VERSION "HIPBNNNYNNNNNNNNNNNNNNNNNNNNNNNNNNYYNNNNNN/4>%%%/4/'%**4NNN///"

NS_ :

BS_:

BU_: ADC BDF BDL BDR BGW CDC DDM VNC Vector_XXX

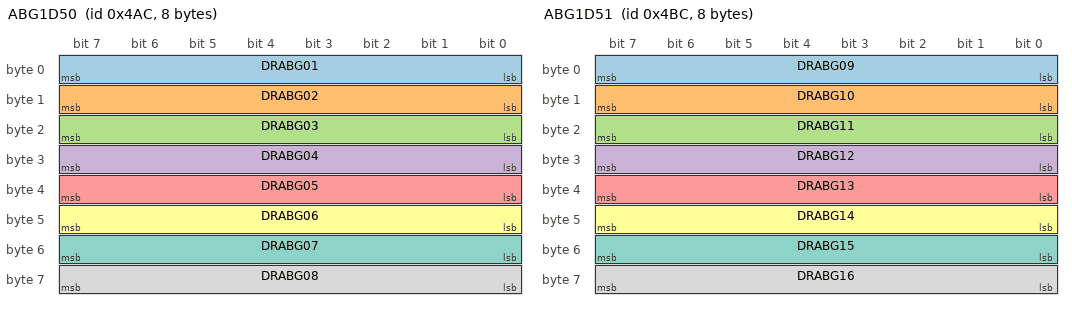
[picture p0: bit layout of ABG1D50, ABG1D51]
BO_ 1196 ABG1D50: 8 DDM
 SG_ DRABG01 : 7|8@0+ (1,0) [0|0] "-"  CDC
 SG_ DRABG02 : 15|8@0+ (1,0) [0|0] "-"  CDC
 SG_ DRABG03 : 23|8@0+ (1,0) [0|0] "-"  CDC
 SG_ DRABG04 : 31|8@0+ (1,0) [0|0] "-"  CDC
 SG_ DRABG05 : 39|8@0+ (1,0) [0|0] "-"  CDC
 SG_ DRABG06 : 47|8@0+ (1,0) [0|0] "-"  CDC
 SG_ DRABG07 : 55|8@0+ (1,0) [0|0] "-"  CDC
 SG_ DRABG08 : 63|8@0+ (1,0) [0|0] "-"  CDC

BO_ 1212 ABG1D51: 8 DDM
 SG_ DRABG09 : 7|8@0+ (1,0) [0|0] "-"  CDC
 SG_ DRABG10 : 15|8@0+ (1,0) [0|0] "-"  CDC
 SG_ DRABG11 : 23|8@0+ (1,0) [0|0] "-"  CDC
 SG_ DRABG12 : 31|8@0+ (1,0) [0|0] "-"  CDC
 SG_ DRABG13 : 39|8@0+ (1,0) [0|0] "-"  CDC
 SG_ DRABG14 : 47|8@0+ (1,0) [0|0] "-"  CDC
 SG_ DRABG15 : 55|8@0+ (1,0) [0|0] "-"  CDC
 SG_ DRABG16 : 63|8@0+ (1,0) [0|0] "-"  CDC

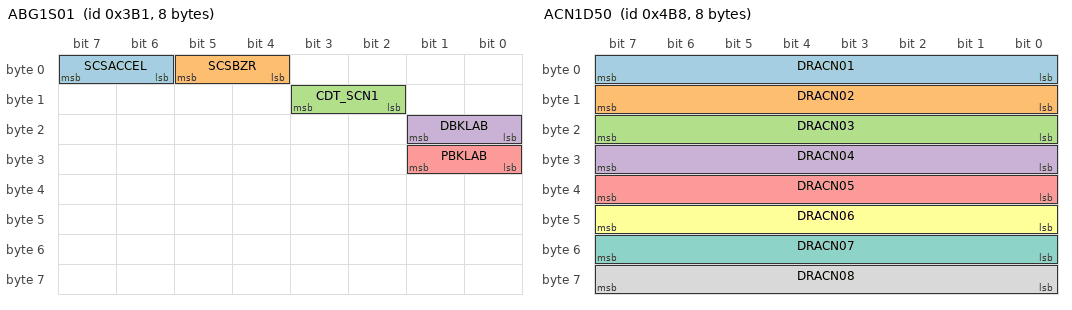
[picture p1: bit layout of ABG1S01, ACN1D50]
BO_ 945 ABG1S01: 8 DDM
 SG_ SCSACCEL : 7|2@0+ (1,0) [0|0] "-"  BDL,BGW,CDC
 SG_ SCSBZR : 5|2@0+ (1,0) [0|0] "-"  BDL,BGW,CDC
 SG_ CDT_SCN1 : 11|2@0+ (1,0) [0|0] "-"  BDL,BGW,CDC
 SG_ DBKLAB : 17|2@0+ (1,0) [0|0] "-"  BDL,BGW,CDC
 SG_ PBKLAB : 25|2@0+ (1,0) [0|0] "-"  BDL,BGW,CDC

BO_ 1208 ACN1D50: 8 BDR
 SG_ DRACN01 : 7|8@0+ (1,0) [0|0] "-"  CDC
 SG_ DRACN02 : 15|8@0+ (1,0) [0|0] "-"  CDC
 SG_ DRACN03 : 23|8@0+ (1,0) [0|0] "-"  CDC
 SG_ DRACN04 : 31|8@0+ (1,0) [0|0] "-"  CDC
 SG_ DRACN05 : 39|8@0+ (1,0) [0|0] "-"  CDC
 SG_ DRACN06 : 47|8@0+ (1,0) [0|0] "-"  CDC
 SG_ DRACN07 : 55|8@0+ (1,0) [0|0] "-"  CDC
 SG_ DRACN08 : 63|8@0+ (1,0) [0|0] "-"  CDC

BO_ 929 ACN1S03: 8 BDR
 SG_ O_STG_F : 31|2@0+ (1,0) [0|0] "-"  BDL,BGW,CDC
 SG_ AC_CDSP : 34|3@0+ (1,0) [0|0] "-"  BDL,BGW,CDC

BO_ 897 ACN1S04: 32 BDR
 SG_ R_ACCALL : 7|1@0+ (1,0) [0|0] "-"  BGW,CDC
 SG_ R_AC_WNG : 6|1@0+ (1,0) [0|0] "-"  BGW,CDC
 SG_ R_SW_CON : 5|1@0+ (1,0) [0|0] "-"  BGW,CDC
 SG_ I_RA_AUT : 3|1@0+ (1,0) [0|0] "-"  BGW,CDC
 SG_ I_RA_AC : 2|1@0+ (1,0) [0|0] "-"  BGW,CDC
 SG_ I_RA_LO : 1|1@0+ (1,0) [0|0] "-"  BGW,CDC
 SG_ I_RA_HI : 0|1@0+ (1,0) [0|0] "-"  BGW,CDC
 SG_ I_AUTO_D : 15|1@0+ (1,0) [0|0] "-"  BGW,CDC
 SG_ I_AUTO_P : 14|1@0+ (1,0) [0|0] "-"  BGW,CDC
 SG_ I_DEF : 13|1@0+ (1,0) [0|0] "-"  BGW,CDC
 SG_ I_RRDEF : 12|1@0+ (1,0) [0|0] "-"  BGW,CDC
 SG_ I_RFAUT : 11|1@0+ (1,0) [0|0] "-"  BGW,CDC
 SG_ I_REC : 10|1@0+ (1,0) [0|0] "-"  BGW,CDC
 SG_ I_FRS : 9|1@0+ (1,0) [0|0] "-"  BGW,CDC
 SG_ I_AC : 8|1@0+ (1,0) [0|0] "-"  BGW,CDC
 SG_ I_MHTR : 23|1@0+ (1,0) [0|0] "-"  BGW,CDC
 SG_ I_WIPD : 22|1@0+ (1,0) [0|0] "-"  BGW,CDC
 SG_ I_DUSY : 21|1@0+ (1,0) [0|0] "-"  BGW,CDC
 SG_ I_SWNG : 20|1@0+ (1,0) [0|0] "-"  BGW,CDC
 SG_ I_BLW_F : 19|4@0+ (1,0) [0|0] "-"  BGW,CDC
 SG_ I_OAUT_D : 31|1@0+ (1,0) [0|0] "-"  BGW,CDC
 SG_ I_OLET_D : 30|3@0+ (1,0) [0|0] "-"  BGW,CDC
 SG_ I_OAUT_P : 27|1@0+ (1,0) [0|0] "-"  BGW,CDC
 SG_ I_OLET_P : 26|3@0+ (1,0) [0|0] "-"  BGW,CDC
 SG_ ST_BMN_F : 39|1@0+ (1,0) [0|0] "-"  BGW,CDC
 SG_ I_CONCEN : 38|1@0+ (1,0) [0|0] "-"  BGW,CDC
 SG_ I_NANOE : 37|1@0+ (1,0) [0|0] "-"  BGW,CDC
 SG_ I_CONCIE : 35|1@0+ (1,0) [0|0] "-"  BGW,CDC
 SG_ I_BLWCUS : 34|3@0+ (1,0) [0|0] "-"  BGW,CDC
 SG_ I_AIRPR : 47|1@0+ (1,0) [0|0] "-"  BGW,CDC
 SG_ I_PLSM : 45|2@0+ (1,0) [0|0] "-"  BGW,CDC
 SG_ I_KAFUN : 43|1@0+ (1,0) [0|0] "-"  BGW,CDC
 SG_ R_ONSCRN : 40|1@0+ (1,0) [0|0] "-"  BGW,CDC
 SG_ I_OLET_I : 55|2@0+ (1,0) [0|0] "-"  BGW,CDC
 SG_ I_PLSYNC : 63|3@0+ (1,0) [0|0] "-"  BGW,CDC
 SG_ I_RFAUTT : 60|1@0+ (1,0) [0|0] "-"  BGW,CDC
 SG_ R_SFLOWS : 59|2@0+ (1,0) [0|0] "-"  BGW,CDC
 SG_ I_ACAUTO : 57|1@0+ (1,0) [0|0] "-"  BGW,CDC
 SG_ R_ECODSP : 56|1@0+ (1,0) [0|0] "-"  BGW,CDC
 SG_ SL_ACDSP : 71|4@0+ (1,0) [0|0] "-"  BGW,CDC
 SG_ SL_DUSY : 67|1@0+ (1,0) [0|0] "-"  BGW,CDC
 SG_ SL_DFRAD : 66|1@0+ (1,0) [0|0] "-"  BGW,CDC
 SG_ SL_CIF : 65|1@0+ (1,0) [0|0] "-"  BGW,CDC
 SG_ SL_BLW_F : 64|1@0+ (1,0) [0|0] "-"  BGW,CDC
 SG_ SL_SRLVL : 79|3@0+ (1,0) [0|0] "-"  BGW,CDC
 SG_ SL_RR_IH : 76|1@0+ (1,0) [0|0] "-"  BGW,CDC
 SG_ SL_RAUTO : 75|1@0+ (1,0) [0|0] "-"  BGW,CDC
 SG_ SL_BLW_R : 74|1@0+ (1,0) [0|0] "-"  BGW,CDC
 SG_ SL_DST : 73|2@0+ (1,0) [0|0] "-"  BGW,CDC
 SG_ SL_WIPD : 87|1@0+ (1,0) [0|0] "-"  BGW,CDC
 SG_ SL_MRHT : 86|1@0+ (1,0) [0|0] "-"  BGW,CDC
 SG_ SL_AIRP : 85|1@0+ (1,0) [0|0] "-"  BGW,CDC
 SG_ SL_PFRAD : 84|1@0+ (1,0) [0|0] "-"  BGW,CDC
 SG_ SL_PLSM : 83|1@0+ (1,0) [0|0] "-"  BGW,CDC
 SG_ SL_KAFUN : 82|1@0+ (1,0) [0|0] "-"  BGW,CDC
 SG_ SL_SWNG : 81|1@0+ (1,0) [0|0] "-"  BGW,CDC
 SG_ ST_CN_OK : 80|1@0+ (1,0) [0|0] "-"  BGW,CDC
 SG_ SL_FSVTP : 95|2@0+ (1,0) [0|0] "-"  BGW,CDC
 SG_ SL_FSTYP : 93|3@0+ (1,0) [0|0] "-"  BGW,CDC
 SG_ SL_NANOE : 90|1@0+ (1,0) [0|0] "-"  BGW,CDC
 SG_ SL_RSEAT : 89|1@0+ (1,0) [0|0] "-"  BGW,CDC
 SG_ SL_SFLOW : 88|1@0+ (1,0) [0|0] "-"  BGW,CDC
 SG_ SL_ACST : 103|6@0+ (1,0) [0|0] "-"  BGW,CDC
 SG_ SL_AC_AM : 97|1@0+ (1,0) [0|0] "-"  BGW,CDC
 SG_ SL_RBLW : 96|1@0+ (1,0) [0|0] "-"  BGW,CDC
 SG_ SL_ROFF : 111|1@0+ (1,0) [0|0] "-"  BGW,CDC
 SG_ SL_BLCUS : 110|1@0+ (1,0) [0|0] "-"  BGW,CDC
 SG_ SL_ACECO : 108|1@0+ (1,0) [0|0] "-"  BGW,CDC
 SG_ SL_RFSW : 107|1@0+ (1,0) [0|0] "-"  BGW,CDC
 SG_ SL_CONCI : 106|1@0+ (1,0) [0|0] "-"  BGW,CDC
 SG_ SL_NECK : 105|1@0+ (1,0) [0|0] "-"  BGW,CDC
 SG_ SL_RACIH : 104|1@0+ (1,0) [0|0] "-"  BGW,CDC
 SG_ SL_ZOSY : 119|3@0+ (1,0) [0|0] "-"  BGW,CDC
 SG_ SL_STHAT : 116|1@0+ (1,0) [0|0] "-"  BGW,CDC
 SG_ SL_3RD_S : 115|1@0+ (1,0) [0|0] "-"  BGW,CDC
 SG_ SL_RSBLW : 114|1@0+ (1,0) [0|0] "-"  BGW,CDC
 SG_ SL_STR_H : 113|2@0+ (1,0) [0|0] "-"  BGW,CDC
 SG_ SL_NAVI : 127|1@0+ (1,0) [0|0] "-"  BGW,CDC
 SG_ SL_FSEAT : 125|2@0+ (1,0) [0|0] "-"  BGW,CDC
 SG_ I_AUT_RR : 135|1@0+ (1,0) [0|0] "-"  BGW,CDC
 SG_ I_AUT_RL : 134|1@0+ (1,0) [0|0] "-"  BGW,CDC
 SG_ I_CNT_IH : 133|1@0+ (1,0) [0|0] "-"  BGW,CDC
 SG_ I_RAUTO : 132|1@0+ (1,0) [0|0] "-"  BGW,CDC
 SG_ ST_BMN_R : 131|1@0+ (1,0) [0|0] "-"  BGW,CDC
 SG_ I_RBLCUS : 130|3@0+ (1,0) [0|0] "-"  BGW,CDC
 SG_ I_OAUTRL : 141|1@0+ (1,0) [0|0] "-"  BGW,CDC
 SG_ I_OAUTRR : 140|1@0+ (1,0) [0|0] "-"  BGW,CDC
 SG_ I_BLW_R : 139|4@0+ (1,0) [0|0] "-"  BGW,CDC
 SG_ R_RONSCR : 151|1@0+ (1,0) [0|0] "-"  BGW,CDC
 SG_ I_OLT_RR : 150|3@0+ (1,0) [0|0] "-"  BGW,CDC
 SG_ I_RACON : 147|1@0+ (1,0) [0|0] "-"  BGW,CDC
 SG_ I_OLT_RL : 146|3@0+ (1,0) [0|0] "-"  BGW,CDC
 SG_ B_DCMOD1 : 175|1@0+ (1,0) [0|0] "-"  BGW,CDC
 SG_ B_DCMOD2 : 174|3@0+ (1,0) [0|0] "-"  BGW,CDC
 SG_ B_DCMOD3 : 171|4@0+ (1,0) [0|0] "-"  BGW,CDC
 SG_ I_TMP_RR : 183|8@0+ (1,0) [0|0] "-"  BGW,CDC
 SG_ I_TMP_RL : 191|8@0+ (1,0) [0|0] "-"  BGW,CDC
 SG_ I_BCOLRL : 199|2@0+ (1,0) [0|0] "-"  BGW,CDC
 SG_ I_BCOLRR : 197|2@0+ (1,0) [0|0] "-"  BGW,CDC
 SG_ I_BCOLPA : 195|2@0+ (1,0) [0|0] "-"  BGW,CDC
 SG_ I_BCOLDR : 193|2@0+ (1,0) [0|0] "-"  BGW,CDC
 SG_ M_OLT_PA : 205|3@0+ (1,0) [0|0] "-"  BGW,CDC
 SG_ M_OLT_DR : 202|3@0+ (1,0) [0|0] "-"  BGW,CDC
 SG_ M_OLT_RL : 213|3@0+ (1,0) [0|0] "-"  BGW,CDC
 SG_ M_OLT_RR : 210|3@0+ (1,0) [0|0] "-"  BGW,CDC
 SG_ RL_SBL : 223|2@0+ (1,0) [0|0] "-"  BGW,CDC
 SG_ RL_SHL : 221|2@0+ (1,0) [0|0] "-"  BGW,CDC
 SG_ RR_SBL : 219|2@0+ (1,0) [0|0] "-"  BGW,CDC
 SG_ RR_SHL : 217|2@0+ (1,0) [0|0] "-"  BGW,CDC
 SG_ I_STHLVL : 231|2@0+ (1,0) [0|0] "-"  BGW,CDC
 SG_ I_SAUTRL : 229|1@0+ (1,0) [0|0] "-"  BGW,CDC
 SG_ I_SAUTRR : 228|1@0+ (1,0) [0|0] "-"  BGW,CDC
 SG_ R_DSP_SH : 227|1@0+ (1,0) [0|0] "-"  BGW,CDC
 SG_ I_SAUT_P : 226|1@0+ (1,0) [0|0] "-"  BGW,CDC
 SG_ I_SAUT_D : 225|1@0+ (1,0) [0|0] "-"  BGW,CDC
 SG_ I_STHAUT : 224|1@0+ (1,0) [0|0] "-"  BGW,CDC
 SG_ PF_SBL : 239|2@0+ (1,0) [0|0] "-"  BGW,CDC
 SG_ PF_SHL : 237|2@0+ (1,0) [0|0] "-"  BGW,CDC
 SG_ DF_SBL : 235|2@0+ (1,0) [0|0] "-"  BGW,CDC
 SG_ DF_SHL : 233|2@0+ (1,0) [0|0] "-"  BGW,CDC
 SG_ DF_NHL : 247|3@0+ (1,0) [0|0] "-"  BGW,CDC
 SG_ PF_NHL : 244|3@0+ (1,0) [0|0] "-"  BGW,CDC
 SG_ I_NH_LIM : 241|2@0+ (1,0) [0|0] "-"  BGW,CDC
 SG_ I_NAUT_D : 255|2@0+ (1,0) [0|0] "-"  BGW,CDC
 SG_ I_NAUT_P : 253|2@0+ (1,0) [0|0] "-"  BGW,CDC

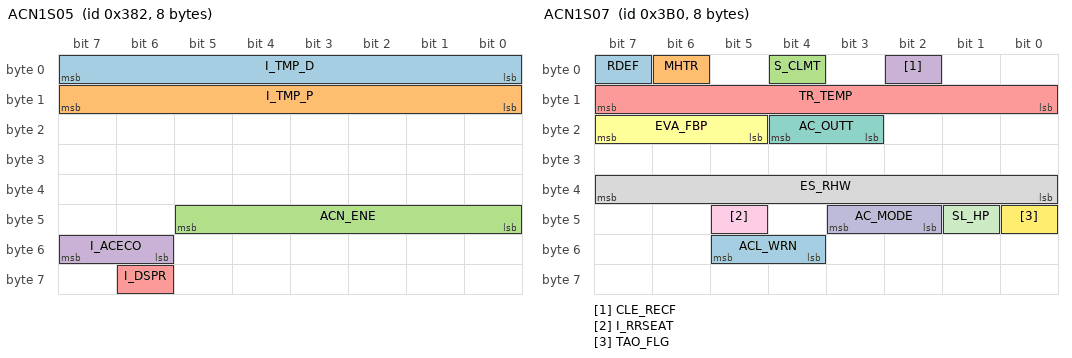
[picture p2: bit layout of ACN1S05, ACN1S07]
BO_ 898 ACN1S05: 8 BDR
 SG_ I_TMP_D : 7|8@0+ (1,0) [0|0] "-"  BGW,CDC
 SG_ I_TMP_P : 15|8@0+ (1,0) [0|0] "-"  BGW,CDC
 SG_ ACN_ENE : 45|6@0+ (100,0) [0|0] "W"  BGW,CDC
 SG_ I_ACECO : 55|2@0+ (1,0) [0|0] "-"  BGW,CDC
 SG_ I_DSPR : 62|1@0+ (1,0) [0|0] "-"  BGW,CDC

BO_ 944 ACN1S07: 8 BDR
 SG_ RDEF : 7|1@0+ (1,0) [0|0] "-"  BGW,CDC
 SG_ MHTR : 6|1@0+ (1,0) [0|0] "-"  BGW,CDC
 SG_ S_CLMT : 4|1@0+ (1,0) [0|0] "-"  BGW,CDC
 SG_ CLE_RECF : 2|1@0+ (1,0) [0|0] "-"  BGW,CDC
 SG_ TR_TEMP : 15|8@0+ (0.25,-6.5) [0|0] "degC"  BGW,CDC
 SG_ EVA_FBP : 23|3@0+ (1,0) [0|0] "-"  BGW,CDC
 SG_ AC_OUTT : 20|2@0+ (1,0) [0|0] "-"  BGW,CDC
 SG_ ES_RHW : 39|8@0+ (1,0) [0|0] "%"  BGW,CDC
 SG_ I_RRSEAT : 45|1@0+ (1,0) [0|0] "-"  BGW,CDC
 SG_ AC_MODE : 43|2@0+ (1,0) [0|0] "-"  BGW,CDC
 SG_ SL_HP : 41|1@0+ (1,0) [0|0] "-"  BGW,CDC
 SG_ TAO_FLG : 40|1@0+ (1,0) [0|0] "-"  BGW,CDC
 SG_ ACL_WRN : 53|2@0+ (1,0) [0|0] "-"  BGW,CDC

BO_ 1031 ACN1S15: 8 BDR
 SG_ TRTEMP_P : 23|8@0+ (0.25,-6.5) [0|0] "degC"  CDC
 SG_ I_BLWF_P : 39|4@0+ (1,0) [0|0] "-"  CDC,DDM

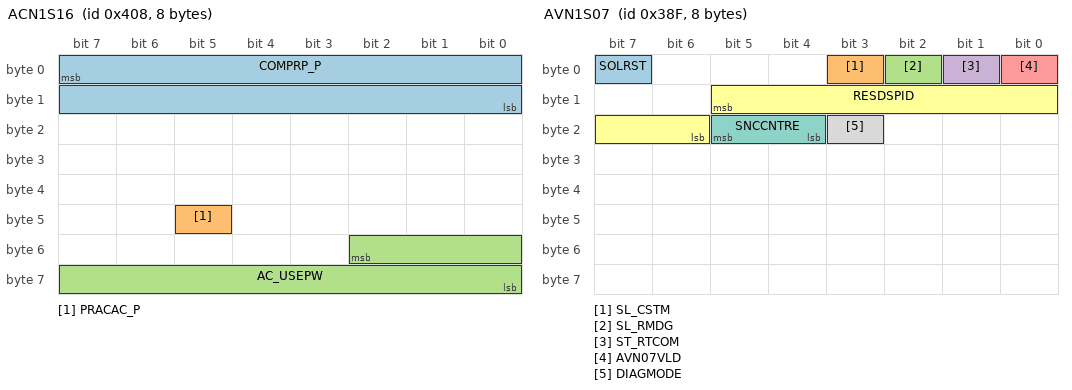
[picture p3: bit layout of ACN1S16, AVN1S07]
BO_ 1032 ACN1S16: 8 BDR
 SG_ COMPRP_P : 7|16@0+ (1,0) [0|0] "rpm"  CDC
 SG_ PRACAC_P : 45|1@0+ (1,0) [0|0] "-"  CDC
 SG_ AC_USEPW : 50|11@0+ (10,0) [0|0] "W"  CDC

BO_ 852 ACN1S22: 32 BDR
 SG_ I_EXT : 7|1@0+ (1,0) [0|0] "-"  BGW,CDC
 SG_ PM_REN : 6|1@0+ (1,0) [0|0] "-"  BGW,CDC
 SG_ PM_ST : 5|2@0+ (1,0) [0|0] "-"  BGW,CDC
 SG_ I_PM : 3|1@0+ (1,0) [0|0] "-"  BGW,CDC
 SG_ SL_PM : 2|1@0+ (1,0) [0|0] "-"  BGW,CDC
 SG_ I_PMD : 1|10@0+ (1,0) [0|0] "ug/m3"  BGW,CDC
 SG_ I_FRC2 : 23|4@0+ (1,0) [0|0] "-"  BGW,CDC
 SG_ I_FRC1 : 19|4@0+ (1,0) [0|0] "-"  BGW,CDC
 SG_ I_RFRS : 31|2@0+ (1,0) [0|0] "-"  BGW,CDC
 SG_ I_WFRS : 29|2@0+ (1,0) [0|0] "-"  BGW,CDC
 SG_ I_FRIS : 27|2@0+ (1,0) [0|0] "-"  BGW,CDC
 SG_ SL_FR : 25|2@0+ (1,0) [0|0] "-"  BGW,CDC
 SG_ ST_ACAGT : 39|3@0+ (1,0) [0|0] "-"  BGW,CDC
 SG_ I_FRST : 36|1@0+ (1,0) [0|0] "-"  BGW,CDC
 SG_ I_RFRC : 35|2@0+ (1,0) [0|0] "-"  BGW,CDC
 SG_ I_WFRC : 33|2@0+ (1,0) [0|0] "-"  BGW,CDC
 SG_ SL_TCS : 47|1@0+ (1,0) [0|0] "-"  BGW,CDC
 SG_ SL_EXT : 46|1@0+ (1,0) [0|0] "-"  BGW,CDC
 SG_ SL_ACAGT : 45|2@0+ (1,0) [0|0] "-"  BGW,CDC
 SG_ ST_EMEN : 43|2@0+ (1,0) [0|0] "-"  BGW,CDC
 SG_ ST_AWKEN : 41|2@0+ (1,0) [0|0] "-"  BGW,CDC
 SG_ SL_RSTYP : 55|3@0+ (1,0) [0|0] "-"  BGW,CDC
 SG_ SL_SYNC : 52|2@0+ (1,0) [0|0] "-"  BGW,CDC
 SG_ TCS_ST : 50|3@0+ (1,0) [0|0] "-"  BGW,CDC
 SG_ R_RFPHBT : 58|1@0+ (1,0) [0|0] "-"  BGW,CDC
 SG_ SL_RSVTP : 57|2@0+ (1,0) [0|0] "-"  BGW,CDC
 SG_ FG_CH1_L : 71|7@0+ (1,0) [0|0] "-"  BGW,CDC
 SG_ FG_CH1_D : 64|1@0+ (1,0) [0|0] "-"  BGW,CDC
 SG_ FG_CH1_T : 78|7@0+ (1,0) [0|0] "-"  BGW,CDC
 SG_ FG_CH2_L : 87|7@0+ (1,0) [0|0] "-"  BGW,CDC
 SG_ FG_CH2_D : 80|1@0+ (1,0) [0|0] "-"  BGW,CDC
 SG_ FG_CH2_T : 94|7@0+ (1,0) [0|0] "-"  BGW,CDC
 SG_ FG_CH3_L : 103|7@0+ (1,0) [0|0] "-"  BGW,CDC
 SG_ FG_CH3_D : 96|1@0+ (1,0) [0|0] "-"  BGW,CDC
 SG_ FG_CH3_T : 110|7@0+ (1,0) [0|0] "-"  BGW,CDC
 SG_ FG_UV_E : 118|1@0+ (1,0) [0|0] "-"  BGW,CDC
 SG_ FG_OV_E : 117|1@0+ (1,0) [0|0] "-"  BGW,CDC
 SG_ FG_MOT_E : 116|1@0+ (1,0) [0|0] "-"  BGW,CDC
 SG_ FG_FAN_E : 115|1@0+ (1,0) [0|0] "-"  BGW,CDC
 SG_ FG_EMP : 114|1@0+ (1,0) [0|0] "-"  BGW,CDC
 SG_ FG_CHA_E : 113|2@0+ (1,0) [0|0] "-"  BGW,CDC
 SG_ SL_FGST : 127|2@0+ (1,0) [0|0] "-"  BGW,CDC
 SG_ I_FG_PW : 125|1@0+ (1,0) [0|0] "-"  BGW,CDC
 SG_ I_FG_LVL : 124|3@0+ (1,0) [0|0] "-"  BGW,CDC
 SG_ I_FG_CH : 121|2@0+ (1,0) [0|0] "-"  BGW,CDC

BO_ 597 ACN1S25: 32 BDR
 SG_ HQ_COMP : 66|11@0+ (10,0) [0|0] "W"  CDC

BO_ 1286 ACN1S29: 32 BDR
 SG_ R_SHHTFL : 3|1@0+ (1,0) [0|0] "-"  CDC
 SG_ R_SHHTFR : 1|1@0+ (1,0) [0|0] "-"  CDC
 SG_ RSVFLDU : 22|7@0+ (1,0) [0|0] "%"  CDC
 SG_ RSVFRDU : 30|7@0+ (1,0) [0|0] "%"  CDC
 SG_ R_SHHTRL : 37|1@0+ (1,0) [0|0] "-"  CDC
 SG_ R_SHHTRR : 35|1@0+ (1,0) [0|0] "-"  CDC
 SG_ RSVRLDU : 54|7@0+ (1,0) [0|0] "%"  CDC
 SG_ RSVRRDU : 62|7@0+ (1,0) [0|0] "%"  CDC
 SG_ R_RDHRR : 70|1@0+ (1,0) [0|0] "-"  CDC
 SG_ R_RDHRL : 68|1@0+ (1,0) [0|0] "-"  CDC
 SG_ R_RDHFP : 66|1@0+ (1,0) [0|0] "-"  CDC
 SG_ R_RDHFD : 64|1@0+ (1,0) [0|0] "-"  CDC

BO_ 382 ADC1S11: 32 ADC
 SG_ RCPSYS : 2|1@0+ (1,0) [0|0] "-"  BGW,CDC

BO_ 519 ADC1S13: 32 ADC
 SG_ VCDSP_2 : 7|2@0+ (1,0) [0|0] "-"  CDC
 SG_ PCDSP_2 : 5|2@0+ (1,0) [0|0] "-"  CDC
 SG_ GCDSP_2 : 3|2@0+ (1,0) [0|0] "-"  CDC
 SG_ TRNEXIST : 1|1@0+ (1,0) [0|0] "-"  CDC
 SG_ TRNACT : 0|2@0+ (1,0) [0|0] "-"  CDC
 SG_ TRNCEO : 14|9@0+ (1,0) [0|0] "-"  CDC
 SG_ TRNED : 21|9@0+ (1,0) [0|0] "-"  CDC
 SG_ TRNEPR : 39|8@0+ (1,0) [0|0] "-"  CDC
 SG_ TRNPEPL : 47|8@0+ (1,0) [0|0] "-"  CDC
 SG_ TRNJ : 55|4@0+ (1,0) [0|0] "-"  CDC
 SG_ TRNCS : 51|1@0+ (1,0) [0|0] "-"  CDC
 SG_ TRNCN : 50|2@0+ (1,0) [0|0] "-"  CDC
 SG_ TRNCI : 48|1@0+ (1,0) [0|0] "-"  CDC
 SG_ TRNPB : 63|7@0+ (1,0) [0|0] "-"  CDC
 SG_ TRNGJ : 56|6@0+ (1,0) [0|0] "-"  CDC
 SG_ TRNME : 66|7@0+ (1,0) [0|0] "-"  CDC
 SG_ TRNMI : 75|4@0+ (1,0) [0|0] "-"  CDC
 SG_ TRNDP : 87|2@0+ (1,0) [0|0] "-"  CDC
 SG_ TRNMET1 : 85|4@0+ (1,0) [0|0] "-"  CDC
 SG_ TRNMET2 : 81|4@0+ (1,0) [0|0] "-"  CDC
 SG_ TRNJP : 93|4@0+ (1,0) [0|0] "-"  CDC
 SG_ TRNVUR : 103|8@0+ (1,0) [0|0] "-"  CDC
 SG_ TRNJPE : 111|4@0+ (1,0) [0|0] "-"  CDC
 SG_ TRNMMDIS : 107|4@0+ (1,0) [0|0] "-"  CDC
 SG_ TRNBUT : 119|1@0+ (1,0) [0|0] "-"  CDC
 SG_ TRNVUEX : 118|1@0+ (1,0) [0|0] "-"  CDC
 SG_ TRNAS : 135|4@0+ (1,0) [0|0] "-"  CDC
 SG_ TRNCI1 : 168|4@0+ (1,0) [0|0] "-"  CDC
 SG_ TRNFE : 189|1@0+ (1,0) [0|0] "-"  CDC
 SG_ TRNSEI : 188|2@0+ (1,0) [0|0] "-"  CDC
 SG_ TRNPC1 : 186|1@0+ (1,0) [0|0] "-"  CDC
 SG_ TRNPC2 : 185|1@0+ (1,0) [0|0] "-"  CDC
 SG_ TRNPC3 : 184|1@0+ (1,0) [0|0] "-"  CDC
 SG_ TRNPC4 : 199|1@0+ (1,0) [0|0] "-"  CDC
 SG_ TRNPC5 : 198|1@0+ (1,0) [0|0] "-"  CDC
 SG_ TRNPC6 : 197|1@0+ (1,0) [0|0] "-"  CDC
 SG_ TRNPC7 : 196|1@0+ (1,0) [0|0] "-"  CDC
 SG_ TRNPC8 : 195|1@0+ (1,0) [0|0] "-"  CDC
 SG_ TRNSE1 : 194|1@0+ (1,0) [0|0] "-"  CDC
 SG_ TRNSE2 : 193|1@0+ (1,0) [0|0] "-"  CDC
 SG_ TRNSE3 : 192|1@0+ (1,0) [0|0] "-"  CDC
 SG_ TRNSE4 : 207|1@0+ (1,0) [0|0] "-"  CDC
 SG_ TRNSE5 : 206|1@0+ (1,0) [0|0] "-"  CDC
 SG_ TRNSE6 : 205|1@0+ (1,0) [0|0] "-"  CDC
 SG_ TRNSE7 : 204|1@0+ (1,0) [0|0] "-"  CDC
 SG_ TRNSE8 : 203|1@0+ (1,0) [0|0] "-"  CDC
 SG_ TRNISR : 202|1@0+ (1,0) [0|0] "-"  CDC
 SG_ TRNESR : 201|1@0+ (1,0) [0|0] "-"  CDC
 SG_ TRNHDR : 200|1@0+ (1,0) [0|0] "-"  CDC
 SG_ TRNMR1 : 215|4@0+ (1,0) [0|0] "-"  CDC
 SG_ TRNMR2 : 211|4@0+ (1,0) [0|0] "-"  CDC

BO_ 523 ADC1S23: 32 ADC
 SG_ AMCONPVM : 7|2@0+ (1,0) [0|0] "-"  CDC
 SG_ DRADCABN : 15|8@0+ (1,0) [0|0] "-"  CDC
 SG_ DRADCTMP : 21|1@0+ (1,0) [0|0] "-"  CDC

BO_ 841 ADC1S30: 8 ADC
 SG_ ETHWU_12 : 6|1@0+ (1,0) [0|0] "-"  BGW,CDC

BO_ 448 ADC1S31: 32 ADC
 SG_ APPMD2 : 2|3@0+ (1,0) [0|0] "-"  CDC

BO_ 526 ADU1S07: 32 ADC
 SG_ DIS_ALR2 : 7|1@0+ (1,0) [0|0] "-"  CDC
 SG_ DISSUIEX : 6|1@0+ (1,0) [0|0] "-"  CDC
 SG_ DISSUIST : 5|1@0+ (1,0) [0|0] "-"  CDC
 SG_ SW_ALRT2 : 4|2@0+ (1,0) [0|0] "-"  CDC
 SG_ PLANTREQ : 2|2@0+ (1,0) [0|0] "-"  CDC
 SG_ ADOFFM1 : 15|4@0+ (1,0) [0|0] "-"  CDC
 SG_ ADOFFM2 : 11|3@0+ (1,0) [0|0] "-"  CDC
 SG_ ADOFFMET : 8|1@0+ (1,0) [0|0] "-"  CDC
 SG_ SCBOICN : 23|1@0+ (1,0) [0|0] "-"  CDC
 SG_ RCDOICN : 22|1@0+ (1,0) [0|0] "-"  CDC
 SG_ RCTAOICN : 21|1@0+ (1,0) [0|0] "-"  CDC
 SG_ SEAOICN : 20|1@0+ (1,0) [0|0] "-"  CDC
 SG_ FCTAOICN : 19|1@0+ (1,0) [0|0] "-"  CDC
 SG_ SASOICN : 18|1@0+ (1,0) [0|0] "-"  CDC
 SG_ EDSSOICN : 17|1@0+ (1,0) [0|0] "-"  CDC
 SG_ RSL_PLRQ : 31|1@0+ (1,0) [0|0] "-"  CDC
 SG_ RSR_PLRQ : 30|1@0+ (1,0) [0|0] "-"  CDC
 SG_ FSL_PLRQ : 29|1@0+ (1,0) [0|0] "-"  CDC
 SG_ FSR_PLRQ : 28|1@0+ (1,0) [0|0] "-"  CDC
 SG_ FRD_PLRQ : 27|1@0+ (1,0) [0|0] "-"  CDC
 SG_ ADISTATE : 26|3@0+ (1,0) [0|0] "-"  CDC
 SG_ SEAADIM : 39|2@0+ (1,0) [0|0] "-"  CDC
 SG_ PMARADIM : 37|2@0+ (1,0) [0|0] "-"  CDC
 SG_ RCTAADIM : 35|2@0+ (1,0) [0|0] "-"  CDC
 SG_ BSMADIM : 33|2@0+ (1,0) [0|0] "-"  CDC
 SG_ ADIEXIST : 47|1@0+ (1,0) [0|0] "-"  CDC
 SG_ FSR_BZ_C : 43|1@0+ (1,0) [0|0] "-"  CDC
 SG_ FSR_BZ_E : 42|1@0+ (1,0) [0|0] "-"  CDC
 SG_ FSL_BZ_C : 41|1@0+ (1,0) [0|0] "-"  CDC
 SG_ FSL_BZ_E : 40|1@0+ (1,0) [0|0] "-"  CDC
 SG_ RSR_BZ_C : 55|1@0+ (1,0) [0|0] "-"  CDC
 SG_ RSR_BZ_E : 54|1@0+ (1,0) [0|0] "-"  CDC
 SG_ RSL_BZ_C : 53|1@0+ (1,0) [0|0] "-"  CDC
 SG_ RSL_BZ_E : 52|1@0+ (1,0) [0|0] "-"  CDC
 SG_ DMCINDI : 51|3@0+ (1,0) [0|0] "-"  CDC
 SG_ DMCDISP : 63|6@0+ (1,0) [0|0] "-"  CDC
 SG_ DMCBZRQ : 57|2@0+ (1,0) [0|0] "-"  CDC
 SG_ ACCAVTYR : 79|3@0+ (1,0) [0|0] "-"  CDC
 SG_ ACCAVDTR : 76|3@0+ (1,0) [0|0] "-"  CDC
 SG_ ACCAVS1R : 73|2@0+ (1,0) [0|0] "-"  CDC
 SG_ ACCAVS2R : 87|1@0+ (1,0) [0|0] "-"  CDC
 SG_ ACCAVLPR : 86|3@0+ (1,0) [0|0] "-"  CDC
 SG_ ACCAVTYL : 83|3@0+ (1,0) [0|0] "-"  CDC
 SG_ ACCAVS2L : 80|1@0+ (1,0) [0|0] "-"  CDC
 SG_ ACCAVS1L : 95|2@0+ (1,0) [0|0] "-"  CDC
 SG_ ACCAVDTL : 93|3@0+ (1,0) [0|0] "-"  CDC
 SG_ ACCAVLPL : 90|3@0+ (1,0) [0|0] "-"  CDC
 SG_ ACCPPVEX : 103|1@0+ (1,0) [0|0] "-"  CDC
 SG_ ACCPPVDT : 102|3@0+ (1,0) [0|0] "-"  CDC
 SG_ ACCPPVS1 : 99|2@0+ (1,0) [0|0] "-"  CDC
 SG_ ACCPVTY : 111|3@0+ (1,0) [0|0] "-"  CDC
 SG_ ACCPVDST : 108|3@0+ (1,0) [0|0] "-"  CDC
 SG_ ACCPVST1 : 105|2@0+ (1,0) [0|0] "-"  CDC
 SG_ ACCPVST2 : 119|1@0+ (1,0) [0|0] "-"  CDC
 SG_ ACCPVST3 : 118|1@0+ (1,0) [0|0] "-"  CDC
 SG_ CACCFR1 : 117|1@0+ (1,0) [0|0] "-"  CDC
 SG_ ERMPLRST : 116|2@0+ (1,0) [0|0] "-"  CDC
 SG_ AH_SRI_C : 143|16@0+ (1,0) [0|0] "-"  CDC
 SG_ AH_IND_C : 159|3@0+ (1,0) [0|0] "-"  CDC
 SG_ AH_WTR_C : 156|3@0+ (1,0) [0|0] "-"  CDC
 SG_ BSMOICN : 153|1@0+ (1,0) [0|0] "-"  CDC

BO_ 477 ARS1S90: 8 DDM
 SG_ ARS_METD : 4|3@0+ (1,0) [0|0] "-"  CDC
 SG_ ARSEXT : 8|1@0+ (1,0) [0|0] "-"  CDC

BO_ 900 AVN1S01: 32 CDC
 SG_ RDC : 7|4@0+ (1,0) [0|0] "-"  ADC
 SG_ CONFID01 : 3|2@0+ (1,0) [0|0] "-"  ADC
 SG_ CONF : 1|2@0+ (1,0) [0|0] "-"  ADC
 SG_ LYT : 15|4@0+ (1,0) [0|0] "-"  ADC
 SG_ TNL_5H_S : 11|1@0+ (1,0) [0|0] "-"  Vector_XXX
 SG_ TNL_1T_S : 10|1@0+ (1,0) [0|0] "-"  Vector_XXX
 SG_ DRVW : 9|1@0+ (1,0) [0|0] "-"  ADC
 SG_ MWMP : 8|1@0+ (1,0) [0|0] "-"  ADC
 SG_ GRAD : 23|3@0+ (1,0) [0|0] "-"  Vector_XXX
 SG_ TNL_5T_S : 20|1@0+ (1,0) [0|0] "-"  Vector_XXX
 SG_ BRANCH : 27|4@0+ (1,0) [0|0] "-"  Vector_XXX
 SG_ TOLLGATE : 33|1@0+ (1,0) [0|0] "-"  Vector_XXX
 SG_ TUNL : 32|1@0+ (1,0) [0|0] "-"  ADC,BDL
 SG_ LEAVEOUT : 47|1@0+ (1,0) [0|0] "-"  Vector_XXX
 SG_ MRGLANE : 46|1@0+ (1,0) [0|0] "-"  Vector_XXX
 SG_ LVLANE : 45|1@0+ (1,0) [0|0] "-"  Vector_XXX

BO_ 910 AVN1S04: 8 CDC
 SG_ R_AC_DSP : 7|1@0+ (1,0) [0|0] "-"  BDL
 SG_ AVN04VLD : 5|1@0+ (1,0) [0|0] "-"  BDL
 SG_ S_ACECO : 4|1@0+ (1,0) [0|0] "-"  BDL
 SG_ S_BLW_F : 3|1@0+ (1,0) [0|0] "-"  BDL
 SG_ S_RA_AUT : 2|1@0+ (1,0) [0|0] "-"  BDL
 SG_ S_RA_OFF : 1|1@0+ (1,0) [0|0] "-"  BDL
 SG_ S_RA_MNL : 0|1@0+ (1,0) [0|0] "-"  BDL
 SG_ R_PN_TYP : 15|4@0+ (1,0) [0|0] "-"  BDL
 SG_ R_CONCIE : 11|1@0+ (1,0) [0|0] "-"  BDL
 SG_ S_CONCIE : 10|1@0+ (1,0) [0|0] "-"  BDL
 SG_ R_S_FLOW : 9|1@0+ (1,0) [0|0] "-"  BDL
 SG_ R_RFAT : 8|1@0+ (1,0) [0|0] "-"  BDL
 SG_ S_AUTO_D : 23|1@0+ (1,0) [0|0] "-"  BDL
 SG_ S_AUTO_P : 22|1@0+ (1,0) [0|0] "-"  BDL
 SG_ S_DEF : 21|1@0+ (1,0) [0|0] "-"  BDL
 SG_ S_RRDEF : 20|1@0+ (1,0) [0|0] "-"  BDL
 SG_ S_INL : 19|1@0+ (1,0) [0|0] "-"  BDL
 SG_ S_OFF_F : 18|1@0+ (1,0) [0|0] "-"  BDL
 SG_ S_SAFS : 17|1@0+ (1,0) [0|0] "-"  BDL
 SG_ S_AC : 16|1@0+ (1,0) [0|0] "-"  BDL
 SG_ S_MHTR : 31|1@0+ (1,0) [0|0] "-"  BDL
 SG_ S_WIPD : 30|1@0+ (1,0) [0|0] "-"  BDL
 SG_ S_DUSY : 29|1@0+ (1,0) [0|0] "-"  BDL
 SG_ S_SWNG : 28|1@0+ (1,0) [0|0] "-"  BDL
 SG_ S_MODE_D : 27|1@0+ (1,0) [0|0] "-"  BDL
 SG_ S_MODE_P : 26|1@0+ (1,0) [0|0] "-"  BDL
 SG_ S_BUP_F : 25|1@0+ (1,0) [0|0] "-"  BDL
 SG_ S_BDN_F : 24|1@0+ (1,0) [0|0] "-"  BDL
 SG_ S_NANOE : 39|1@0+ (1,0) [0|0] "-"  BDL
 SG_ S_OLET_D : 38|3@0+ (1,0) [0|0] "-"  BDL
 SG_ S_DSPR : 35|1@0+ (1,0) [0|0] "-"  BDL
 SG_ S_OLET_P : 34|3@0+ (1,0) [0|0] "-"  BDL
 SG_ S_TUP_D : 47|1@0+ (1,0) [0|0] "-"  BDL
 SG_ S_TDN_D : 46|1@0+ (1,0) [0|0] "-"  BDL
 SG_ S_TUP_P : 45|1@0+ (1,0) [0|0] "-"  BDL
 SG_ S_TDN_P : 44|1@0+ (1,0) [0|0] "-"  BDL
 SG_ S_PLSM : 43|1@0+ (1,0) [0|0] "-"  BDL
 SG_ S_KAFUN : 42|1@0+ (1,0) [0|0] "-"  BDL
 SG_ S_AIRPR : 41|1@0+ (1,0) [0|0] "-"  BDL
 SG_ S_O2 : 40|1@0+ (1,0) [0|0] "-"  BDL
 SG_ S_FRS : 55|1@0+ (1,0) [0|0] "-"  BDL
 SG_ S_REC : 54|1@0+ (1,0) [0|0] "-"  BDL
 SG_ S_HUM : 53|1@0+ (1,0) [0|0] "-"  BDL
 SG_ S_CONCEN : 52|1@0+ (1,0) [0|0] "-"  BDL
 SG_ S_IN_RTN : 51|1@0+ (1,0) [0|0] "-"  BDL
 SG_ S_INLVL : 50|3@0+ (1,0) [0|0] "-"  BDL
 SG_ S_BLW7_F : 63|1@0+ (1,0) [0|0] "-"  BDL
 SG_ S_BLW6_F : 62|1@0+ (1,0) [0|0] "-"  BDL
 SG_ S_BLW5_F : 61|1@0+ (1,0) [0|0] "-"  BDL
 SG_ S_BLW4_F : 60|1@0+ (1,0) [0|0] "-"  BDL
 SG_ S_BLW3_F : 59|1@0+ (1,0) [0|0] "-"  BDL
 SG_ S_BLW2_F : 58|1@0+ (1,0) [0|0] "-"  BDL
 SG_ S_BLW1_F : 57|1@0+ (1,0) [0|0] "-"  BDL
 SG_ ST_NAVAC : 56|1@0+ (1,0) [0|0] "-"  BDL

BO_ 903 AVN1S05: 8 CDC
 SG_ S_AUT_RR : 7|1@0+ (1,0) [0|0] "-"  BDL
 SG_ S_AUT_RL : 6|1@0+ (1,0) [0|0] "-"  BDL
 SG_ S_BUP_R : 5|1@0+ (1,0) [0|0] "-"  BDL
 SG_ S_BDN_R : 4|1@0+ (1,0) [0|0] "-"  BDL
 SG_ S_TUP_RR : 3|1@0+ (1,0) [0|0] "-"  BDL
 SG_ S_TDN_RR : 2|1@0+ (1,0) [0|0] "-"  BDL
 SG_ S_TUP_RL : 1|1@0+ (1,0) [0|0] "-"  BDL
 SG_ S_TDN_RL : 0|1@0+ (1,0) [0|0] "-"  BDL
 SG_ ST_FRDSP : 15|1@0+ (1,0) [0|0] "-"  Vector_XXX
 SG_ S_OLT_RR : 14|3@0+ (1,0) [0|0] "-"  BDL
 SG_ S_OLT_RL : 10|3@0+ (1,0) [0|0] "-"  BDL
 SG_ S_MOD_RR : 23|1@0+ (1,0) [0|0] "-"  BDL
 SG_ S_MOD_RL : 22|1@0+ (1,0) [0|0] "-"  BDL
 SG_ S_OFF_R : 21|1@0+ (1,0) [0|0] "-"  BDL
 SG_ S_CNT_IH : 20|1@0+ (1,0) [0|0] "-"  BDL
 SG_ S_RRSEAT : 19|1@0+ (1,0) [0|0] "-"  BDL
 SG_ S_REONOF : 18|1@0+ (1,0) [0|0] "-"  BDL
 SG_ S_SYNC : 17|2@0+ (1,0) [0|0] "-"  BDL
 SG_ S_RAUTO : 31|1@0+ (1,0) [0|0] "-"  BDL
 SG_ S_BLW7_R : 30|1@0+ (1,0) [0|0] "-"  BDL
 SG_ S_BLW6_R : 29|1@0+ (1,0) [0|0] "-"  BDL
 SG_ S_BLW5_R : 28|1@0+ (1,0) [0|0] "-"  BDL
 SG_ S_BLW4_R : 27|1@0+ (1,0) [0|0] "-"  BDL
 SG_ S_BLW3_R : 26|1@0+ (1,0) [0|0] "-"  BDL
 SG_ S_BLW2_R : 25|1@0+ (1,0) [0|0] "-"  BDL
 SG_ S_BLW1_R : 24|1@0+ (1,0) [0|0] "-"  BDL
 SG_ S_TPMDRR : 39|1@0+ (1,0) [0|0] "-"  BDL
 SG_ S_ICDLRR : 38|1@0+ (1,0) [0|0] "-"  BDL
 SG_ S_TPCDRR : 37|6@0+ (1,0) [0|0] "-"  BDL
 SG_ S_TPMDRL : 47|1@0+ (1,0) [0|0] "-"  BDL
 SG_ S_ICDLRL : 46|1@0+ (1,0) [0|0] "-"  BDL
 SG_ S_TPCDRL : 45|6@0+ (1,0) [0|0] "-"  BDL
 SG_ S_TPMD_D : 55|1@0+ (1,0) [0|0] "-"  BDL
 SG_ S_ICDL_D : 54|1@0+ (1,0) [0|0] "-"  BDL
 SG_ S_TPCD_D : 53|6@0+ (1,0) [0|0] "-"  BDL
 SG_ S_TPMD_P : 63|1@0+ (1,0) [0|0] "-"  BDL
 SG_ S_ICDL_P : 62|1@0+ (1,0) [0|0] "-"  BDL
 SG_ S_TPCD_P : 61|6@0+ (1,0) [0|0] "-"  BDL

BO_ 904 AVN1S06: 8 CDC
 SG_ S_DF_SH : 7|1@0+ (1,0) [0|0] "-"  BDL
 SG_ S_PF_SH : 6|1@0+ (1,0) [0|0] "-"  BDL
 SG_ S_RR_SH : 5|1@0+ (1,0) [0|0] "-"  BDL
 SG_ S_RL_SH : 4|1@0+ (1,0) [0|0] "-"  BDL
 SG_ S_DF_SB : 3|1@0+ (1,0) [0|0] "-"  BDL
 SG_ S_PF_SB : 2|1@0+ (1,0) [0|0] "-"  BDL
 SG_ S_RR_SB : 1|1@0+ (1,0) [0|0] "-"  BDL
 SG_ S_RL_SB : 0|1@0+ (1,0) [0|0] "-"  BDL
 SG_ S_DF_SA : 15|1@0+ (1,0) [0|0] "-"  BDL
 SG_ S_PF_SA : 14|1@0+ (1,0) [0|0] "-"  BDL
 SG_ S_RR_SA : 13|1@0+ (1,0) [0|0] "-"  BDL
 SG_ S_RL_SA : 12|1@0+ (1,0) [0|0] "-"  BDL
 SG_ S_NUP_D : 11|1@0+ (1,0) [0|0] "-"  BDL
 SG_ S_NDN_D : 10|1@0+ (1,0) [0|0] "-"  BDL
 SG_ S_NUP_P : 9|1@0+ (1,0) [0|0] "-"  BDL
 SG_ S_NDN_P : 8|1@0+ (1,0) [0|0] "-"  BDL
 SG_ S_STH : 23|1@0+ (1,0) [0|0] "-"  BDL
 SG_ S_STHAUT : 22|1@0+ (1,0) [0|0] "-"  BDL
 SG_ S_STH_UP : 21|1@0+ (1,0) [0|0] "-"  BDL
 SG_ S_STH_DN : 20|1@0+ (1,0) [0|0] "-"  BDL
 SG_ S_DF_NA : 19|1@0+ (1,0) [0|0] "-"  BDL
 SG_ S_PF_NA : 18|1@0+ (1,0) [0|0] "-"  BDL
 SG_ S_NECK_D : 17|1@0+ (1,0) [0|0] "-"  BDL
 SG_ S_NECK_P : 16|1@0+ (1,0) [0|0] "-"  BDL
 SG_ S_HUP_D : 31|1@0+ (1,0) [0|0] "-"  BDL
 SG_ S_HUP_P : 30|1@0+ (1,0) [0|0] "-"  BDL
 SG_ S_HUP_RR : 29|1@0+ (1,0) [0|0] "-"  BDL
 SG_ S_HUP_RL : 28|1@0+ (1,0) [0|0] "-"  BDL
 SG_ S_HDN_D : 27|1@0+ (1,0) [0|0] "-"  BDL
 SG_ S_HDN_P : 26|1@0+ (1,0) [0|0] "-"  BDL
 SG_ S_HDN_RR : 25|1@0+ (1,0) [0|0] "-"  BDL
 SG_ S_HDN_RL : 24|1@0+ (1,0) [0|0] "-"  BDL
 SG_ S_BUP_D : 39|1@0+ (1,0) [0|0] "-"  BDL
 SG_ S_BUP_P : 38|1@0+ (1,0) [0|0] "-"  BDL
 SG_ S_BUP_RR : 37|1@0+ (1,0) [0|0] "-"  BDL
 SG_ S_BUP_RL : 36|1@0+ (1,0) [0|0] "-"  BDL
 SG_ S_BDN_D : 35|1@0+ (1,0) [0|0] "-"  BDL
 SG_ S_BDN_P : 34|1@0+ (1,0) [0|0] "-"  BDL
 SG_ S_BDN_RR : 33|1@0+ (1,0) [0|0] "-"  BDL
 SG_ S_BDN_RL : 32|1@0+ (1,0) [0|0] "-"  BDL

BO_ 911 AVN1S07: 8 CDC
 SG_ SOLRST : 7|1@0+ (1,0) [0|0] "-"  BDL,BGW
 SG_ SL_CSTM : 3|1@0+ (1,0) [0|0] "-"  BDL,BGW
 SG_ SL_RMDG : 2|1@0+ (1,0) [0|0] "-"  BDL,BGW
 SG_ ST_RTCOM : 1|1@0+ (1,0) [0|0] "-"  BDL,BGW
 SG_ AVN07VLD : 0|1@0+ (1,0) [0|0] "-"  BDL,BGW
 SG_ RESDSPID : 13|8@0+ (1,0) [0|0] "-"  BDL,BGW
 SG_ SNCCNTRE : 21|2@0+ (1,0) [0|0] "-"  BDL,BGW
 SG_ DIAGMODE : 19|1@0+ (1,0) [0|0] "-"  BDL,BGW

BO_ 998 AVN1S11: 32 CDC
 SG_ SENSPFM : 7|3@0+ (1,0) [0|0] "-"  ADC,BDL,DDM
 SG_ SENSFAIL : 4|3@0+ (1,0) [0|0] "-"  ADC,BDL,DDM
 SG_ CONFID11 : 1|2@0+ (1,0) [0|0] "-"  ADC,BDL,DDM
 SG_ CONFMMC : 15|8@0+ (1,0) [0|0] "-"  ADC,BDL,DDM
 SG_ DISTERR : 23|8@0+ (1,0) [0|0] "-"  BDL,DDM
 SG_ CONFLANE : 31|8@0+ (1,0) [0|0] "-"  BDL,DDM
 SG_ CONFDIR : 39|8@0+ (1,0) [0|0] "-"  BDL,DDM

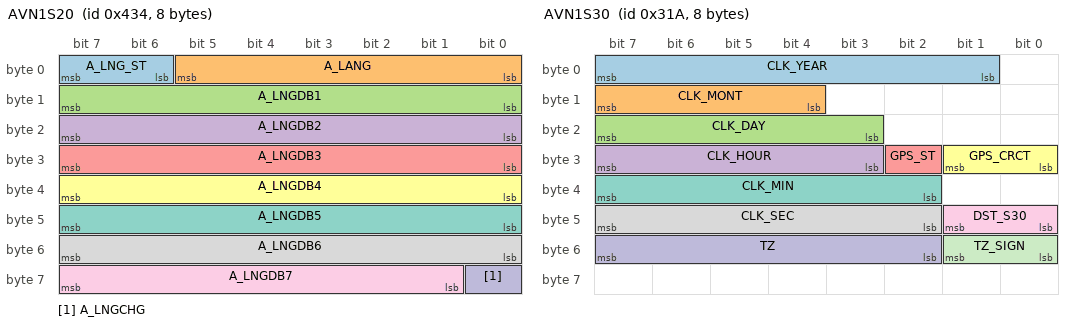
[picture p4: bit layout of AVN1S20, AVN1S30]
BO_ 1076 AVN1S20: 8 CDC
 SG_ A_LNG_ST : 7|2@0+ (1,0) [0|0] "-"  BGW
 SG_ A_LANG : 5|6@0+ (1,0) [0|0] "-"  ADC,BGW
 SG_ A_LNGDB1 : 15|8@0+ (1,0) [0|0] "-"  BGW
 SG_ A_LNGDB2 : 23|8@0+ (1,0) [0|0] "-"  BGW
 SG_ A_LNGDB3 : 31|8@0+ (1,0) [0|0] "-"  BGW
 SG_ A_LNGDB4 : 39|8@0+ (1,0) [0|0] "-"  BGW
 SG_ A_LNGDB5 : 47|8@0+ (1,0) [0|0] "-"  BGW
 SG_ A_LNGDB6 : 55|8@0+ (1,0) [0|0] "-"  BGW
 SG_ A_LNGDB7 : 63|7@0+ (1,0) [0|0] "-"  BGW
 SG_ A_LNGCHG : 56|1@0+ (1,0) [0|0] "-"  BGW

BO_ 1077 AVN1S21: 8 CDC
 SG_ A_OPEN_S : 7|1@0+ (1,0) [0|0] "-"  Vector_XXX
 SG_ OPENCHG : 6|1@0+ (1,0) [0|0] "-"  Vector_XXX
 SG_ CAPSW_S : 5|2@0+ (1,0) [0|0] "-"  Vector_XXX
 SG_ A_CLR_S : 3|4@0+ (1,0) [0|0] "-"  ADC
 SG_ DISP_BRT : 15|8@0+ (1,0) [0|0] "-"  Vector_XXX
 SG_ DISP_CNT : 23|8@0+ (1,0) [0|0] "-"  Vector_XXX
 SG_ A_COP_S : 31|2@0+ (1,0) [0|0] "-"  BDL
 SG_ A_OP_SUP : 29|1@0+ (1,0) [0|0] "-"  BDL
 SG_ DM_PGSW : 28|1@0+ (1,0) [0|0] "-"  ADC
 SG_ FAVSET_R : 39|4@0+ (1,0) [0|0] "-"  Vector_XXX
 SG_ FAVSET_L : 35|4@0+ (1,0) [0|0] "-"  Vector_XXX
 SG_ A_UNTTMP : 45|2@0+ (1,0) [0|0] "-"  Vector_XXX
 SG_ A_UNTSP : 43|2@0+ (1,0) [0|0] "-"  Vector_XXX
 SG_ A_UNTDST : 41|2@0+ (1,0) [0|0] "-"  Vector_XXX
 SG_ A_TMPCHG : 51|1@0+ (1,0) [0|0] "-"  Vector_XXX
 SG_ A_SPCHG : 50|1@0+ (1,0) [0|0] "-"  Vector_XXX
 SG_ A_DSTCHG : 49|1@0+ (1,0) [0|0] "-"  Vector_XXX
 SG_ A_SPLM : 63|6@0+ (5,0) [0|0] "-"  Vector_XXX
 SG_ A_UTSPLM : 57|2@0+ (1,0) [0|0] "-"  Vector_XXX

BO_ 1078 AVN1S22: 8 CDC
 SG_ R1_SWOP : 7|32@0+ (1,0) [0|0] "-"  BDL

BO_ 1079 AVN1S23: 8 CDC
 SG_ R2_SWOP : 7|32@0+ (1,0) [0|0] "-"  BDL

BO_ 794 AVN1S30: 8 CDC
 SG_ CLK_YEAR : 7|7@0+ (1,2000) [0|0] "year"  BDL,BGW,DDM
 SG_ CLK_MONT : 15|4@0+ (1,0) [0|0] "month"  BDL,BGW,DDM
 SG_ CLK_DAY : 23|5@0+ (1,0) [0|0] "day"  BDL,BGW,DDM
 SG_ CLK_HOUR : 31|5@0+ (1,0) [0|0] "hour"  BDL,BGW,DDM
 SG_ GPS_ST : 26|1@0+ (1,0) [0|0] "-"  BDL,BGW,DDM
 SG_ GPS_CRCT : 25|2@0+ (1,0) [0|0] "-"  BDL,BGW,DDM
 SG_ CLK_MIN : 39|6@0+ (1,0) [0|0] "minute"  BDL,BGW,DDM
 SG_ CLK_SEC : 47|6@0+ (1,0) [0|0] "sec"  BDL,BGW,DDM
 SG_ DST_S30 : 41|2@0+ (1,0) [0|0] "-"  BGW,DDM
 SG_ TZ : 55|6@0+ (15,0) [0|0] "minute"  BGW,DDM
 SG_ TZ_SIGN : 49|2@0+ (1,0) [0|0] "-"  BGW,DDM

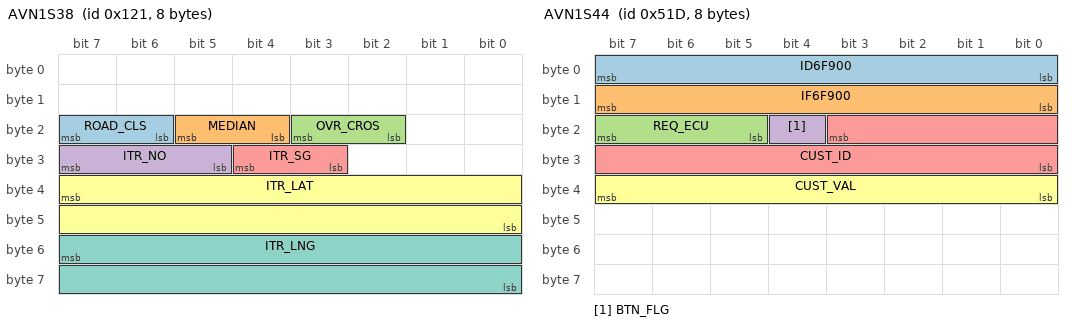
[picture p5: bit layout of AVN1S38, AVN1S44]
BO_ 289 AVN1S38: 8 CDC
 SG_ ROAD_CLS : 23|2@0+ (1,0) [0|0] "-"  BGW
 SG_ MEDIAN : 21|2@0+ (1,0) [0|0] "-"  BGW
 SG_ OVR_CROS : 19|2@0+ (1,0) [0|0] "-"  BGW
 SG_ ITR_NO : 31|3@0+ (1,0) [0|0] "-"  BGW
 SG_ ITR_SG : 28|2@0+ (1,0) [0|0] "-"  BGW
 SG_ ITR_LAT : 39|16@0+ (0.1,0) [0|0] "sec"  BGW
 SG_ ITR_LNG : 55|16@0+ (0.1,0) [0|0] "sec"  BGW

BO_ 1418 AVN1S39: 8 CDC
 SG_ P_DCS : 7|4@0+ (1,0) [0|0] "-"  DDM
 SG_ C_DCS : 3|4@0+ (1,0) [0|0] "-"  DDM
 SG_ AC_DCS : 15|4@0+ (1,0) [0|0] "-"  BDL,BDR,DDM
 SG_ AVN39VLD : 11|4@0+ (1,0) [0|0] "-"  BDL,BDR,DDM
 SG_ C_ST_DCS : 23|4@0+ (1,0) [0|0] "-"  DDM
 SG_ C_SU_DCS : 19|4@0+ (1,0) [0|0] "-"  DDM
 SG_ C_BR_DCS : 31|4@0+ (1,0) [0|0] "-"  DDM
 SG_ DM_AVN_D : 27|1@0+ (1,0) [0|0] "-"  DDM
 SG_ BDR_S_SW : 26|1@0+ (1,0) [0|0] "-"  DDM
 SG_ CRLMD_SW : 34|1@0+ (1,0) [0|0] "-"  DDM
 SG_ CRAWL_M : 33|1@0+ (1,0) [0|0] "-"  DDM
 SG_ CRAWL_P : 32|1@0+ (1,0) [0|0] "-"  DDM
 SG_ BH_SW : 55|1@0+ (1,0) [0|0] "-"  DDM
 SG_ TRCOFFSW : 54|1@0+ (1,0) [0|0] "-"  DDM
 SG_ VSCOFFSW : 53|1@0+ (1,0) [0|0] "-"  DDM
 SG_ EVMD_SW : 52|1@0+ (1,0) [0|0] "-"  DDM
 SG_ NMRBR_SW : 51|1@0+ (1,0) [0|0] "-"  DDM
 SG_ DAC_S_SW : 50|1@0+ (1,0) [0|0] "-"  DDM
 SG_ MMFZ_CNT : 62|3@0+ (1,0) [0|0] "-"  DDM
 SG_ MN_MD_SW : 59|1@0+ (1,0) [0|0] "-"  DDM
 SG_ MS_MD_SW : 58|1@0+ (1,0) [0|0] "-"  DDM
 SG_ RD_MD_SW : 57|1@0+ (1,0) [0|0] "-"  DDM
 SG_ TR_MD_SW : 56|1@0+ (1,0) [0|0] "-"  DDM

BO_ 1309 AVN1S44: 8 CDC
 SG_ ID6F900 : 7|8@0+ (1,0) [0|0] "-"  BDF,BDL
 SG_ IF6F900 : 15|8@0+ (1,0) [0|0] "-"  BDF,BDL
 SG_ REQ_ECU : 23|3@0+ (1,0) [0|0] "-"  BDF,BDL
 SG_ BTN_FLG : 20|1@0+ (1,0) [0|0] "-"  BDF,BDL
 SG_ CUST_ID : 19|12@0+ (1,0) [0|0] "-"  BDF,BDL
 SG_ CUST_VAL : 39|8@0+ (1,0) [0|0] "-"  BDF,BDL

BO_ 445 AVN1S52: 8 CDC
 SG_ DSP_SW : 7|4@0+ (1,0) [0|0] "-"  BDL
 SG_ DSC_SW : 3|3@0+ (1,0) [0|0] "-"  BDL
 SG_ DAL_SW : 0|1@0+ (1,0) [0|0] "-"  Vector_XXX
 SG_ OSC_SW : 15|2@0+ (1,0) [0|0] "-"  BDL
 SG_ DRM_SW : 13|3@0+ (1,0) [0|0] "-"  BDL
 SG_ DRA_SW : 10|2@0+ (1,0) [0|0] "-"  BDL
 SG_ PSP_SW : 23|4@0+ (1,0) [0|0] "-"  BDL
 SG_ PSC_SW : 19|3@0+ (1,0) [0|0] "-"  BDL
 SG_ PAL_SW : 16|1@0+ (1,0) [0|0] "-"  Vector_XXX
 SG_ PRM_SW : 31|3@0+ (1,0) [0|0] "-"  BDL
 SG_ PRA_SW : 28|2@0+ (1,0) [0|0] "-"  BDL
 SG_ DRSF_SW : 26|2@0+ (1,0) [0|0] "-"  BDL
 SG_ D_ES_SW : 24|1@0+ (1,0) [0|0] "-"  BDL
 SG_ PMO_SW : 39|3@0+ (1,0) [0|0] "-"  BDL
 SG_ PRSF_SW : 36|2@0+ (1,0) [0|0] "-"  BDL
 SG_ P_ES_SW : 34|1@0+ (1,0) [0|0] "-"  BDL
 SG_ R_ES_SW : 33|1@0+ (1,0) [0|0] "-"  BDL
 SG_ SSEL_SW : 47|4@0+ (1,0) [0|0] "-"  BDL
 SG_ FO_RE_SW : 43|2@0+ (1,0) [0|0] "-"  BDL
 SG_ WI_RE_SW : 41|2@0+ (1,0) [0|0] "-"  BDL
 SG_ AR_ES_SW : 55|1@0+ (1,0) [0|0] "-"  BDL
 SG_ AFR_SW : 54|2@0+ (1,0) [0|0] "-"  BDL

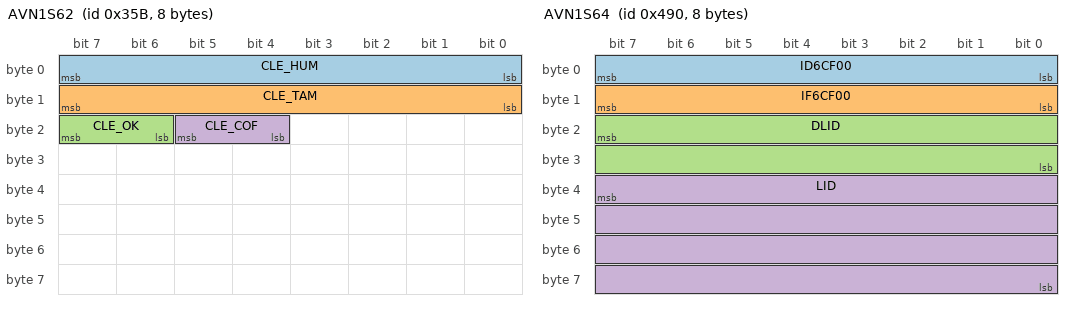
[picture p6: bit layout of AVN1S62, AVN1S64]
BO_ 859 AVN1S62: 8 CDC
 SG_ CLE_HUM : 7|8@0+ (1,0) [0|0] "%"  BDL,BDR
 SG_ CLE_TAM : 15|8@0- (1,0) [0|0] "degC"  BDL,BDR
 SG_ CLE_OK : 23|2@0+ (1,0) [0|0] "-"  BDL,BDR
 SG_ CLE_COF : 21|2@0+ (1,0) [0|0] "-"  BDL,BDR

BO_ 969 AVN1S63: 8 CDC
 SG_ MMC1 : 7|32@0- (1,0) [0|0] "-"  ADC,BDL,BGW
 SG_ MMC2 : 39|32@0- (1,0) [0|0] "-"  ADC,BDL,BGW

BO_ 1168 AVN1S64: 8 CDC
 SG_ ID6CF00 : 7|8@0+ (1,0) [0|0] "-"  BGW
 SG_ IF6CF00 : 15|8@0+ (1,0) [0|0] "-"  BGW
 SG_ DLID : 23|16@0+ (1,0) [0|0] "-"  ADC,BGW
 SG_ LID : 39|32@0+ (1,0) [0|0] "-"  ADC,BGW

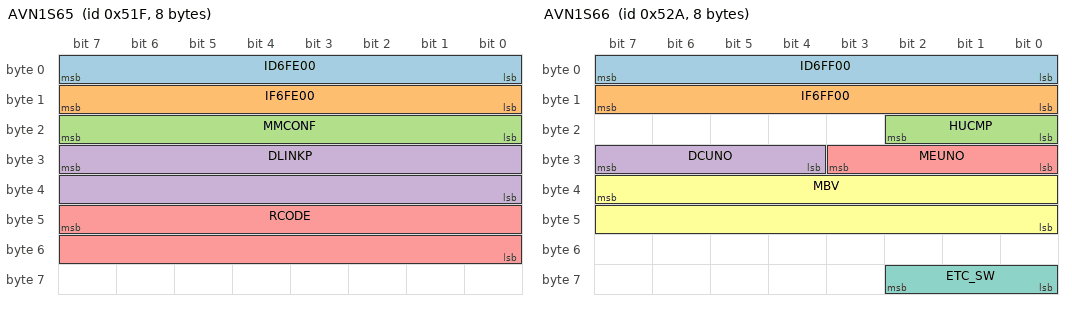
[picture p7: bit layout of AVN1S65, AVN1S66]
BO_ 1311 AVN1S65: 8 CDC
 SG_ ID6FE00 : 7|8@0+ (1,0) [0|0] "-"  BGW
 SG_ IF6FE00 : 15|8@0+ (1,0) [0|0] "-"  BGW
 SG_ MMCONF : 23|8@0+ (1,0) [0|0] "-"  BGW
 SG_ DLINKP : 31|16@0+ (1,0) [0|0] "m"  ADC,BGW
 SG_ RCODE : 47|16@0+ (1,0) [0|0] "-"  ADC,BGW

BO_ 1322 AVN1S66: 8 CDC
 SG_ ID6FF00 : 7|8@0+ (1,0) [0|0] "-"  BGW
 SG_ IF6FF00 : 15|8@0+ (1,0) [0|0] "-"  BGW
 SG_ HUCMP : 18|3@0+ (1,0) [0|0] "-"  BGW
 SG_ DCUNO : 31|4@0+ (1,0) [0|0] "-"  BGW
 SG_ MEUNO : 27|4@0+ (1,0) [0|0] "-"  BGW
 SG_ MBV : 39|16@0+ (1,0) [0|0] "-"  BGW
 SG_ ETC_SW : 58|3@0+ (1,0) [0|0] "-"  BGW

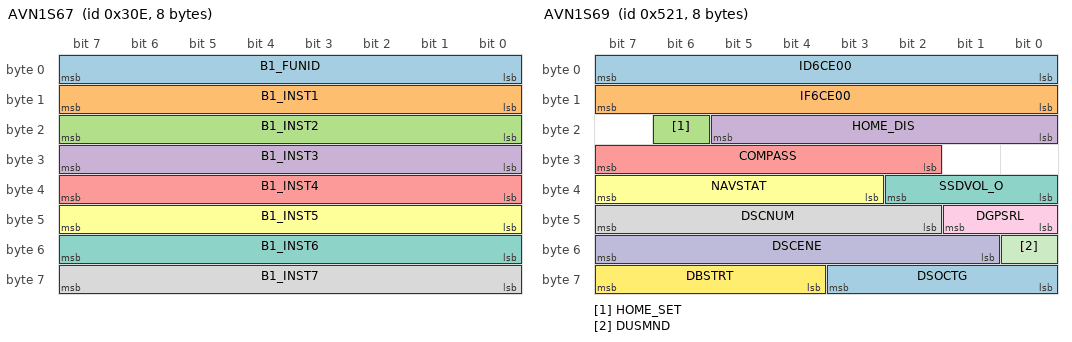
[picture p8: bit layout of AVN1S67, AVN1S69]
BO_ 782 AVN1S67: 8 CDC
 SG_ B1_FUNID : 7|8@0+ (1,0) [0|0] "-"  BDL
 SG_ B1_INST1 : 15|8@0+ (1,0) [0|0] "-"  BDL
 SG_ B1_INST2 : 23|8@0+ (1,0) [0|0] "-"  BDL
 SG_ B1_INST3 : 31|8@0+ (1,0) [0|0] "-"  BDL
 SG_ B1_INST4 : 39|8@0+ (1,0) [0|0] "-"  BDL
 SG_ B1_INST5 : 47|8@0+ (1,0) [0|0] "-"  BDL
 SG_ B1_INST6 : 55|8@0+ (1,0) [0|0] "-"  BDL
 SG_ B1_INST7 : 63|8@0+ (1,0) [0|0] "-"  BDL

BO_ 1313 AVN1S69: 8 CDC
 SG_ ID6CE00 : 7|8@0+ (1,0) [0|0] "-"  Vector_XXX
 SG_ IF6CE00 : 15|8@0+ (1,0) [0|0] "-"  Vector_XXX
 SG_ HOME_SET : 22|1@0+ (1,0) [0|0] "-"  ADC,DDM
 SG_ HOME_DIS : 21|6@0+ (50,0) [0|0] "m"  ADC,DDM
 SG_ COMPASS : 31|6@0+ (11.25,0) [0|0] "degree"  ADC,BDL
 SG_ NAVSTAT : 39|5@0+ (1,0) [0|0] "-"  Vector_XXX
 SG_ SSDVOL_O : 34|3@0+ (1,0) [0|0] "-"  Vector_XXX
 SG_ DSCNUM : 47|6@0+ (1,0) [0|0] "-"  Vector_XXX
 SG_ DGPSRL : 41|2@0+ (1,0) [0|0] "-"  Vector_XXX
 SG_ DSCENE : 55|7@0+ (0.1,0) [0|0] "MJ"  Vector_XXX
 SG_ DUSMND : 48|1@0+ (1,0) [0|0] "-"  Vector_XXX
 SG_ DBSTRT : 63|4@0+ (1,1) [0|0] "kW/8ms"  Vector_XXX
 SG_ DSOCTG : 59|4@0+ (4,20) [0|0] "%"  Vector_XXX

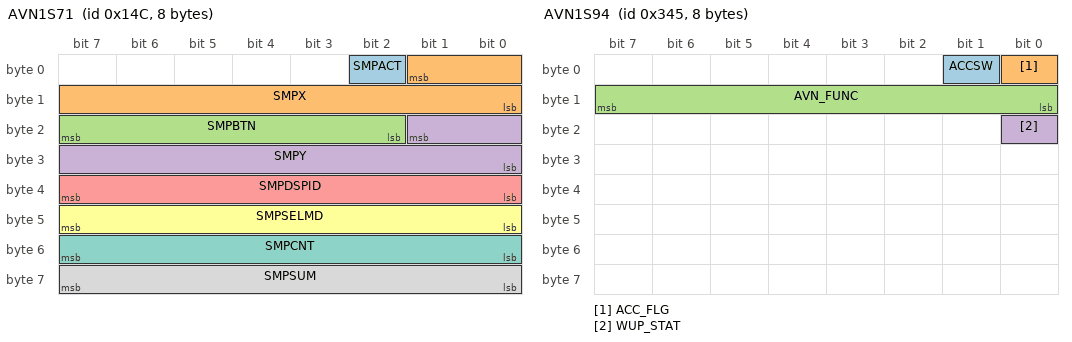
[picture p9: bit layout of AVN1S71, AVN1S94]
BO_ 332 AVN1S71: 8 CDC
 SG_ SMPACT : 2|1@0+ (1,0) [0|0] "-"  ADC,BDL
 SG_ SMPX : 1|10@0+ (1,0) [0|0] "-"  ADC
 SG_ SMPBTN : 23|6@0+ (1,0) [0|0] "-"  ADC
 SG_ SMPY : 17|10@0+ (1,0) [0|0] "-"  ADC
 SG_ SMPDSPID : 39|8@0+ (1,0) [0|0] "-"  ADC
 SG_ SMPSELMD : 47|8@0+ (1,0) [0|0] "-"  ADC
 SG_ SMPCNT : 55|8@0+ (1,0) [0|0] "-"  ADC
 SG_ SMPSUM : 63|8@0+ (1,0) [0|0] "-"  ADC

BO_ 682 AVN1S73: 8 CDC
 SG_ AVN_ON : 7|1@0+ (1,0) [0|0] "-"  ADC,BGW
 SG_ CC_MODE : 6|1@0+ (1,0) [0|0] "-"  ADC,BGW
 SG_ IRQ_MM : 5|1@0+ (1,0) [0|0] "-"  ADC,BGW
 SG_ CMD_MODE : 4|1@0+ (1,0) [0|0] "-"  ADC,BGW
 SG_ DI_MODE : 3|1@0+ (1,0) [0|0] "-"  ADC,BGW
 SG_ MM_RESET : 2|1@0+ (1,0) [0|0] "-"  ADC,BGW
 SG_ X_COORD : 1|10@0+ (1,0) [0|0] "-"  ADC,BGW
 SG_ DN_DISP : 23|1@0+ (1,0) [0|0] "-"  ADC,BGW
 SG_ MMD_MODE : 22|1@0+ (1,0) [0|0] "-"  ADC,BGW
 SG_ SW_PVM : 21|1@0+ (1,0) [0|0] "-"  ADC,BGW
 SG_ CUST_TRA : 20|1@0+ (1,0) [0|0] "-"  ADC,BGW
 SG_ CUST_APP : 19|1@0+ (1,0) [0|0] "-"  ADC,BGW
 SG_ CUST_PVM : 18|1@0+ (1,0) [0|0] "-"  ADC,BGW
 SG_ Y_COORD : 17|10@0+ (1,0) [0|0] "-"  ADC,BGW
 SG_ VR_STATE : 39|3@0+ (1,0) [0|0] "-"  ADC,BGW
 SG_ MIC_POS : 36|3@0+ (1,0) [0|0] "-"  ADC,BGW
 SG_ X2_COORD : 33|10@0+ (1,0) [0|0] "-"  ADC,BGW
 SG_ CD_SIZE : 55|4@0+ (1,0) [0|0] "-"  ADC,BGW
 SG_ Y2_COORD : 49|10@0+ (1,0) [0|0] "-"  ADC,BGW

BO_ 837 AVN1S94: 8 CDC
 SG_ ACCSW : 1|1@0+ (1,0) [0|0] "-"  BDF,BDL
 SG_ ACC_FLG : 0|1@0+ (1,0) [0|0] "-"  BDF,BDL
 SG_ AVN_FUNC : 15|8@0+ (1,0) [0|0] "-"  ADC
 SG_ WUP_STAT : 16|1@0+ (1,0) [0|0] "-"  ADC

BO_ 838 AVN1S95: 8 CDC
 SG_ OTA2RSLT : 7|8@0+ (1,0) [0|0] "-"  BDL,BGW,DDM
 SG_ OTA3RSLT : 15|8@0+ (1,0) [0|0] "-"  ADC,BDL,BGW,DDM
 SG_ OTADRSLT : 23|8@0+ (1,0) [0|0] "-"  BDL,BGW,DDM
 SG_ SRVC_STT : 31|2@0+ (1,0) [0|0] "-"  ADC,BDL,BGW,DDM
 SG_ OTA2CNCL : 29|1@0+ (1,0) [0|0] "-"  BDL,BGW,DDM
 SG_ OTA3CNCL : 28|1@0+ (1,0) [0|0] "-"  ADC,BDL,BGW,DDM
 SG_ OTADCNCL : 27|1@0+ (1,0) [0|0] "-"  BDL,BGW,DDM
 SG_ CUR_DRV : 24|3@0+ (1,0) [0|0] "-"  ADC,BDL,BGW,DDM
 SG_ SRVC_PC : 37|2@0+ (1,0) [0|0] "-"  ADC,BDL,BGW,DDM
 SG_ SRVC_VC : 35|2@0+ (1,0) [0|0] "-"  ADC,BDL,BGW,DDM
 SG_ SRVC_AC : 33|2@0+ (1,0) [0|0] "-"  ADC,BDL,BGW,DDM
 SG_ OTAPPCTL : 47|1@0+ (1,0) [0|0] "-"  BDF,BDL,BDR,BGW,DDM
 SG_ CW_MD_SW : 46|1@0+ (1,0) [0|0] "-"  BDL,BGW,DDM
 SG_ VNHLDRQ : 45|1@0+ (1,0) [0|0] "-"  BDL,BGW,DDM
 SG_ TRNCASW : 44|1@0+ (1,0) [0|0] "-"  ADC,BDL,BGW,DDM
 SG_ TRNSD : 43|1@0+ (1,0) [0|0] "-"  ADC,BDL,BGW,DDM
 SG_ TRNFBPD : 42|1@0+ (1,0) [0|0] "-"  ADC,BDL,BGW,DDM
 SG_ OTACDRLT : 51|2@0+ (1,0) [0|0] "-"  ADC,BDL,BGW,DDM
 SG_ OTACHGEX : 49|1@0+ (1,0) [0|0] "-"  BDL,BGW,DDM
 SG_ OTAACTTP : 48|3@0+ (1,0) [0|0] "-"  ADC,BDL,BGW,DDM
 SG_ OTAACTPH : 61|1@0+ (1,0) [0|0] "-"  ADC,BDF,BDL,BDR,BGW,DDM
 SG_ OTASWACT : 60|1@0+ (1,0) [0|0] "-"  ADC,BDF,BDL,BDR,BGW,DDM
 SG_ OTASTAT : 59|4@0+ (1,0) [0|0] "-"  ADC,BDF,BDL,BDR,BGW,DDM

BO_ 985 AVN1S97: 32 CDC
 SG_ S_FRONOF : 6|1@0+ (1,0) [0|0] "-"  BDF,BDL
 SG_ S_WFRCR : 5|2@0+ (1,0) [0|0] "-"  BDF,BDL
 SG_ S_RFRCR : 3|2@0+ (1,0) [0|0] "-"  BDF,BDL
 SG_ S_WFRSTR : 1|2@0+ (1,0) [0|0] "-"  BDF,BDL
 SG_ S_RFRSTR : 15|2@0+ (1,0) [0|0] "-"  BDF,BDL
 SG_ S_PMREMO : 13|1@0+ (1,0) [0|0] "-"  BDF,BDL
 SG_ S_BLWCL : 12|2@0+ (1,0) [0|0] "-"  BDF,BDL
 SG_ S_HBCD_D : 10|3@0+ (1,0) [0|0] "-"  BDF,BDL
 SG_ S_HBMD_D : 22|2@0+ (1,0) [0|0] "-"  BDF,BDL
 SG_ S_HBCD_P : 20|3@0+ (1,0) [0|0] "-"  BDF,BDL
 SG_ S_HBMD_P : 17|2@0+ (1,0) [0|0] "-"  BDF,BDL
 SG_ S_HBCDRR : 31|3@0+ (1,0) [0|0] "-"  BDF,BDL
 SG_ S_HBMDRR : 28|2@0+ (1,0) [0|0] "-"  BDF,BDL
 SG_ S_HBCDRL : 26|3@0+ (1,0) [0|0] "-"  BDF,BDL
 SG_ S_HBMDRL : 39|2@0+ (1,0) [0|0] "-"  BDF,BDL
 SG_ S_STHCD : 47|2@0+ (1,0) [0|0] "-"  BDF,BDL
 SG_ V_FG_CH : 71|3@0+ (1,0) [0|0] "-"  BDF,BDL
 SG_ V_FG_LVL : 68|3@0+ (1,0) [0|0] "-"  BDF,BDL
 SG_ V_FG_PWR : 65|2@0+ (1,0) [0|0] "-"  BDF,BDL
 SG_ S_FG_CH : 77|3@0+ (1,0) [0|0] "-"  BDF,BDL
 SG_ S_FG_LVL : 74|3@0+ (1,0) [0|0] "-"  BDF,BDL
 SG_ S_TMODE : 87|4@0+ (1,0) [0|0] "-"  BDF,BDL

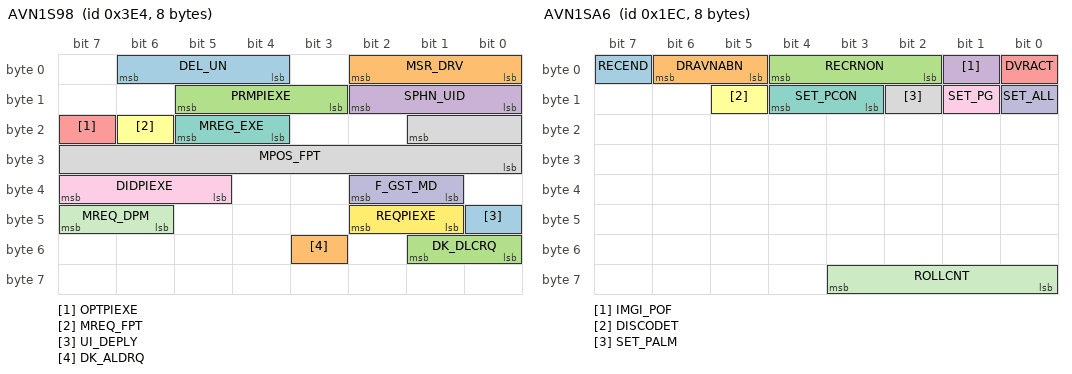
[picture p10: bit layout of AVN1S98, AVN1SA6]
BO_ 996 AVN1S98: 8 CDC
 SG_ DEL_UN : 6|3@0+ (1,0) [0|0] "-"  BDL
 SG_ MSR_DRV : 2|3@0+ (1,0) [0|0] "-"  BDL
 SG_ PRMPIEXE : 13|3@0+ (1,0) [0|0] "-"  BDL
 SG_ SPHN_UID : 10|3@0+ (1,0) [0|0] "-"  BDL
 SG_ OPTPIEXE : 23|1@0+ (1,0) [0|0] "-"  BDL
 SG_ MREQ_FPT : 22|1@0+ (1,0) [0|0] "-"  Vector_XXX
 SG_ MREG_EXE : 21|2@0+ (1,0) [0|0] "-"  Vector_XXX
 SG_ MPOS_FPT : 17|10@0+ (1,0) [0|0] "-"  Vector_XXX
 SG_ DIDPIEXE : 39|3@0+ (1,0) [0|0] "-"  BDL
 SG_ F_GST_MD : 34|2@0+ (1,0) [0|0] "-"  BDL
 SG_ MREQ_DPM : 47|2@0+ (1,0) [0|0] "-"  BDL
 SG_ REQPIEXE : 42|2@0+ (1,0) [0|0] "-"  BDL
 SG_ UI_DEPLY : 40|1@0+ (1,0) [0|0] "-"  BDL
 SG_ DK_ALDRQ : 51|1@0+ (1,0) [0|0] "-"  Vector_XXX
 SG_ DK_DLCRQ : 49|2@0+ (1,0) [0|0] "-"  Vector_XXX

BO_ 960 AVN1S99: 8 CDC
 SG_ A_CURHRQ : 23|2@0+ (1,0) [0|0] "-"  Vector_XXX
 SG_ A_CURREQ : 21|3@0+ (1,0) [0|0] "-"  DDM
 SG_ A_CLCREQ : 18|3@0+ (1,0) [0|0] "-"  DDM
 SG_ A_LMTHRQ : 31|2@0+ (1,0) [0|0] "-"  Vector_XXX
 SG_ A_SLMREQ : 29|3@0+ (1,0) [0|0] "-"  DDM
 SG_ A_LMTREQ : 26|3@0+ (1,0) [0|0] "-"  DDM
 SG_ A_SPLMOD : 39|2@0+ (1,0) [0|0] "-"  DDM
 SG_ A_TMRHRQ : 37|2@0+ (1,0) [0|0] "-"  Vector_XXX
 SG_ A_LMTSRQ : 35|2@0+ (1,0) [0|0] "-"  Vector_XXX
 SG_ A_SLMDRQ : 33|2@0+ (1,0) [0|0] "-"  DDM
 SG_ A_DPWREQ : 47|4@0+ (1,0) [0|0] "-"  DDM
 SG_ A_PNCREQ : 43|2@0+ (1,0) [0|0] "-"  DDM
 SG_ A_CEIBPH : 41|1@0+ (1,0) [0|0] "-"  DDM
 SG_ A_DVOREQ : 55|2@0+ (1,0) [0|0] "-"  DDM
 SG_ A_CHGCRQ : 53|1@0+ (1,0) [0|0] "-"  DDM
 SG_ OUTCS : 52|6@0+ (10,0) [0|0] "kW"  DDM
 SG_ JDTCS : 62|2@0+ (1,0) [0|0] "-"  DDM

BO_ 492 AVN1SA6: 8 CDC
 SG_ RECEND : 7|1@0+ (1,0) [0|0] "-"  BDL,BGW
 SG_ DRAVNABN : 6|2@0+ (1,0) [0|0] "-"  BDL,BGW
 SG_ RECRNON : 4|3@0+ (1,0) [0|0] "-"  BDL,BGW
 SG_ IMGI_POF : 1|1@0+ (1,0) [0|0] "-"  BDL,BGW
 SG_ DVRACT : 0|1@0+ (1,0) [0|0] "-"  BDL,BGW
 SG_ DISCODET : 13|1@0+ (1,0) [0|0] "-"  BDL,BGW
 SG_ SET_PCON : 12|2@0+ (1,0) [0|0] "-"  BDL,BGW
 SG_ SET_PALM : 10|1@0+ (1,0) [0|0] "-"  BDL,BGW
 SG_ SET_PG : 9|1@0+ (1,0) [0|0] "-"  BDL,BGW
 SG_ SET_ALL : 8|1@0+ (1,0) [0|0] "-"  BDL,BGW
 SG_ ROLLCNT : 59|4@0+ (1,0) [0|0] "-"  ADC,BDL,BGW

BO_ 858 AVN1SA7: 32 CDC
 SG_ QIC_MTS : 7|3@0+ (1,0) [0|0] "-"  BDL
 SG_ QIC_MTM : 4|3@0+ (1,0) [0|0] "-"  BDL
 SG_ QIC_FSS : 1|2@0+ (1,0) [0|0] "-"  Vector_XXX
 SG_ QIC_MPTS : 15|3@0+ (1,0) [0|0] "-"  BDL
 SG_ QIC_MPTM : 12|4@0+ (1,0) [0|0] "-"  BDL
 SG_ QIC_MPQK : 23|2@0+ (1,0) [0|0] "-"  BDL
 SG_ QIC_FTS : 21|3@0+ (1,0) [0|0] "-"  BDL
 SG_ QIC_FTM : 18|3@0+ (1,0) [0|0] "-"  BDL
 SG_ QIC_FSP : 31|3@0+ (1,0) [0|0] "-"  BDL
 SG_ QIC_BTS : 28|3@0+ (1,0) [0|0] "-"  BDL
 SG_ SIC_BCS : 25|2@0+ (1,0) [0|0] "-"  BDL
 SG_ QIC_BTM : 39|3@0+ (1,0) [0|0] "-"  BDL
 SG_ QIC_BSP : 36|3@0+ (1,0) [0|0] "-"  BDL
 SG_ SIC_RBCS : 33|2@0+ (1,0) [0|0] "-"  Vector_XXX
 SG_ QIC_RTS : 47|3@0+ (1,0) [0|0] "-"  BDL
 SG_ QIC_RTM : 44|3@0+ (1,0) [0|0] "-"  BDL
 SG_ QIC_RSET : 41|1@0+ (1,0) [0|0] "-"  BDL
 SG_ QIC_RSTS : 55|3@0+ (1,0) [0|0] "-"  BDL
 SG_ QIC_RSTM : 52|3@0+ (1,0) [0|0] "-"  BDL
 SG_ QIC_RKQK : 49|2@0+ (1,0) [0|0] "-"  BDL
 SG_ SIC_IDN : 63|4@0+ (1,0) [0|0] "-"  BDL
 SG_ SIC_IDS : 59|2@0+ (1,0) [0|0] "-"  BDL
 SG_ AIC_IDA : 57|2@0+ (1,0) [0|0] "-"  BDL
 SG_ QDK_ADLQ : 71|2@0+ (1,0) [0|0] "-"  BDL
 SG_ QDK_ODRQ : 69|2@0+ (1,0) [0|0] "-"  BDL
 SG_ QDK_OGRQ : 67|2@0+ (1,0) [0|0] "-"  BDL
 SG_ QDK_ORRQ : 65|2@0+ (1,0) [0|0] "-"  BDL
 SG_ QDK_OWCQ : 79|2@0+ (1,0) [0|0] "-"  BDL
 SG_ QDK_OCRQ : 77|2@0+ (1,0) [0|0] "-"  BDL
 SG_ QDK_FDRQ : 75|2@0+ (1,0) [0|0] "-"  BDL
 SG_ SIC_RSES : 87|3@0+ (1,0) [0|0] "-"  Vector_XXX
 SG_ QDK_CRQ : 84|2@0+ (1,0) [0|0] "-"  BDL
 SG_ SLID_REQ : 82|2@0+ (1,0) [0|0] "-"  BDL
 SG_ QSM_CARE : 95|4@0+ (1,0) [0|0] "-"  BDL
 SG_ QSM_CQTI : 91|4@0+ (1,0) [0|0] "-"  BDL
 SG_ QSM_CRNG : 103|2@0+ (1,0) [0|0] "-"  BDL
 SG_ QSM_CRQ : 101|2@0+ (1,0) [0|0] "-"  BDL
 SG_ QCL_OPEQ : 99|2@0+ (1,0) [0|0] "-"  BDL
 SG_ QCL_RQTG : 97|2@0+ (1,0) [0|0] "-"  BDL
 SG_ QRS_OPEQ : 111|3@0+ (1,0) [0|0] "-"  BDL
 SG_ QDK_CARE : 108|4@0+ (1,0) [0|0] "-"  BDL
 SG_ QDK_CQTI : 119|4@0+ (1,0) [0|0] "-"  BDL
 SG_ QDK_CRNG : 115|2@0+ (1,0) [0|0] "-"  BDL
 SG_ QDK_DLTI : 127|4@0+ (1,0) [0|0] "-"  BDL

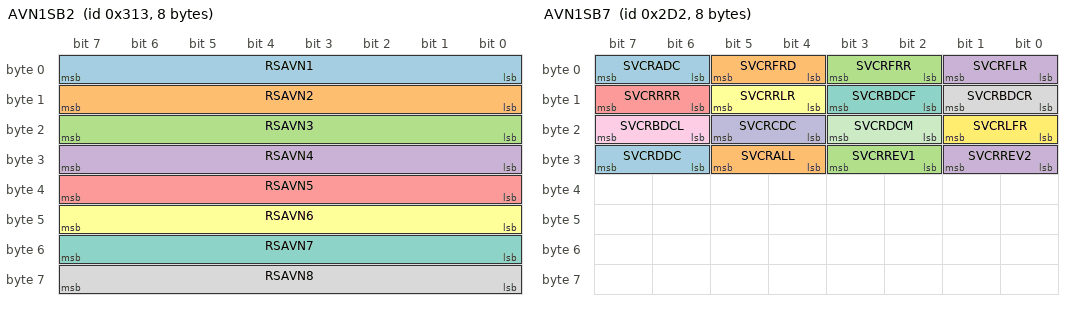
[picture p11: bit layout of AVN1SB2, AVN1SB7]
BO_ 787 AVN1SB2: 8 CDC
 SG_ RSAVN1 : 7|8@0+ (1,0) [0|0] "-"  BGW
 SG_ RSAVN2 : 15|8@0+ (1,0) [0|0] "-"  BGW
 SG_ RSAVN3 : 23|8@0+ (1,0) [0|0] "-"  BGW
 SG_ RSAVN4 : 31|8@0+ (1,0) [0|0] "-"  BGW
 SG_ RSAVN5 : 39|8@0+ (1,0) [0|0] "-"  BGW
 SG_ RSAVN6 : 47|8@0+ (1,0) [0|0] "-"  BGW
 SG_ RSAVN7 : 55|8@0+ (1,0) [0|0] "-"  BGW
 SG_ RSAVN8 : 63|8@0+ (1,0) [0|0] "-"  BGW

BO_ 1301 AVN1SB3: 32 CDC
 SG_ MS_MD : 7|3@0+ (1,0) [0|0] "-"  BDL
 SG_ MS_ILDTP : 15|1@0+ (1,0) [0|0] "-"  BDL
 SG_ MS_ILDTT : 12|5@0+ (1,0) [0|0] "-"  BDL
 SG_ MS_ILLB1 : 23|4@0+ (1,0) [0|0] "-"  BDL
 SG_ MS_ILLB2 : 19|4@0+ (1,0) [0|0] "-"  BDL
 SG_ MS_ILLB3 : 31|4@0+ (1,0) [0|0] "-"  BDL
 SG_ MS_ILLB4 : 27|4@0+ (1,0) [0|0] "-"  BDL
 SG_ MS_ILLB5 : 39|4@0+ (1,0) [0|0] "-"  BDL
 SG_ MS_ILLB6 : 35|4@0+ (1,0) [0|0] "-"  BDL
 SG_ MS_ILCL1 : 55|7@0+ (1,0) [0|0] "-"  BDL
 SG_ MS_ILCL2 : 63|7@0+ (1,0) [0|0] "-"  BDL
 SG_ MS_ILCL3 : 71|7@0+ (1,0) [0|0] "-"  BDL
 SG_ MS_ILCL4 : 79|7@0+ (1,0) [0|0] "-"  BDL
 SG_ MS_ILCL5 : 87|7@0+ (1,0) [0|0] "-"  BDL
 SG_ MS_ILCL6 : 95|7@0+ (1,0) [0|0] "-"  BDL

BO_ 722 AVN1SB7: 8 CDC
 SG_ SVCRADC : 7|2@0+ (1,0) [0|0] "-"  ADC
 SG_ SVCRFRD : 5|2@0+ (1,0) [0|0] "-"  ADC
 SG_ SVCRFRR : 3|2@0+ (1,0) [0|0] "-"  ADC
 SG_ SVCRFLR : 1|2@0+ (1,0) [0|0] "-"  ADC
 SG_ SVCRRRR : 15|2@0+ (1,0) [0|0] "-"  ADC
 SG_ SVCRRLR : 13|2@0+ (1,0) [0|0] "-"  ADC
 SG_ SVCRBDCF : 11|2@0+ (1,0) [0|0] "-"  ADC
 SG_ SVCRBDCR : 9|2@0+ (1,0) [0|0] "-"  ADC
 SG_ SVCRBDCL : 23|2@0+ (1,0) [0|0] "-"  ADC
 SG_ SVCRCDC : 21|2@0+ (1,0) [0|0] "-"  ADC
 SG_ SVCRDCM : 19|2@0+ (1,0) [0|0] "-"  ADC
 SG_ SVCRLFR : 17|2@0+ (1,0) [0|0] "-"  ADC
 SG_ SVCRDDC : 31|2@0+ (1,0) [0|0] "-"  ADC
 SG_ SVCRALL : 29|2@0+ (1,0) [0|0] "-"  ADC
 SG_ SVCRREV1 : 27|2@0+ (1,0) [0|0] "-"  ADC
 SG_ SVCRREV2 : 25|2@0+ (1,0) [0|0] "-"  ADC

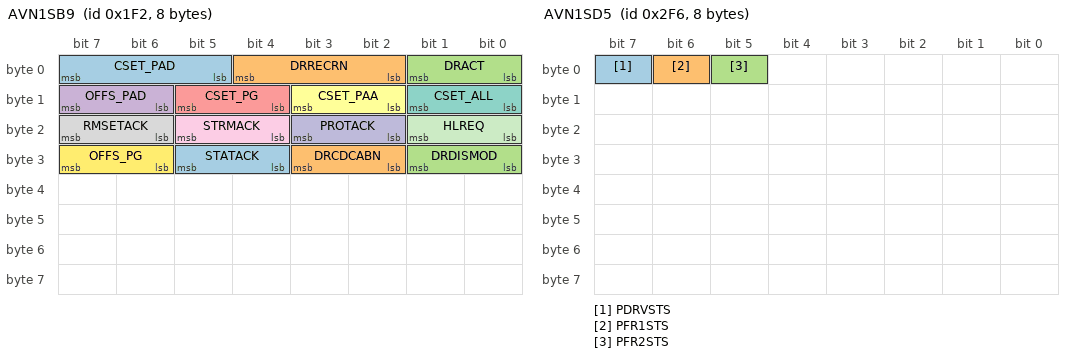
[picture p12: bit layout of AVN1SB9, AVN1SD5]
BO_ 498 AVN1SB9: 8 CDC
 SG_ CSET_PAD : 7|3@0+ (1,0) [0|0] "-"  BDL,BGW
 SG_ DRRECRN : 4|3@0+ (1,0) [0|0] "-"  BGW
 SG_ DRACT : 1|2@0+ (1,0) [0|0] "-"  BDL,BGW
 SG_ OFFS_PAD : 15|2@0+ (1,0) [0|0] "-"  BDL,BGW
 SG_ CSET_PG : 13|2@0+ (1,0) [0|0] "-"  BDL,BGW
 SG_ CSET_PAA : 11|2@0+ (1,0) [0|0] "-"  BDL,BGW
 SG_ CSET_ALL : 9|2@0+ (1,0) [0|0] "-"  BDL,BGW
 SG_ RMSETACK : 23|2@0+ (1,0) [0|0] "-"  BDL,BGW
 SG_ STRMACK : 21|2@0+ (1,0) [0|0] "-"  BDL,BGW
 SG_ PROTACK : 19|2@0+ (1,0) [0|0] "-"  BDL,BGW
 SG_ HLREQ : 17|2@0+ (1,0) [0|0] "-"  BDL,BGW
 SG_ OFFS_PG : 31|2@0+ (1,0) [0|0] "-"  BDL,BGW
 SG_ STATACK : 29|2@0+ (1,0) [0|0] "-"  BDL,BGW
 SG_ DRCDCABN : 27|2@0+ (1,0) [0|0] "-"  BDL,BGW
 SG_ DRDISMOD : 25|2@0+ (1,0) [0|0] "-"  BDF,BDL,BGW

BO_ 724 AVN1SC1: 64 CDC
 SG_ UMOPIF01 : 7|16@0+ (1,0) [0|0] "-"  BDL
 SG_ UMOPRQ01 : 23|16@0+ (1,0) [0|0] "-"  BDL
 SG_ UMOPRV01 : 39|16@0+ (1,0) [0|0] "-"  BDL
 SG_ UMOPRD01 : 55|376@0+ (1,0) [0|0] "-"  BDL
 SG_ FV2D4 : 431|56@0+ (1,0) [0|0] "-"  BDL
 SG_ KZK2D4 : 487|32@0+ (1,0) [0|0] "-"  BDL

BO_ 725 AVN1SC2: 64 CDC
 SG_ UMOPIF02 : 7|16@0+ (1,0) [0|0] "-"  BDL
 SG_ UMOPRQ02 : 23|16@0+ (1,0) [0|0] "-"  BDL
 SG_ UMOPRV02 : 39|16@0+ (1,0) [0|0] "-"  BDL
 SG_ UMOPRD02 : 55|376@0+ (1,0) [0|0] "-"  BDL
 SG_ FV2D5 : 431|56@0+ (1,0) [0|0] "-"  BDL
 SG_ KZK2D5 : 487|32@0+ (1,0) [0|0] "-"  BDL

BO_ 726 AVN1SC3: 64 CDC
 SG_ UMOPIF03 : 7|16@0+ (1,0) [0|0] "-"  BDL
 SG_ UMOPRQ03 : 23|16@0+ (1,0) [0|0] "-"  BDL
 SG_ UMOPRV03 : 39|16@0+ (1,0) [0|0] "-"  BDL
 SG_ UMOPRD03 : 55|376@0+ (1,0) [0|0] "-"  BDL
 SG_ FV2D6 : 431|56@0+ (1,0) [0|0] "-"  BDL
 SG_ KZK2D6 : 487|32@0+ (1,0) [0|0] "-"  BDL

BO_ 727 AVN1SC4: 64 CDC
 SG_ UMOPIF04 : 7|16@0+ (1,0) [0|0] "-"  BDL
 SG_ UMOPRQ04 : 23|16@0+ (1,0) [0|0] "-"  BDL
 SG_ UMOPRV04 : 39|16@0+ (1,0) [0|0] "-"  BDL
 SG_ UMOPRD04 : 55|376@0+ (1,0) [0|0] "-"  BDL
 SG_ FV2D7 : 431|56@0+ (1,0) [0|0] "-"  BDL
 SG_ KZK2D7 : 487|32@0+ (1,0) [0|0] "-"  BDL

BO_ 735 AVN1SC5: 64 CDC
 SG_ UMOPIF05 : 7|16@0+ (1,0) [0|0] "-"  BDL
 SG_ UMOPRQ05 : 23|16@0+ (1,0) [0|0] "-"  BDL
 SG_ UMOPRV05 : 39|16@0+ (1,0) [0|0] "-"  BDL
 SG_ UMOPRD05 : 55|376@0+ (1,0) [0|0] "-"  BDL
 SG_ FV2DF : 431|56@0+ (1,0) [0|0] "-"  BDL
 SG_ KZK2DF : 487|32@0+ (1,0) [0|0] "-"  BDL

BO_ 736 AVN1SC6: 64 CDC
 SG_ UMOPIF06 : 7|16@0+ (1,0) [0|0] "-"  BDL
 SG_ UMOPRQ06 : 23|16@0+ (1,0) [0|0] "-"  BDL
 SG_ UMOPRV06 : 39|16@0+ (1,0) [0|0] "-"  BDL
 SG_ UMOPRD06 : 55|376@0+ (1,0) [0|0] "-"  BDL
 SG_ FV2E0 : 431|56@0+ (1,0) [0|0] "-"  BDL
 SG_ KZK2E0 : 487|32@0+ (1,0) [0|0] "-"  BDL

BO_ 737 AVN1SC7: 64 CDC
 SG_ UMOPIF07 : 7|16@0+ (1,0) [0|0] "-"  BDL
 SG_ UMOPRQ07 : 23|16@0+ (1,0) [0|0] "-"  BDL
 SG_ UMOPRV07 : 39|16@0+ (1,0) [0|0] "-"  BDL
 SG_ UMOPRD07 : 55|376@0+ (1,0) [0|0] "-"  BDL
 SG_ FV2E1 : 431|56@0+ (1,0) [0|0] "-"  BDL
 SG_ KZK2E1 : 487|32@0+ (1,0) [0|0] "-"  BDL

BO_ 738 AVN1SC8: 64 CDC
 SG_ UMOPIF08 : 7|16@0+ (1,0) [0|0] "-"  BDL
 SG_ UMOPRQ08 : 23|16@0+ (1,0) [0|0] "-"  BDL
 SG_ UMOPRV08 : 39|16@0+ (1,0) [0|0] "-"  BDL
 SG_ UMOPRD08 : 55|376@0+ (1,0) [0|0] "-"  BDL
 SG_ FV2E2 : 431|56@0+ (1,0) [0|0] "-"  BDL
 SG_ KZK2E2 : 487|32@0+ (1,0) [0|0] "-"  BDL

BO_ 751 AVN1SC9: 64 CDC
 SG_ UMOPIF09 : 7|16@0+ (1,0) [0|0] "-"  BDL
 SG_ UMOPRQ09 : 23|16@0+ (1,0) [0|0] "-"  BDL
 SG_ UMOPRV09 : 39|16@0+ (1,0) [0|0] "-"  BDL
 SG_ UMOPRD09 : 55|376@0+ (1,0) [0|0] "-"  BDL
 SG_ FV2EF : 431|56@0+ (1,0) [0|0] "-"  BDL
 SG_ KZK2EF : 487|32@0+ (1,0) [0|0] "-"  BDL

BO_ 752 AVN1SD1: 64 CDC
 SG_ UMOPIF10 : 7|16@0+ (1,0) [0|0] "-"  BDL
 SG_ UMOPRQ10 : 23|16@0+ (1,0) [0|0] "-"  BDL
 SG_ UMOPRV10 : 39|16@0+ (1,0) [0|0] "-"  BDL
 SG_ UMOPRD10 : 55|376@0+ (1,0) [0|0] "-"  BDL
 SG_ FV2F0 : 431|56@0+ (1,0) [0|0] "-"  BDL
 SG_ KZK2F0 : 487|32@0+ (1,0) [0|0] "-"  BDL

BO_ 754 AVN1SD2: 64 CDC
 SG_ UMOPIF11 : 7|16@0+ (1,0) [0|0] "-"  BDL
 SG_ UMOPRQ11 : 23|16@0+ (1,0) [0|0] "-"  BDL
 SG_ UMOPRV11 : 39|16@0+ (1,0) [0|0] "-"  BDL
 SG_ UMOPRD11 : 55|376@0+ (1,0) [0|0] "-"  BDL
 SG_ FV2F2 : 431|56@0+ (1,0) [0|0] "-"  BDL
 SG_ KZK2F2 : 487|32@0+ (1,0) [0|0] "-"  BDL

BO_ 757 AVN1SD3: 64 CDC
 SG_ UMOPIF12 : 7|16@0+ (1,0) [0|0] "-"  BDL
 SG_ UMOPRQ12 : 23|16@0+ (1,0) [0|0] "-"  BDL
 SG_ UMOPRV12 : 39|16@0+ (1,0) [0|0] "-"  BDL
 SG_ UMOPRD12 : 55|376@0+ (1,0) [0|0] "-"  BDL
 SG_ FV2F5 : 431|56@0+ (1,0) [0|0] "-"  BDL
 SG_ KZK2F5 : 487|32@0+ (1,0) [0|0] "-"  BDL

BO_ 389 AVN1SD4: 32 CDC
 SG_ DSADINX : 7|8@0+ (1,0) [0|0] "-"  BDR
 SG_ DSADINY : 15|8@0+ (1,0) [0|0] "-"  BDR
 SG_ DSSHTSW : 23|2@0+ (1,0) [0|0] "-"  BDR
 SG_ DCADINX : 21|8@0+ (1,0) [0|0] "-"  BDR
 SG_ DCADINY : 29|8@0+ (1,0) [0|0] "-"  BDR
 SG_ DCSHTSW : 37|2@0+ (1,0) [0|0] "-"  BDR
 SG_ PSADINX : 35|8@0+ (1,0) [0|0] "-"  BDR
 SG_ PSADINY : 43|8@0+ (1,0) [0|0] "-"  BDR
 SG_ PSSHTSW : 51|2@0+ (1,0) [0|0] "-"  BDR
 SG_ PCADINX : 49|8@0+ (1,0) [0|0] "-"  BDR
 SG_ PCADINY : 57|8@0+ (1,0) [0|0] "-"  BDR
 SG_ PCSHTSW : 65|2@0+ (1,0) [0|0] "-"  BDR
 SG_ RRCADINX : 79|8@0+ (1,0) [0|0] "-"  BDR
 SG_ RRCADINY : 87|8@0+ (1,0) [0|0] "-"  BDR
 SG_ RRCSHTSW : 95|2@0+ (1,0) [0|0] "-"  BDR
 SG_ RLCADINX : 93|8@0+ (1,0) [0|0] "-"  BDR
 SG_ RLCADINY : 101|8@0+ (1,0) [0|0] "-"  BDR
 SG_ RLCSHTSW : 109|2@0+ (1,0) [0|0] "-"  BDR
 SG_ ERSWISWD : 107|2@0+ (1,0) [0|0] "-"  BDR
 SG_ BLMDCUST : 105|2@0+ (1,0) [0|0] "-"  BDR
 SG_ DSPADIN : 119|3@0+ (1,0) [0|0] "-"  BDR
 SG_ DCPADIN : 116|3@0+ (1,0) [0|0] "-"  BDR
 SG_ PSPADIN : 113|3@0+ (1,0) [0|0] "-"  BDR
 SG_ PCPADIN : 126|3@0+ (1,0) [0|0] "-"  BDR
 SG_ RRCPADIN : 123|3@0+ (1,0) [0|0] "-"  BDR
 SG_ RLCPADIN : 120|3@0+ (1,0) [0|0] "-"  BDR
 SG_ ERSWISWP : 133|2@0+ (1,0) [0|0] "-"  BDR
 SG_ ERSPTSWP : 131|2@0+ (1,0) [0|0] "-"  BDR
 SG_ ERSPRSWP : 129|2@0+ (1,0) [0|0] "-"  BDR
 SG_ ERSPTSWD : 143|2@0+ (1,0) [0|0] "-"  BDR
 SG_ ERSPRSWD : 141|2@0+ (1,0) [0|0] "-"  BDR

BO_ 758 AVN1SD5: 8 CDC
 SG_ PDRVSTS : 7|1@0+ (1,0) [0|0] "-"  ADC,BGW
 SG_ PFR1STS : 6|1@0+ (1,0) [0|0] "-"  ADC,BGW
 SG_ PFR2STS : 5|1@0+ (1,0) [0|0] "-"  ADC,BGW

BO_ 760 AVN1SF8: 32 CDC
 SG_ SBCGROTA : 7|8@0+ (1,0) [0|0] "-"  BDF,BDL
 SG_ SBCRVOTA : 15|16@0+ (1,0) [0|0] "%"  BDF,BDL
 SG_ RDYOF_RQ : 31|1@0+ (1,0) [0|0] "-"  BDL

BO_ 762 AVN1SF9: 32 CDC
 SG_ ECUPWCRQ : 7|1@0+ (1,0) [0|0] "-"  BDF,BDL,BDR
 SG_ PWCRQMOD : 6|1@0+ (1,0) [0|0] "-"  BDF,BDL,BDR
 SG_ PWCRQID : 5|6@0+ (1,0) [0|0] "-"  BDF,BDL,BDR
 SG_ PWCTID01 : 15|8@0+ (1,0) [0|0] "-"  BDF,BDL,BDR
 SG_ PWCTID02 : 23|8@0+ (1,0) [0|0] "-"  BDF,BDL,BDR
 SG_ PWCTID03 : 31|8@0+ (1,0) [0|0] "-"  BDF,BDL,BDR
 SG_ PWCTID04 : 39|8@0+ (1,0) [0|0] "-"  BDF,BDL,BDR
 SG_ PWCTID05 : 47|8@0+ (1,0) [0|0] "-"  BDF,BDL,BDR
 SG_ PWCTID06 : 55|8@0+ (1,0) [0|0] "-"  BDF,BDL,BDR
 SG_ PWCTID07 : 63|8@0+ (1,0) [0|0] "-"  BDF,BDL,BDR
 SG_ PWCTID08 : 71|8@0+ (1,0) [0|0] "-"  BDF,BDL,BDR
 SG_ PWCTID09 : 79|8@0+ (1,0) [0|0] "-"  BDF,BDL,BDR
 SG_ PWCTID10 : 87|8@0+ (1,0) [0|0] "-"  BDF,BDL,BDR

BO_ 763 AVN1SG1: 8 CDC
 SG_ VPSCROTA : 31|8@0+ (1,0) [0|0] "-"  BDL

BO_ 826 AVN1SG3: 32 CDC
 SG_ A_DPSRQ : 7|2@0+ (1,0) [0|0] "-"  BDL
 SG_ A_DPID : 5|3@0+ (1,0) [0|0] "-"  BDL
 SG_ A_DPON : 2|1@0+ (1,0) [0|0] "-"  BDL
 SG_ A_DPTYP : 1|1@0+ (1,0) [0|0] "-"  BDL
 SG_ A_DPDAY : 0|7@0+ (1,0) [0|0] "-"  BDL
 SG_ A_DPMON : 9|4@0+ (1,0) [0|0] "-"  BDL
 SG_ A_DPDAT : 21|5@0+ (1,0) [0|0] "-"  BDL
 SG_ A_DPDTM : 16|9@0+ (1,0) [0|0] "-"  BDL
 SG_ A_DPAC : 39|1@0+ (1,0) [0|0] "-"  BDL
 SG_ A_DPBC : 38|1@0+ (1,0) [0|0] "-"  BDL
 SG_ A_DPTMP : 37|8@0+ (1,0) [0|0] "-"  BDL
 SG_ A_DPACMD : 45|1@0+ (1,0) [0|0] "-"  BDL
 SG_ A_DPSH : 44|2@0+ (1,0) [0|0] "-"  BDL
 SG_ A_DPREFR : 42|2@0+ (1,0) [0|0] "-"  BDL
 SG_ A_DPBLLV : 40|4@0+ (1,0) [0|0] "-"  BDL
 SG_ A_DPFDHV : 52|2@0+ (1,0) [0|0] "-"  BDL
 SG_ A_DPFPHV : 50|2@0+ (1,0) [0|0] "-"  BDL
 SG_ A_DPRDHV : 48|2@0+ (1,0) [0|0] "-"  BDL
 SG_ A_DPRPHV : 62|2@0+ (1,0) [0|0] "-"  BDL
 SG_ A_DPFDEF : 60|2@0+ (1,0) [0|0] "-"  BDL
 SG_ A_DPRDEF : 58|2@0+ (1,0) [0|0] "-"  BDL
 SG_ A_DPFGON : 56|2@0+ (1,0) [0|0] "-"  BDL
 SG_ A_DPFGLV : 70|3@0+ (1,0) [0|0] "-"  BDL
 SG_ A_DPFGCH : 67|2@0+ (1,0) [0|0] "-"  BDL
 SG_ A_DPACTM : 65|3@0+ (1,0) [0|0] "-"  BDL
 SG_ MRONPSH : 78|1@0+ (1,0) [0|0] "-"  BDL
 SG_ MROFFPSH : 77|1@0+ (1,0) [0|0] "-"  BDL
 SG_ MRSOCSEL : 76|4@0+ (1,0) [0|0] "-"  BDL
 SG_ MRMETSEL : 72|1@0+ (1,0) [0|0] "-"  BDL
 SG_ MRMETANS : 87|1@0+ (1,0) [0|0] "-"  BDL
 SG_ EXONPSH : 86|1@0+ (1,0) [0|0] "-"  BDL
 SG_ EXOFFPSH : 85|1@0+ (1,0) [0|0] "-"  BDL
 SG_ SMTRDYSW : 84|2@0+ (1,0) [0|0] "-"  BDL
 SG_ TMEXOP : 82|1@0+ (1,0) [0|0] "-"  BDL

BO_ 1086 AVN1SG5: 32 CDC
 SG_ ID6F820 : 7|8@0+ (1,0) [0|0] "-"  Vector_XXX
 SG_ IF6F820 : 15|8@0+ (1,0) [0|0] "-"  Vector_XXX
 SG_ A_SETSTS : 23|4@0+ (1,0) [0|0] "-"  DDM
 SG_ A_BPON : 47|1@0+ (1,0) [0|0] "-"  DDM
 SG_ A_BPWKD : 46|7@0+ (1,0) [0|0] "-"  DDM
 SG_ A_BPID : 55|3@0+ (1,0) [0|0] "-"  DDM
 SG_ A_DEPTM : 52|9@0+ (5,0) [0|0] "min"  DDM
 SG_ A_BPNXT : 59|2@0+ (1,0) [0|0] "-"  DDM
 SG_ A_BPSET : 57|1@0+ (1,0) [0|0] "-"  DDM
 SG_ A_ACSET : 56|1@0+ (1,0) [0|0] "-"  DDM
 SG_ ID6F821 : 71|8@0+ (1,0) [0|0] "-"  Vector_XXX
 SG_ IF6F821 : 79|8@0+ (1,0) [0|0] "-"  Vector_XXX
 SG_ A_NCTYP : 87|4@0+ (1,0) [0|0] "-"  DDM
 SG_ A_NCWKD : 83|3@0+ (1,0) [0|0] "-"  Vector_XXX
 SG_ A_NCSTM : 80|9@0+ (5,0) [0|0] "min"  Vector_XXX
 SG_ A_NCFTM : 103|9@0+ (5,0) [0|0] "min"  Vector_XXX
 SG_ A_SETID : 110|6@0+ (1,0) [0|0] "-"  DDM
 SG_ A_SETON : 104|1@0+ (1,0) [0|0] "-"  DDM
 SG_ A_SETWKD : 119|7@0+ (1,0) [0|0] "-"  DDM
 SG_ A_SETTYP : 112|4@0+ (1,0) [0|0] "-"  DDM
 SG_ A_SETSTM : 124|9@0+ (5,0) [0|0] "min"  DDM
 SG_ A_SETNXT : 131|6@0+ (1,0) [0|0] "-"  DDM
 SG_ A_SETFTM : 141|9@0+ (5,0) [0|0] "min"  DDM
 SG_ A_SETID2 : 148|6@0+ (1,0) [0|0] "-"  DDM
 SG_ A_SETON2 : 158|1@0+ (1,0) [0|0] "-"  DDM
 SG_ A_SETRE2 : 157|7@0+ (1,0) [0|0] "-"  DDM
 SG_ A_SETMO2 : 166|4@0+ (1,0) [0|0] "-"  DDM
 SG_ A_SETST2 : 162|9@0+ (5,0) [0|0] "minute"  DDM
 SG_ A_SETNX2 : 169|6@0+ (1,0) [0|0] "-"  DDM
 SG_ A_SETFT2 : 179|9@0+ (5,0) [0|0] "minute"  DDM
 SG_ A_LMTRE2 : 186|3@0+ (1,0) [0|0] "-"  DDM
 SG_ A_OCTID : 199|2@0+ (1,0) [0|0] "-"  DDM
 SG_ A_OCOKNG : 197|2@0+ (1,0) [0|0] "-"  DDM
 SG_ A_VPPREQ : 195|2@0+ (1,0) [0|0] "-"  DDM
 SG_ A_LMTACC : 193|3@0+ (1,0) [0|0] "-"  Vector_XXX

BO_ 1548 AVN1SG6: 32 CDC
 SG_ PVMINFO : 7|2@0+ (1,0) [0|0] "-"  ADC
 SG_ PVMERR : 5|2@0+ (1,0) [0|0] "-"  ADC
 SG_ MAVMUTE : 3|1@0+ (1,0) [0|0] "-"  ADC
 SG_ CS_FDIST : 2|2@0+ (1,0) [0|0] "-"  ADC
 SG_ CS_RDIST : 0|2@0+ (1,0) [0|0] "-"  ADC
 SG_ MOASW : 14|1@0+ (1,0) [0|0] "-"  ADC
 SG_ AUTOONAL : 13|1@0+ (1,0) [0|0] "-"  ADC
 SG_ RCD_DE : 12|1@0+ (1,0) [0|0] "-"  ADC
 SG_ CSR_WA : 11|1@0+ (1,0) [0|0] "-"  ADC
 SG_ PVMHSW : 10|1@0+ (1,0) [0|0] "-"  BDL
 SG_ PVM_WASH : 9|1@0+ (1,0) [0|0] "-"  BDL
 SG_ FCWCTSW : 28|2@0+ (1,0) [0|0] "-"  ADC
 SG_ FCWSESW : 26|3@0+ (1,0) [0|0] "-"  ADC
 SG_ CDWCTSW : 39|2@0+ (1,0) [0|0] "-"  ADC
 SG_ TLACTSW : 37|2@0+ (1,0) [0|0] "-"  ADC
 SG_ SLFCTSW : 35|2@0+ (1,0) [0|0] "-"  ADC
 SG_ CSWCTSW : 33|2@0+ (1,0) [0|0] "-"  ADC
 SG_ AESCTSW : 47|2@0+ (1,0) [0|0] "-"  ADC
 SG_ ACCCTSW : 45|2@0+ (1,0) [0|0] "-"  ADC
 SG_ CPCTSW : 43|2@0+ (1,0) [0|0] "-"  ADC
 SG_ LDKCTSW : 41|2@0+ (1,0) [0|0] "-"  ADC
 SG_ LDKSNSW : 55|2@0+ (1,0) [0|0] "-"  ADC
 SG_ ELKCTSW : 53|2@0+ (1,0) [0|0] "-"  ADC
 SG_ ELKMDSW : 51|3@0+ (1,0) [0|0] "-"  ADC
 SG_ GDNCTSW : 48|2@0+ (1,0) [0|0] "-"  ADC
 SG_ GDNWNSW : 62|2@0+ (1,0) [0|0] "-"  ADC
 SG_ GDNBKSW : 60|2@0+ (1,0) [0|0] "-"  ADC
 SG_ GDNSTSW : 58|2@0+ (1,0) [0|0] "-"  ADC
 SG_ GDNSNSW : 56|3@0+ (1,0) [0|0] "-"  ADC
 SG_ RCPMCTSW : 69|2@0+ (1,0) [0|0] "-"  ADC
 SG_ NPCS4SW : 67|2@0+ (1,0) [0|0] "-"  ADC
 SG_ NPCS5SW : 65|2@0+ (1,0) [0|0] "-"  ADC
 SG_ NPCS6SW : 79|2@0+ (1,0) [0|0] "-"  ADC
 SG_ NPCS7SW : 77|3@0+ (1,0) [0|0] "-"  ADC
 SG_ NPCS8SW : 74|5@0+ (1,0) [0|0] "-"  ADC
 SG_ NPCS9SW : 85|2@0+ (1,0) [0|0] "-"  ADC
 SG_ NPCS10SW : 83|3@0+ (1,0) [0|0] "-"  ADC
 SG_ NPCS11SW : 80|3@0+ (1,0) [0|0] "-"  ADC
 SG_ NPCS12SW : 93|2@0+ (1,0) [0|0] "-"  ADC
 SG_ NPCS13SW : 91|2@0+ (1,0) [0|0] "-"  ADC
 SG_ NPCS14SW : 89|2@0+ (1,0) [0|0] "-"  ADC
 SG_ NPCS15SW : 103|2@0+ (1,0) [0|0] "-"  ADC
 SG_ NPCS16SW : 101|2@0+ (1,0) [0|0] "-"  ADC
 SG_ NPCS17SW : 99|2@0+ (1,0) [0|0] "-"  ADC
 SG_ NPCS18SW : 97|2@0+ (1,0) [0|0] "-"  ADC
 SG_ NPCS19SW : 111|3@0+ (1,0) [0|0] "-"  ADC
 SG_ NPCS20SW : 108|3@0+ (1,0) [0|0] "-"  ADC
 SG_ ESSCTSW : 105|2@0+ (1,0) [0|0] "-"  ADC

BO_ 739 AVN1SH1: 32 CDC
 SG_ GRLGDBOP : 3|3@0+ (1,0) [0|0] "-"  DDM
 SG_ CNV1_SW : 135|1@0+ (1,0) [0|0] "-"  DDM
 SG_ CNV2_SW : 134|1@0+ (1,0) [0|0] "-"  DDM
 SG_ CNV3_SW : 133|1@0+ (1,0) [0|0] "-"  DDM
 SG_ CNV4_SW : 132|1@0+ (1,0) [0|0] "-"  DDM
 SG_ CNV5_SW : 131|1@0+ (1,0) [0|0] "-"  DDM
 SG_ CNV6_SW : 130|1@0+ (1,0) [0|0] "-"  DDM
 SG_ CNV7_SW : 129|1@0+ (1,0) [0|0] "-"  DDM
 SG_ CNV8_SW : 128|1@0+ (1,0) [0|0] "-"  DDM
 SG_ CNV9_SW : 143|1@0+ (1,0) [0|0] "-"  DDM
 SG_ CNV10_SW : 142|1@0+ (1,0) [0|0] "-"  DDM
 SG_ CNV11_SW : 141|1@0+ (1,0) [0|0] "-"  DDM
 SG_ CNV12_SW : 140|1@0+ (1,0) [0|0] "-"  DDM
 SG_ CNV13_SW : 139|1@0+ (1,0) [0|0] "-"  DDM
 SG_ CNV14_SW : 138|1@0+ (1,0) [0|0] "-"  DDM
 SG_ CNV15_SW : 137|1@0+ (1,0) [0|0] "-"  DDM
 SG_ CNV16_SW : 136|1@0+ (1,0) [0|0] "-"  DDM

BO_ 532 BAT1E41: 32 DDM
 SG_ ABPCH : 6|15@0+ (5,0) [0|0] "Wh"  CDC
 SG_ CBPCH : 22|15@0+ (5,0) [0|0] "Wh"  CDC
 SG_ BATCI : 39|2@0+ (1,0) [0|0] "%"  CDC
 SG_ FULLCAPR : 68|13@0+ (0.1,0) [0|0] "Ah"  CDC
 SG_ BATTYPER : 87|5@0+ (1,0) [0|0] "-"  CDC
 SG_ SOC_GR : 81|10@0- (0.1,0) [0|0] "%"  CDC
 SG_ TBMAX_GR : 103|8@0- (1,0) [0|0] "degC"  CDC
 SG_ TBMIN_GR : 111|8@0- (1,0) [0|0] "degC"  CDC
 SG_ RBSCC_A : 135|16@0- (1E-008,0) [0|0] "-"  CDC
 SG_ RBSCC_B : 151|16@0- (1E-008,0) [0|0] "-"  CDC
 SG_ RBSCC_C : 167|16@0- (1E-008,0) [0|0] "-"  CDC
 SG_ RBSCC_D : 183|16@0- (1E-008,0) [0|0] "-"  CDC

BO_ 366 BAT1E45: 32 DDM
 SG_ BIB_G : 7|16@0+ (0.1,-3276.7) [0|0] "A"  BGW,CDC
 SG_ VCELMAXG : 23|12@0+ (0.00122100122100122,0) [0|0] "V"  BGW,CDC
 SG_ VCELMING : 27|12@0+ (0.00122100122100122,0) [0|0] "V"  BGW,CDC
 SG_ RAHRMAXG : 47|10@0+ (0.1,0) [0|0] "%"  BGW,CDC
 SG_ RAHRMING : 53|10@0+ (0.1,0) [0|0] "%"  BGW,CDC
 SG_ TC_G : 71|8@0- (1,0) [0|0] "degC"  BGW,CDC
 SG_ TBMAX_G : 79|8@0- (1,0) [0|0] "degC"  BGW,CDC
 SG_ TBMIN_G : 87|8@0- (1,0) [0|0] "degC"  BGW,CDC

BO_ 997 BAT1S01: 32 DDM
 SG_ BS_CHK_B : 2|3@0+ (1,0) [0|0] "-"  BGW,CDC
 SG_ BHEATSW : 23|2@0+ (1,0) [0|0] "-"  BGW,CDC
 SG_ BCOOLSW : 21|2@0+ (1,0) [0|0] "-"  BGW,CDC
 SG_ TBW_EN : 19|1@0+ (1,0) [0|0] "-"  BGW,CDC
 SG_ CHGLMTDA : 49|1@0+ (1,0) [0|0] "-"  BGW,CDC
 SG_ FCHGSUG : 48|1@0+ (1,0) [0|0] "-"  BGW,CDC
 SG_ LBTYPE_E : 62|4@0+ (1,0) [0|0] "-"  BGW,CDC

BO_ 292 BAT1S08: 8 DDM
 SG_ BTWO : 23|9@0+ (0.5,-50) [0|0] "degC"  CDC

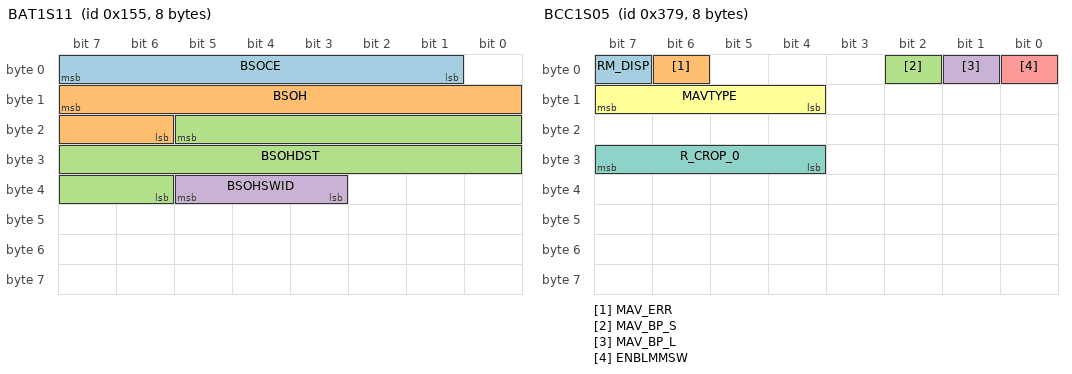
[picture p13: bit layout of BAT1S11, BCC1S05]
BO_ 341 BAT1S11: 8 DDM
 SG_ BSOCE : 7|7@0+ (1,0) [0|0] "%"  BGW,CDC
 SG_ BSOH : 15|10@0+ (0.1,0) [0|0] "%"  BGW,CDC
 SG_ BSOHDST : 21|16@0+ (1,0) [0|0] "km"  BGW,CDC
 SG_ BSOHSWID : 37|3@0+ (1,0) [0|0] "-"  BGW,CDC

BO_ 889 BCC1S05: 8 ADC
 SG_ RM_DISP : 7|1@0+ (1,0) [0|0] "-"  CDC
 SG_ MAV_ERR : 6|1@0+ (1,0) [0|0] "-"  CDC
 SG_ MAV_BP_S : 2|1@0+ (1,0) [0|0] "-"  CDC
 SG_ MAV_BP_L : 1|1@0+ (1,0) [0|0] "-"  CDC
 SG_ ENBLMMSW : 0|1@0+ (1,0) [0|0] "-"  CDC
 SG_ MAVTYPE : 15|4@0+ (1,0) [0|0] "-"  CDC
 SG_ R_CROP_0 : 31|4@0+ (1,0) [0|0] "-"  CDC

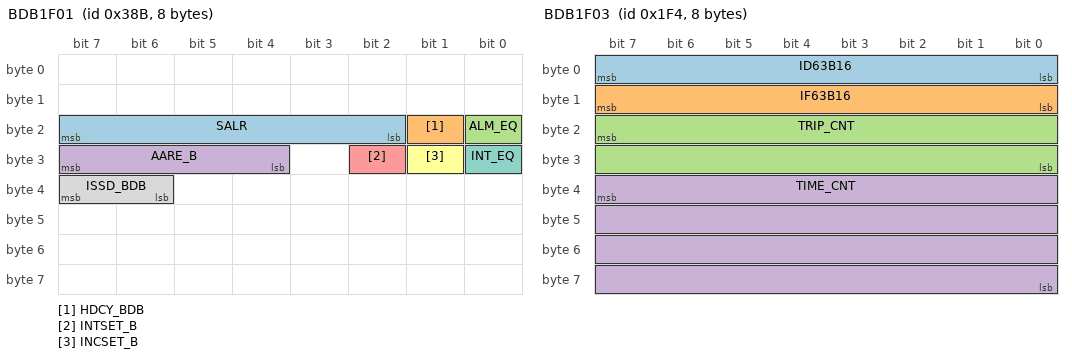
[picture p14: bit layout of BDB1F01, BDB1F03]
BO_ 907 BDB1F01: 8 BDL
 SG_ SALR : 23|6@0+ (1,0) [0|0] "-"  CDC,DDM
 SG_ HDCY_BDB : 17|1@0+ (1,0) [0|0] "-"  BGW,CDC
 SG_ ALM_EQ : 16|1@0+ (1,0) [0|0] "-"  BGW,CDC,DDM
 SG_ AARE_B : 31|4@0+ (1,0) [0|0] "-"  BGW,CDC,DDM
 SG_ INTSET_B : 26|1@0+ (1,0) [0|0] "-"  BGW,CDC,DDM
 SG_ INCSET_B : 25|1@0+ (1,0) [0|0] "-"  BGW,CDC,DDM
 SG_ INT_EQ : 24|1@0+ (1,0) [0|0] "-"  BGW,CDC,DDM
 SG_ ISSD_BDB : 39|2@0+ (1,0) [0|0] "-"  BGW,CDC,DDM

BO_ 909 BDB1F02: 8 BDL
 SG_ DPM_R1 : 7|2@0+ (1,0) [0|0] "-"  CDC
 SG_ DPM_R2 : 5|2@0+ (1,0) [0|0] "-"  CDC
 SG_ DPM_R3 : 3|2@0+ (1,0) [0|0] "-"  CDC
 SG_ DPP_R1 : 1|2@0+ (1,0) [0|0] "-"  CDC
 SG_ DPP_R2 : 15|2@0+ (1,0) [0|0] "-"  CDC
 SG_ DPP_R3 : 13|2@0+ (1,0) [0|0] "-"  CDC
 SG_ DPMS_INT : 11|2@0+ (1,0) [0|0] "-"  CDC
 SG_ DPM1_FNC : 9|1@0+ (1,0) [0|0] "-"  CDC
 SG_ DPM1_VLD : 8|1@0+ (1,0) [0|0] "-"  CDC
 SG_ DPS1_VLD : 23|1@0+ (1,0) [0|0] "-"  CDC
 SG_ DPM2_FNC : 22|1@0+ (1,0) [0|0] "-"  CDC
 SG_ DPM2_VLD : 21|1@0+ (1,0) [0|0] "-"  CDC
 SG_ DPS2_VLD : 20|1@0+ (1,0) [0|0] "-"  CDC
 SG_ DPM3_FNC : 19|1@0+ (1,0) [0|0] "-"  CDC
 SG_ DPM3_VLD : 18|1@0+ (1,0) [0|0] "-"  CDC
 SG_ DPS3_VLD : 17|1@0+ (1,0) [0|0] "-"  CDC
 SG_ DRVPS_DT : 27|4@0+ (1,0) [0|0] "-"  CDC
 SG_ HUD_R : 61|2@0+ (1,0) [0|0] "-"  CDC

BO_ 500 BDB1F03: 8 BDL
 SG_ ID63B16 : 7|8@0+ (1,0) [0|0] "-"  BGW,CDC,DDM
 SG_ IF63B16 : 15|8@0+ (1,0) [0|0] "-"  BGW,CDC,DDM
 SG_ TRIP_CNT : 23|16@0+ (1,0) [0|0] "trip"  CDC
 SG_ TIME_CNT : 39|32@0+ (100,0) [0|0] "ms"  CDC

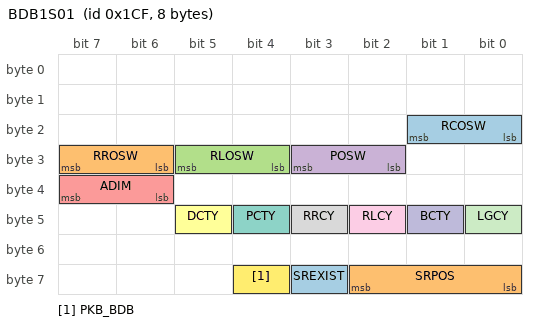
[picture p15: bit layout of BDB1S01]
BO_ 463 BDB1S01: 8 BDL
 SG_ RCOSW : 17|2@0+ (1,0) [0|0] "-"  BGW,CDC,DDM
 SG_ RROSW : 31|2@0+ (1,0) [0|0] "-"  BGW,CDC,DDM
 SG_ RLOSW : 29|2@0+ (1,0) [0|0] "-"  BGW,CDC,DDM
 SG_ POSW : 27|2@0+ (1,0) [0|0] "-"  BGW,CDC,DDM
 SG_ ADIM : 39|2@0+ (1,0) [0|0] "-"  BGW,CDC,DDM
 SG_ DCTY : 45|1@0+ (1,0) [0|0] "-"  BGW,CDC
 SG_ PCTY : 44|1@0+ (1,0) [0|0] "-"  BGW,CDC
 SG_ RRCY : 43|1@0+ (1,0) [0|0] "-"  BGW,CDC
 SG_ RLCY : 42|1@0+ (1,0) [0|0] "-"  BGW,CDC
 SG_ BCTY : 41|1@0+ (1,0) [0|0] "-"  BGW,CDC
 SG_ LGCY : 40|1@0+ (1,0) [0|0] "-"  BGW,CDC,DDM
 SG_ PKB_BDB : 60|1@0+ (1,0) [0|0] "-"  BGW,CDC
 SG_ SREXIST : 59|1@0+ (1,0) [0|0] "-"  BGW,CDC,DDM
 SG_ SRPOS : 58|3@0+ (1,0) [0|0] "-"  BGW,CDC,DDM

BO_ 1569 BDB1S02: 8 BDL
 SG_ LUD : 23|8@0+ (1,0) [0|0] "-"  CDC

CM_ BO_ 1196 "Reserve";
CM_ SG_ 1196 DRABG01 "Diagnosis Recorder ABG01";
CM_ SG_ 1196 DRABG02 "Diagnosis Recorder ABG02";
CM_ SG_ 1196 DRABG03 "Diagnosis Recorder ABG03";
CM_ SG_ 1196 DRABG04 "Diagnosis Recorder ABG04";
CM_ SG_ 1196 DRABG05 "Diagnosis Recorder ABG05";
CM_ SG_ 1196 DRABG06 "Diagnosis Recorder ABG06";
CM_ SG_ 1196 DRABG07 "Diagnosis Recorder ABG07";
CM_ SG_ 1196 DRABG08 "Diagnosis Recorder ABG08";
CM_ BO_ 1212 "Reserve";
CM_ SG_ 1212 DRABG09 "Diagnosis Recorder ABG09";
CM_ SG_ 1212 DRABG10 "Diagnosis Recorder ABG10";
CM_ SG_ 1212 DRABG11 "Diagnosis Recorder ABG11";
CM_ SG_ 1212 DRABG12 "Diagnosis Recorder ABG12";
CM_ SG_ 1212 DRABG13 "Diagnosis Recorder ABG13";
CM_ SG_ 1212 DRABG14 "Diagnosis Recorder ABG14";
CM_ SG_ 1212 DRABG15 "Diagnosis Recorder ABG15";
CM_ SG_ 1212 DRABG16 "Diagnosis Recorder ABG16";
CM_ BO_ 945 "Reserve";
CM_ SG_ 945 SCSACCEL "SCB Acceleration Supression Request";
CM_ SG_ 945 SCSBZR "SCB Buzzer Request";
CM_ SG_ 945 CDT_SCN1 "crash scene 1 detection signal";
CM_ SG_ 945 DBKLAB "Driver's seat belt buckle switch status";
CM_ SG_ 945 PBKLAB "Passenger's seat belt buckle switch status";
CM_ BO_ 1208 "Reserve";
CM_ SG_ 1208 DRACN01 "Drive Recorder ACN01";
CM_ SG_ 1208 DRACN02 "Drive Recorder ACN02";
CM_ SG_ 1208 DRACN03 "Drive Recorder ACN03";
CM_ SG_ 1208 DRACN04 "Drive Recorder ACN04";
CM_ SG_ 1208 DRACN05 "Drive Recorder ACN05";
CM_ SG_ 1208 DRACN06 "Drive Recorder ACN06";
CM_ SG_ 1208 DRACN07 "Drive Recorder ACN07";
CM_ SG_ 1208 DRACN08 "Drive Recorder ACN08";
CM_ BO_ 929 "Reserve";
CM_ SG_ 929 O_STG_F "Steering Heater drive request signal";
CM_ SG_ 929 AC_CDSP "ACN MODE signal(EV DRIVE DISTANCE)";
CM_ BO_ 897 "Reserve";
CM_ SG_ 897 R_ACCALL "A/C Display request signal";
CM_ SG_ 897 R_AC_WNG "A/C Warning On-screen request signal";
CM_ SG_ 897 R_SW_CON "SW state control request";
CM_ SG_ 897 I_RA_AUT "Rear A/C_AIRPURIFIER AUTO INDICATOR signal";
CM_ SG_ 897 I_RA_AC "Rear A/C_AIRPURIFIER A/C INDICATOR signal";
CM_ SG_ 897 I_RA_LO "Rear A/C_AIRPURIFIER LO INDICATOR signal";
CM_ SG_ 897 I_RA_HI "Rear A/C_AIRPURIFIER HI INDICATOR signal";
CM_ SG_ 897 I_AUTO_D "Dr AUTO INDICATOR signal";
CM_ SG_ 897 I_AUTO_P "Pa AUTO INDICATOR signal";
CM_ SG_ 897 I_DEF "DEF INDICATOR signal";
CM_ SG_ 897 I_RRDEF "RrDEF INDICATOR signal";
CM_ SG_ 897 I_RFAUT "INLET AUTO INDICATOR signal";
CM_ SG_ 897 I_REC "REC INDICATOR signal";
CM_ SG_ 897 I_FRS "FRS INDICATOR signal";
CM_ SG_ 897 I_AC "A/C INDICATOR signal";
CM_ SG_ 897 I_MHTR "MIRROR HEATER INDICATOR signal";
CM_ SG_ 897 I_WIPD "DEICER INDICATOR signal";
CM_ SG_ 897 I_DUSY "Dual/SYNC INDICATOR signal";
CM_ SG_ 897 I_SWNG "SWING INDICATOR signal";
CM_ SG_ 897 I_BLW_F "Front Blower Level INDICATOR signal";
CM_ SG_ 897 I_OAUT_D "DrOLET-AUTO INDICATOR signal";
CM_ SG_ 897 I_OLET_D "Dr OLET INDICATOR signal";
CM_ SG_ 897 I_OAUT_P "PaOLET-AUTO INDICATOR signal";
CM_ SG_ 897 I_OLET_P "Pa OLET INDICATOR signal";
CM_ SG_ 897 ST_BMN_F "Fr BLW MANUAL status";
CM_ SG_ 897 I_CONCEN "Indicator signal that shows concentration on one seat";
CM_ SG_ 897 I_NANOE "Nano-E indicator signal";
CM_ SG_ 897 I_CONCIE "Climate Concierge indicator signal";
CM_ SG_ 897 I_BLWCUS "Blower Custom INDICATOR signal";
CM_ SG_ 897 I_AIRPR "AIRPURIFIER INDICATOR signal";
CM_ SG_ 897 I_PLSM "PLASMA CLUSTER INDICATOR signal";
CM_ SG_ 897 I_KAFUN "POLLEN REMOVE INDICATOR signal";
CM_ SG_ 897 R_ONSCRN "A/C ON-SCREEN request signal";
CM_ SG_ 897 I_OLET_I "OLET INDICATOR signal for IT cooperation";
CM_ SG_ 897 I_PLSYNC "PARTIL SYNC STATUS INDICATOR signal";
CM_ SG_ 897 I_RFAUTT "INLET AUTO INDICATOR signal(TAO AUTO)";
CM_ SG_ 897 R_SFLOWS "Request Sflow Status";
CM_ SG_ 897 I_ACAUTO "A/C AUTO INDICATOR signal";
CM_ SG_ 897 R_ECODSP "A/C ECO DISP request signal";
CM_ SG_ 897 SL_ACDSP "A/C SCREEN Select information";
CM_ SG_ 897 SL_DUSY "SW DESIGN DUAL/SYNC. Select information";
CM_ SG_ 897 SL_DFRAD "FrDrRadiant Heater select information";
CM_ SG_ 897 SL_CIF "TEMPERATURE UNIT Select information";
CM_ SG_ 897 SL_BLW_F "Front BLOWER STEP Select information";
CM_ SG_ 897 SL_SRLVL "SPEECH RECOGNITION Level information";
CM_ SG_ 897 SL_RR_IH "REAR CONTROL INHIBIT SW Select information";
CM_ SG_ 897 SL_RAUTO "RrAUTO SW Select information";
CM_ SG_ 897 SL_BLW_R "Rear BLOWER STEP Select information";
CM_ SG_ 897 SL_DST "DISTINATION Select information";
CM_ SG_ 897 SL_WIPD "DEICER SW Select information";
CM_ SG_ 897 SL_MRHT "MIRROR HEATER SW Select information";
CM_ SG_ 897 SL_AIRP "AIRPURIFIER SW Select information";
CM_ SG_ 897 SL_PFRAD "FrPaRadiant Heater select information";
CM_ SG_ 897 SL_PLSM "PLASMA CLUSTER  SW Select information";
CM_ SG_ 897 SL_KAFUN "POLLEN REMOVE Select information";
CM_ SG_ 897 SL_SWNG "SWING SW Select information";
CM_ SG_ 897 ST_CN_OK "CONTROL INFORMATION Status";
CM_ SG_ 897 SL_FSVTP "Front Seat Ventilater Type information";
CM_ SG_ 897 SL_FSTYP "Front Seat Heater Type information";
CM_ SG_ 897 SL_NANOE "Nano-E SW select information";
CM_ SG_ 897 SL_RSEAT "RearSEAT HEATER SW select information";
CM_ SG_ 897 SL_SFLOW "SFLOW SW Select information";
CM_ SG_ 897 SL_ACST "A/C SYSTEM Type information";
CM_ SG_ 897 SL_AC_AM "A/C SCREEN AUTO/MANUAL Select information";
CM_ SG_ 897 SL_RBLW "Rear BLOWER SW select information";
CM_ SG_ 897 SL_ROFF "Rear OFF SW select information";
CM_ SG_ 897 SL_BLCUS "Blower Custom SW select information";
CM_ SG_ 897 SL_ACECO "A/C ECO SW select information";
CM_ SG_ 897 SL_RFSW "R/F SW select information";
CM_ SG_ 897 SL_CONCI "Climate Concierge SW select information";
CM_ SG_ 897 SL_NECK "Neck Heater select information";
CM_ SG_ 897 SL_RACIH "RrA/C inhibit information";
CM_ SG_ 897 SL_ZOSY "SW DESIGN ZONE/SYNC. Select information";
CM_ SG_ 897 SL_STHAT "Steering Heater Auto select information";
CM_ SG_ 897 SL_3RD_S "3RD SEAT select information";
CM_ SG_ 897 SL_RSBLW "Rear SEAT BLW SW select information";
CM_ SG_ 897 SL_STR_H "Steering Heater SW select information";
CM_ SG_ 897 SL_NAVI "A/C R/F collaborated with NAVI information";
CM_ SG_ 897 SL_FSEAT "Front Seat blower and Heater SW infomation";
CM_ SG_ 897 I_AUT_RR "RearRight AUTO INDICATOR signal";
CM_ SG_ 897 I_AUT_RL "RearLeft AUTO INDICATOR signal";
CM_ SG_ 897 I_CNT_IH "Rear Control Inhibit INDICATOR signal";
CM_ SG_ 897 I_RAUTO "RrAUTO INDICATOR signal";
CM_ SG_ 897 ST_BMN_R "Rr BLW MANUAL status";
CM_ SG_ 897 I_RBLCUS "Rr Blower Custom INDICATOR signal";
CM_ SG_ 897 I_OAUTRL "RrL OLET-AUTO INDICATOR signal";
CM_ SG_ 897 I_OAUTRR "RrR OLET-AUTO INDICATOR signal";
CM_ SG_ 897 I_BLW_R "Rear Blower Level INDICATOR signal";
CM_ SG_ 897 R_RONSCR "RrA/C ON-SCREEN request signal";
CM_ SG_ 897 I_OLT_RR "RearRight OLET INDICATOR signal";
CM_ SG_ 897 I_RACON "Rear Manual Air-Conditioner Indicator Signal";
CM_ SG_ 897 I_OLT_RL "RearLeft OLET INDICATOR signal";
CM_ SG_ 897 B_DCMOD1 "A/C drive mode serect signal infomation";
CM_ SG_ 897 B_DCMOD2 "A/C drive mode serect signal support information";
CM_ SG_ 897 B_DCMOD3 "A/C drive mode serect status";
CM_ SG_ 897 I_TMP_RR "RearRight or Rear TEMPERATURE Display signal";
CM_ SG_ 897 I_TMP_RL "RearLeft TEMPERATURE Display signal";
CM_ SG_ 897 I_BCOLRL "RrL Blower Temperature display signal";
CM_ SG_ 897 I_BCOLRR "RrR Blower Temperature display signal";
CM_ SG_ 897 I_BCOLPA "Pa Blower Temperature display signal";
CM_ SG_ 897 I_BCOLDR "Dr Blower Temperature display signal";
CM_ SG_ 897 M_OLT_PA "Pa OLET INDICATOR signal for climaite concierge monitor";
CM_ SG_ 897 M_OLT_DR "Dr OLET INDICATOR signal for climaite concierge monitor";
CM_ SG_ 897 M_OLT_RL "RrL OLET INDICATOR signal for climaite concierge monitor";
CM_ SG_ 897 M_OLT_RR "RrR OLET INDICATOR signal for climaite concierge monitor";
CM_ SG_ 897 RL_SBL "RrL Seat Blower Level display";
CM_ SG_ 897 RL_SHL "RrL Seat Heater Level display";
CM_ SG_ 897 RR_SBL "RrR Seat Blower Level display";
CM_ SG_ 897 RR_SHL "RrR Seat Heater Level display";
CM_ SG_ 897 I_STHLVL "Steering Heater Level display";
CM_ SG_ 897 I_SAUTRL "RrL CLIMATE CONTROL SEAT AUTO INDICATOR signal";
CM_ SG_ 897 I_SAUTRR "RrR CLIMATE CONTROL SEAT AUTO INDICATOR signal";
CM_ SG_ 897 R_DSP_SH "SEAT CLIMATE DISPLAY request signal";
CM_ SG_ 897 I_SAUT_P "Pa CLIMATE CONTROL SEAT AUTO INDICATOR signal";
CM_ SG_ 897 I_SAUT_D "Dr CLIMATE CONTROL SEAT AUTO INDICATOR signal";
CM_ SG_ 897 I_STHAUT "Steering Heater AUTO INDICATOR signal";
CM_ SG_ 897 PF_SBL "Pa Fr Seat Blower Level display";
CM_ SG_ 897 PF_SHL "Pa Fr Seat Heater Level display";
CM_ SG_ 897 DF_SBL "Dr Fr Seat Blower Level display";
CM_ SG_ 897 DF_SHL "Dr Fr Seat Heater Level display";
CM_ SG_ 897 DF_NHL "Dr Fr Neck Heater Level Indicator";
CM_ SG_ 897 PF_NHL "Pa Fr Neck Heater Level Indicator";
CM_ SG_ 897 I_NH_LIM "Neck Heater Restricted State";
CM_ SG_ 897 I_NAUT_D "Dr Fr Neck Heater Auto Indicator";
CM_ SG_ 897 I_NAUT_P "Pa Fr Neck Heater Auto Indicator";
CM_ BO_ 898 "Reserve";
CM_ SG_ 898 I_TMP_D "Dr TEMPERATURE Display signal";
CM_ SG_ 898 I_TMP_P "Pa TEMPERATURE Display signal";
CM_ SG_ 898 ACN_ENE "A/C Energy Level";
CM_ SG_ 898 I_ACECO "A/C ECO Status INDICATOR signal";
CM_ SG_ 898 I_DSPR "Dr seat priority INDICATOR request signal";
CM_ BO_ 944 "Reserve";
CM_ SG_ 944 RDEF "RrDEF drive request signal";
CM_ SG_ 944 MHTR "Mirror Heater drive request signal";
CM_ SG_ 944 S_CLMT "Climate shortcut sw information";
CM_ SG_ 944 CLE_RECF "Cloud Eco for recirculation execution flag signal";
CM_ SG_ 944 TR_TEMP "In-Vehicle temperature signal";
CM_ SG_ 944 EVA_FBP "Evaporator water retention feedback signal for pre airconditioning signal";
CM_ SG_ 944 AC_OUTT "Air conditioning output target signal";
CM_ SG_ 944 ES_RHW "Estimated humidity signal";
CM_ SG_ 944 I_RRSEAT "Rear SEAT HEATER INDICATOR signal";
CM_ SG_ 944 AC_MODE "A/C control state signal";
CM_ SG_ 944 SL_HP "HEAT PUMP select information";
CM_ SG_ 944 TAO_FLG "Outlet target temperature flag signal";
CM_ SG_ 944 ACL_WRN "A/C Load Limitation Warning";
CM_ BO_ 1031 "Reserve";
CM_ SG_ 1031 TRTEMP_P "In-Vehicle temperature signal";
CM_ SG_ 1031 I_BLWF_P "Front Blower Level INDICATOR signal";
CM_ BO_ 1032 "Reserve";
CM_ SG_ 1032 COMPRP_P "Electromotion Compressor Target revolutions signal";
CM_ SG_ 1032 PRACAC_P "Pre-A/C mode signal";
CM_ SG_ 1032 AC_USEPW "A/C use power";
CM_ BO_ 852 "Reserve";
CM_ SG_ 852 I_EXT "Exhaust gas indicator signal";
CM_ SG_ 852 PM_REN "PM concentration renewal signal";
CM_ SG_ 852 PM_ST "PM removal System state";
CM_ SG_ 852 I_PM "PM removal INDICATOR signal";
CM_ SG_ 852 SL_PM "PM concentration select information";
CM_ SG_ 852 I_PMD "PM concentration Display(Number)";
CM_ SG_ 852 I_FRC2 "Fragrance Cartridge Type signal(case2)";
CM_ SG_ 852 I_FRC1 "Fragrance Cartridge Type signal(case1)";
CM_ SG_ 852 I_RFRS "Fragrance Strength Indicator signal(Refresh)";
CM_ SG_ 852 I_WFRS "Fragrance Strength Indicator signal(Welcome)";
CM_ SG_ 852 I_FRIS "Fragrance System Indicator signal";
CM_ SG_ 852 SL_FR "Fragrance System select information";
CM_ SG_ 852 ST_ACAGT "A/C agent state signal";
CM_ SG_ 852 I_FRST "Fragrance State Indicator signal";
CM_ SG_ 852 I_RFRC "Fragrance Case Select signal(Refresh)";
CM_ SG_ 852 I_WFRC "Fragrance Case Select signal(Welcome)";
CM_ SG_ 852 SL_TCS "TIACS system select information   ";
CM_ SG_ 852 SL_EXT "Exhaust gas system select information";
CM_ SG_ 852 SL_ACAGT "A/C Agent Select information";
CM_ SG_ 852 ST_EMEN "Enable state of Emotion";
CM_ SG_ 852 ST_AWKEN "Enable state of Awakening";
CM_ SG_ 852 SL_RSTYP "Rear Seat Heater Type information";
CM_ SG_ 852 SL_SYNC "SYNC Equipment Information";
CM_ SG_ 852 TCS_ST "TIACS system state";
CM_ SG_ 852 R_RFPHBT "Inlet Control Propriety";
CM_ SG_ 852 SL_RSVTP "Rear Seat Ventilater Type information";
CM_ SG_ 852 FG_CH1_L "Fragrance channel1 level information";
CM_ SG_ 852 FG_CH1_D "Fragrance channel1 distinguish information";
CM_ SG_ 852 FG_CH1_T "Fragrance channel1 type information";
CM_ SG_ 852 FG_CH2_L "Fragrance channel2 level information";
CM_ SG_ 852 FG_CH2_D "Fragrance channel2 distinguish information";
CM_ SG_ 852 FG_CH2_T "Fragrance channel2 type information";
CM_ SG_ 852 FG_CH3_L "Fragrance channel3 level information";
CM_ SG_ 852 FG_CH3_D "Fragrance channel1 distinguish information";
CM_ SG_ 852 FG_CH3_T "Fragrance channel3 type information";
CM_ SG_ 852 FG_UV_E "Fragrance lowvoltage error ";
CM_ SG_ 852 FG_OV_E "Fragrance overvoltage error ";
CM_ SG_ 852 FG_MOT_E "Fragrance moter error status";
CM_ SG_ 852 FG_FAN_E "Fragrance fan error status";
CM_ SG_ 852 FG_EMP "Fragrance cartridge empty information";
CM_ SG_ 852 FG_CHA_E "Fragrance type changing status";
CM_ SG_ 852 SL_FGST "fragrance equipment information";
CM_ SG_ 852 I_FG_PW "Fragrance switch status information";
CM_ SG_ 852 I_FG_LVL "Fragrance potensy selection status ";
CM_ SG_ 852 I_FG_CH "Fragrance channel selection status";
CM_ BO_ 597 "Reserve";
CM_ SG_ 597 HQ_COMP "Heat quantity of Compressor ";
CM_ BO_ 1286 "Reserve";
CM_ SG_ 1286 R_SHHTFL "FrL Seat Heater Drive Request ON(HI)";
CM_ SG_ 1286 R_SHHTFR "FrR Seat Heater Drive Request ON(HI) Valid";
CM_ SG_ 1286 RSVFLDU "FrL Seat Ventilation Blower Duty Drive Request";
CM_ SG_ 1286 RSVFRDU "FrR Seat Ventilation Blower Duty Drive Request";
CM_ SG_ 1286 R_SHHTRL "RrL Seat Heater Drive Request ON";
CM_ SG_ 1286 R_SHHTRR "RrR Seat Heater Drive Request ON";
CM_ SG_ 1286 RSVRLDU "RrL Seat Ventilation Blower Duty Drive Request";
CM_ SG_ 1286 RSVRRDU "RrR Seat Ventilation Blower Duty Drive Request";
CM_ SG_ 1286 R_RDHRR "RrR Radient Heater Drive";
CM_ SG_ 1286 R_RDHRL "RrL Radient Heater Drive";
CM_ SG_ 1286 R_RDHFP "Pa Radient Heater Drive";
CM_ SG_ 1286 R_RDHFD "Dr Radient Heater Drive";
CM_ BO_ 382 "Reserve";
CM_ SG_ 382 RCPSYS "RCP System Avaible";
CM_ BO_ 519 "Reserve";
CM_ SG_ 519 VCDSP_2 "Switching display request of voice";
CM_ SG_ 519 PCDSP_2 "Switching display request of external camera image";
CM_ SG_ 519 GCDSP_2 "Switching display request of location information";
CM_ SG_ 519 TRNEXIST "ADAS Training Mode Exist";
CM_ SG_ 519 TRNACT "ADAS Training Mode Activate Request";
CM_ SG_ 519 TRNCEO "ADAS Training Mode Explanation Overall";
CM_ SG_ 519 TRNED "ADAS Training Mode Explanation Detail";
CM_ SG_ 519 TRNEPR "ADAS Training Mode Explanation Picture Right";
CM_ SG_ 519 TRNPEPL "ADAS Training Mode Explanation Picture Left";
CM_ SG_ 519 TRNJ "ADAS Training Mode Judgement";
CM_ SG_ 519 TRNCS "ADAS Training Mode Countdown Start";
CM_ SG_ 519 TRNCN "ADAS Training Mode Countdown Numbers";
CM_ SG_ 519 TRNCI "ADAS Training Mode Countdown Instruction";
CM_ SG_ 519 TRNPB "ADAS Training Mode Progress Bar";
CM_ SG_ 519 TRNGJ "ADAS Training Mode Great Judgement";
CM_ SG_ 519 TRNME "ADAS Training Mode Meter Explanation";
CM_ SG_ 519 TRNMI "ADAS Training Mode Meter Indication";
CM_ SG_ 519 TRNDP "ADAS Training Mode Driving Picture";
CM_ SG_ 519 TRNMET1 "ADAS Training Mode MET Show 1";
CM_ SG_ 519 TRNMET2 "ADAS Training Mode MET Show 2";
CM_ SG_ 519 TRNJP "ADAS Training Mode Judgement Progress";
CM_ SG_ 519 TRNVUR "ADAS Training Mode Guidance Notification Request";
CM_ SG_ 519 TRNJPE "ADAS Training Mode Judgement Progress Evaluation";
CM_ SG_ 519 TRNMMDIS "ADAS Training MM Display Request";
CM_ SG_ 519 TRNBUT "ADAS Training Button Display Request";
CM_ SG_ 519 TRNVUEX "ADAS Training Guidance Notification Exist";
CM_ SG_ 519 TRNAS "ADAS Training Mode Alert Sounds";
CM_ SG_ 519 TRNCI1 "ADAS Training Mode Cut In 1";
CM_ SG_ 519 TRNFE "ADAS Training Mode Function Exist";
CM_ SG_ 519 TRNSEI "ADAS Training Mode Switch Enable Information";
CM_ SG_ 519 TRNPC1 "ADAS Training Mode Progress And Completion Information1";
CM_ SG_ 519 TRNPC2 "ADAS Training Mode Progress And Completion Information2";
CM_ SG_ 519 TRNPC3 "ADAS Training Mode Progress And Completion Information3";
CM_ SG_ 519 TRNPC4 "ADAS Training Mode Progress And Completion Information4";
CM_ SG_ 519 TRNPC5 "ADAS Training Mode Progress And Completion Information5";
CM_ SG_ 519 TRNPC6 "ADAS Training Mode Progress And Completion Information6";
CM_ SG_ 519 TRNPC7 "ADAS Training Mode Progress And Completion Information7";
CM_ SG_ 519 TRNPC8 "ADAS Training Mode Progress And Completion Information8";
CM_ SG_ 519 TRNSE1 "ADAS Training Mode Scenario Exist Information1";
CM_ SG_ 519 TRNSE2 "ADAS Training Mode Scenario Exist Information2";
CM_ SG_ 519 TRNSE3 "ADAS Training Mode Scenario Exist Information3";
CM_ SG_ 519 TRNSE4 "ADAS Training Mode Scenario Exist Information4";
CM_ SG_ 519 TRNSE5 "ADAS Training Mode Scenario Exist Information5";
CM_ SG_ 519 TRNSE6 "ADAS Training Mode Scenario Exist Information6";
CM_ SG_ 519 TRNSE7 "ADAS Training Mode Scenario Exist Information7";
CM_ SG_ 519 TRNSE8 "ADAS Training Mode Scenario Exist Information8";
CM_ SG_ 519 TRNISR "ADAS Training Mode Introduction Start Request";
CM_ SG_ 519 TRNESR "ADAS Training Mode Ending Start Request";
CM_ SG_ 519 TRNHDR "ADAS Training Mode Home Screen Display Request";
CM_ SG_ 519 TRNMR1 "ADAS Training Mode MM Display Request 1";
CM_ SG_ 519 TRNMR2 "ADAS Training Mode MM Display Request 2";
CM_ BO_ 523 "Reserve";
CM_ SG_ 523 AMCONPVM "Operating condition of approach detection mode";
CM_ SG_ 523 DRADCABN "Drive recorder(ADU) malfunction notification";
CM_ SG_ 523 DRADCTMP "Drive recorder(ADU) temporary malfunction notification";
CM_ BO_ 841 "Reserve";
CM_ SG_ 841 ETHWU_12 "Eth continuous reques to CDC from ADC";
CM_ BO_ 448 "Reserve";
CM_ SG_ 448 APPMD2 "APP Control Status No.2";
CM_ BO_ 526 "Reserve";
CM_ SG_ 526 DIS_ALR2 "Driver Monitor Alert";
CM_ SG_ 526 DISSUIEX "DMC alert timing";
CM_ SG_ 526 DISSUIST "DMC alert timing Display State";
CM_ SG_ 526 SW_ALRT2 "Driver Monitor Alert Display State";
CM_ SG_ 526 PLANTREQ "HMI_req_plantmode";
CM_ SG_ 526 ADOFFM1 "ADAS OFF integrate message1";
CM_ SG_ 526 ADOFFM2 "ADAS OFF integrate message2";
CM_ SG_ 526 ADOFFMET "ADAS other system off message";
CM_ SG_ 526 SCBOICN "SCB OFF message icon";
CM_ SG_ 526 RCDOICN "RCD OFF message icon";
CM_ SG_ 526 RCTAOICN "RCTA OFF message icon";
CM_ SG_ 526 SEAOICN "SEA OFF message icon";
CM_ SG_ 526 FCTAOICN "FCTA OFF message icon";
CM_ SG_ 526 SASOICN "SAS OFF message icon";
CM_ SG_ 526 EDSSOICN "EDSS OFF message icon";
CM_ SG_ 526 RSL_PLRQ "RSR_L_PlantMode";
CM_ SG_ 526 RSR_PLRQ "RSR_R_PlantMode";
CM_ SG_ 526 FSL_PLRQ "FSR_L_PlantMode";
CM_ SG_ 526 FSR_PLRQ "FSR_R_PlantMode";
CM_ SG_ 526 FRD_PLRQ "FRD_PlantMode";
CM_ SG_ 526 ADISTATE "Status for ADAS representative indicator";
CM_ SG_ 526 SEAADIM "SEA message for ADAS representative indicator";
CM_ SG_ 526 PMARADIM "PMAR message for ADAS representative indicator";
CM_ SG_ 526 RCTAADIM "RCTA message for ADAS representative indicator";
CM_ SG_ 526 BSMADIM "BSM message for ADAS representative indicator";
CM_ SG_ 526 ADIEXIST "Existence signal for ADAS representative indicator";
CM_ SG_ 526 FSR_BZ_C "FSR_RH_DealerOnlineAdjustmentCompleteBuzzer";
CM_ SG_ 526 FSR_BZ_E "FSR_RH_DealerOnlineAdjustmentErrorBuzzer";
CM_ SG_ 526 FSL_BZ_C "FSR_LH_DealerOnlineAdjustmentCompleteBuzzer";
CM_ SG_ 526 FSL_BZ_E "FSR_LH_DealerOnlineAdjustmentErrorBuzzer";
CM_ SG_ 526 RSR_BZ_C "RSR_RH_DealerOnlineAdjustmentCompleteBuzzer";
CM_ SG_ 526 RSR_BZ_E "RSR_RH_DealerOnlineAdjustmentErrorBuzzer";
CM_ SG_ 526 RSL_BZ_C "RSR_LH_DealerOnlineAdjustmentCompleteBuzzer";
CM_ SG_ 526 RSL_BZ_E "RSR_LH_DealerOnlineAdjustmentErrorBuzzer";
CM_ SG_ 526 DMCINDI "Driver monitor system state";
CM_ SG_ 526 DMCDISP "Driver monitor MID Request";
CM_ SG_ 526 DMCBZRQ "Driver monitor BZR Request";
CM_ SG_ 526 ACCAVTYR "Adjacent vehicle type Right";
CM_ SG_ 526 ACCAVDTR "Adjacent vehicle distance Right";
CM_ SG_ 526 ACCAVS1R "Adjacent vehicle state1 Right";
CM_ SG_ 526 ACCAVS2R "Adjacent vehicle state2 (blinking) Right";
CM_ SG_ 526 ACCAVLPR "Adjacent vehicle lateral position Right";
CM_ SG_ 526 ACCAVTYL "Adjacent vehicle type Left";
CM_ SG_ 526 ACCAVS2L "Adjacent vehicle state2 (blinking) Left";
CM_ SG_ 526 ACCAVS1L "Adjacent vehicle state1 (color) Left";
CM_ SG_ 526 ACCAVDTL "Adjacent vehicle distance Left";
CM_ SG_ 526 ACCAVLPL "Adjacent vehicle lateral position Left";
CM_ SG_ 526 ACCPPVEX "Pre-Preceding vehicle existence";
CM_ SG_ 526 ACCPPVDT "Pre-Preceding vehicle distance";
CM_ SG_ 526 ACCPPVS1 "Pre-Preceding vehicle state1 (color)";
CM_ SG_ 526 ACCPVTY "Preceding vehicle type";
CM_ SG_ 526 ACCPVDST "Preceeding vehicle distance";
CM_ SG_ 526 ACCPVST1 "Preceding vehicle state 1(color)";
CM_ SG_ 526 ACCPVST2 "Preceding vehicle state 2(blinking )";
CM_ SG_ 526 ACCPVST3 "Preceding vehicle state 3(departure)";
CM_ SG_ 526 CACCFR1 "C-ACC display request (control)";
CM_ SG_ 526 ERMPLRST "Eco Run Mode recommendation status";
CM_ SG_ 526 AH_SRI_C "AHS Surrounding Info Flag for remote monitoring";
CM_ SG_ 526 AH_IND_C "AHS Shading Indicator for remote monitoring";
CM_ SG_ 526 AH_WTR_C "AHS Bad Weather status for remote monitoring";
CM_ SG_ 526 BSMOICN "BSM OFF message icon";
CM_ BO_ 477 "Reserve";
CM_ SG_ 477 ARS_METD "Demand signal to Meter";
CM_ SG_ 477 ARSEXT "DRS exist flag";
CM_ BO_ 900 "Reserve";
CM_ SG_ 900 RDC "Road Class";
CM_ SG_ 900 CONFID01 "Confidence ID 01";
CM_ SG_ 900 CONF "Confidence";
CM_ SG_ 900 LYT "Link type";
CM_ SG_ 900 TNL_5H_S "500 Meter Short of Tunnel";
CM_ SG_ 900 TNL_1T_S "1000 Meter Short of Tunnel";
CM_ SG_ 900 DRVW "Drive Way";
CM_ SG_ 900 MWMP "Motor Way Map";
CM_ SG_ 900 GRAD "Gradient change";
CM_ SG_ 900 TNL_5T_S "5000 Meter Short of Tunnel";
CM_ SG_ 900 BRANCH "Branch";
CM_ SG_ 900 TOLLGATE "TOLLGATE";
CM_ SG_ 900 TUNL "Tunnel";
CM_ SG_ 900 LEAVEOUT "Leaveout Lane";
CM_ SG_ 900 MRGLANE "Merge Lane";
CM_ SG_ 900 LVLANE "Leaveout lane without lane change";
CM_ BO_ 910 "Reserve";
CM_ SG_ 910 R_AC_DSP "A/C Display function request";
CM_ SG_ 910 AVN04VLD "AVN1S04 valid information";
CM_ SG_ 910 S_ACECO "A/C ECO SW Status";
CM_ SG_ 910 S_BLW_F "Blower Custom SW Status";
CM_ SG_ 910 S_RA_AUT "RearA/C AIRPURIFIER AUTO switch state";
CM_ SG_ 910 S_RA_OFF "RearA/C AIRPURIFIER switch state";
CM_ SG_ 910 S_RA_MNL "RearA/C AIRPURIFIER MANUAL switch state";
CM_ SG_ 910 R_PN_TYP "Panel design information";
CM_ SG_ 910 R_CONCIE "Climate concierge select information";
CM_ SG_ 910 S_CONCIE "Climate concierge switch state";
CM_ SG_ 910 R_S_FLOW "S-Flow select information";
CM_ SG_ 910 R_RFAT "Gas auto LED select information";
CM_ SG_ 910 S_AUTO_D "Dr AUTO switch state";
CM_ SG_ 910 S_AUTO_P "Pa AUTO switch state";
CM_ SG_ 910 S_DEF "DEF switch state";
CM_ SG_ 910 S_RRDEF "RrDEF switch state";
CM_ SG_ 910 S_INL "INLET switch state";
CM_ SG_ 910 S_OFF_F "FrontOFF switch state";
CM_ SG_ 910 S_SAFS "SAFS switch state";
CM_ SG_ 910 S_AC "A/C switch state";
CM_ SG_ 910 S_MHTR "Mirror heater switch state";
CM_ SG_ 910 S_WIPD "DEICER switch state";
CM_ SG_ 910 S_DUSY "DUAL/SYNC switch state";
CM_ SG_ 910 S_SWNG "Swing switch state";
CM_ SG_ 910 S_MODE_D "Dr MODE switch state";
CM_ SG_ 910 S_MODE_P "Pa MODE switch state";
CM_ SG_ 910 S_BUP_F "Blower FRONT UP switch state";
CM_ SG_ 910 S_BDN_F "Blower FRONT DOWN switch state";
CM_ SG_ 910 S_NANOE "Nano-E switch state";
CM_ SG_ 910 S_OLET_D "Dr OLET switch state";
CM_ SG_ 910 S_DSPR "Dr seat priority SW Status";
CM_ SG_ 910 S_OLET_P "Pa OLET switch state";
CM_ SG_ 910 S_TUP_D "Dr temperature UP switch state";
CM_ SG_ 910 S_TDN_D "Dr temperature Down switch state";
CM_ SG_ 910 S_TUP_P "Pa temperature UP switch state";
CM_ SG_ 910 S_TDN_P "Pa temperature Down switch state";
CM_ SG_ 910 S_PLSM "PLASMA CLUSTER switch state";
CM_ SG_ 910 S_KAFUN "POLLEN REMOVE switch state";
CM_ SG_ 910 S_AIRPR "AIRPURIFIER switch state";
CM_ SG_ 910 S_O2 "OXYGEN RICH switch state";
CM_ SG_ 910 S_FRS "INLET FRS switch state";
CM_ SG_ 910 S_REC "INLET REC switch state";
CM_ SG_ 910 S_HUM "Humidification switch state";
CM_ SG_ 910 S_CONCEN "Switch state that shows concentration on one seat";
CM_ SG_ 910 S_IN_RTN "GAS RECEPTION setting screen";
CM_ SG_ 910 S_INLVL "GAS RECEPTION setting SW state";
CM_ SG_ 910 S_BLW7_F "Blower FRONT Level7 switch state";
CM_ SG_ 910 S_BLW6_F "Blower FRONT Level6 switch state";
CM_ SG_ 910 S_BLW5_F "Blower FRONT Level5 switch state";
CM_ SG_ 910 S_BLW4_F "Blower FRONT Level4 switch state";
CM_ SG_ 910 S_BLW3_F "Blower FRONT Level3 switch state";
CM_ SG_ 910 S_BLW2_F "Blower FRONT Level2 switch state";
CM_ SG_ 910 S_BLW1_F "Blower FRONT Level1 switch";
CM_ SG_ 910 ST_NAVAC "A/C-Navi cooperation state";
CM_ BO_ 903 "Reserve";
CM_ SG_ 903 S_AUT_RR "RearR AUTO switch state";
CM_ SG_ 903 S_AUT_RL "RearL AUTO switch state";
CM_ SG_ 903 S_BUP_R "Blower Rear UP switch state";
CM_ SG_ 903 S_BDN_R "Blower Rear Down switch state";
CM_ SG_ 903 S_TUP_RR "RearR temperature UP switch state";
CM_ SG_ 903 S_TDN_RR "RearR temperature DOWN switch state";
CM_ SG_ 903 S_TUP_RL "RearL temperature UP switch state";
CM_ SG_ 903 S_TDN_RL "RearL temperature DOWN switch state";
CM_ SG_ 903 ST_FRDSP "Fr_Rr display state";
CM_ SG_ 903 S_OLT_RR "RearR OLET switch state";
CM_ SG_ 903 S_OLT_RL "RearL OLET switch state";
CM_ SG_ 903 S_MOD_RR "RearR MODE switch state";
CM_ SG_ 903 S_MOD_RL "RearL MODE switch state";
CM_ SG_ 903 S_OFF_R "Rear OFF switch state";
CM_ SG_ 903 S_CNT_IH "Rear Control Inhibit switch state";
CM_ SG_ 903 S_RRSEAT "Rear SEAT HEATER switch state";
CM_ SG_ 903 S_REONOF "Rear ON OFF switch state";
CM_ SG_ 903 S_SYNC "SYNC Control Request";
CM_ SG_ 903 S_RAUTO "Rear AUTO switch state";
CM_ SG_ 903 S_BLW7_R "Blower Rear Level7 switch state";
CM_ SG_ 903 S_BLW6_R "Blower Rear Level6 switch state";
CM_ SG_ 903 S_BLW5_R "Blower Rear Level5 switch state";
CM_ SG_ 903 S_BLW4_R "Blower Rear Level4 switch state";
CM_ SG_ 903 S_BLW3_R "Blower Rear Level3 switch state";
CM_ SG_ 903 S_BLW2_R "Blower Rear Level2 switch state";
CM_ SG_ 903 S_BLW1_R "Blower Rear Lelel1 switch state";
CM_ SG_ 903 S_TPMDRR "RrR SEAT speach recognition operation mode information";
CM_ SG_ 903 S_ICDLRR "RrR SEAT speach recognition data addition subtraction information";
CM_ SG_ 903 S_TPCDRR "RrR SEAT speach recognition temperature directions data";
CM_ SG_ 903 S_TPMDRL "RrL SEAT speach recognition operation mode information";
CM_ SG_ 903 S_ICDLRL "RrL SEAT speach recognition data addition subtraction information";
CM_ SG_ 903 S_TPCDRL "RrL SEAT speach recognition temperature directions data";
CM_ SG_ 903 S_TPMD_D "Dr SEAT speach recognition operation mode information";
CM_ SG_ 903 S_ICDL_D "Dr SEAT speach recognition data addition subtraction information";
CM_ SG_ 903 S_TPCD_D "Dr SEAT speach recognition temperature directions data";
CM_ SG_ 903 S_TPMD_P "Pa SEAT speach recognition operation mode information";
CM_ SG_ 903 S_ICDL_P "Pa SEAT speach recognition data addition subtraction information";
CM_ SG_ 903 S_TPCD_P "Pa SEAT speach recognition temperature directions data";
CM_ BO_ 904 "Reserve";
CM_ SG_ 904 S_DF_SH "Dr Seat Heater Operation SW information";
CM_ SG_ 904 S_PF_SH "Pa Seat Heater Operation SW information";
CM_ SG_ 904 S_RR_SH "RrR Seat Heater Operation SW information";
CM_ SG_ 904 S_RL_SH "RrL Seat Heater Operation SW information";
CM_ SG_ 904 S_DF_SB "Dr Seat Blast Operation SW information";
CM_ SG_ 904 S_PF_SB "Pa Seat Blast Operation SW information";
CM_ SG_ 904 S_RR_SB "RrR Seat Blast Operation SW information";
CM_ SG_ 904 S_RL_SB "RrL Seat Blast Operation SW information";
CM_ SG_ 904 S_DF_SA "Dr Seat AUTO Operation SW information";
CM_ SG_ 904 S_PF_SA "Pa Seat AUTO Operation SW information";
CM_ SG_ 904 S_RR_SA "RrR Seat AUTO Operation SW information";
CM_ SG_ 904 S_RL_SA "RrL Seat AUTO Operation SW information";
CM_ SG_ 904 S_NUP_D "Dr Neck Heater Up Operation SW information";
CM_ SG_ 904 S_NDN_D "Dr Neck Heater Down Operation SW information";
CM_ SG_ 904 S_NUP_P "Pa Neck Heater Up Operation SW information";
CM_ SG_ 904 S_NDN_P "Pa Neck Heater Down Operation SW information";
CM_ SG_ 904 S_STH "Steering Heater Operation SW Information";
CM_ SG_ 904 S_STHAUT "Steering Heater AUTO Operation SW Information";
CM_ SG_ 904 S_STH_UP "Steering Heater Temperature Up Operation SW Information";
CM_ SG_ 904 S_STH_DN "Steering Heater Temperature Down Operation SW Information";
CM_ SG_ 904 S_DF_NA "Dr Neck Heater AUTO Operation SW information";
CM_ SG_ 904 S_PF_NA "Pa Neck Heater AUTO Operation SW information";
CM_ SG_ 904 S_NECK_D "Dr Neck Heater Operation SW information";
CM_ SG_ 904 S_NECK_P "P Neck Heater Operation SW information";
CM_ SG_ 904 S_HUP_D "Dr Seat Heater Operation Up SW information";
CM_ SG_ 904 S_HUP_P "Pa Seat Heater Operation Up SW information";
CM_ SG_ 904 S_HUP_RR "RrR Seat Heater Operation Up SW information";
CM_ SG_ 904 S_HUP_RL "RrL Seat Heater Operation Up SW information";
CM_ SG_ 904 S_HDN_D "Dr Seat Heater Operation Down SW information";
CM_ SG_ 904 S_HDN_P "Pa Seat Heater Operation Down SW information";
CM_ SG_ 904 S_HDN_RR "RrR Seat Heater Operation Down SW information";
CM_ SG_ 904 S_HDN_RL "RrL Seat Heater Operation Down SW information";
CM_ SG_ 904 S_BUP_D "Dr Seat Blower Operation Up SW information";
CM_ SG_ 904 S_BUP_P "Pa Seat Blower Operation Up SW information";
CM_ SG_ 904 S_BUP_RR "RrR Seat Blower Operation Up SW information";
CM_ SG_ 904 S_BUP_RL "RrL Seat Blower Operation Up SW information";
CM_ SG_ 904 S_BDN_D "Dr Seat Blower Operation Down SW information";
CM_ SG_ 904 S_BDN_P "Pa Seat Blower Operation Down SW information";
CM_ SG_ 904 S_BDN_RR "RrR Seat Blower Operation Down SW information";
CM_ SG_ 904 S_BDN_RL "RrL Seat Blower Operation Down SW information";
CM_ BO_ 911 "Reserve";
CM_ SG_ 911 SOLRST "Request for reset solar daily information";
CM_ SG_ 911 SL_CSTM "Customize function Select information";
CM_ SG_ 911 SL_RMDG "Remote Diagnosis function Select information";
CM_ SG_ 911 ST_RTCOM "Remote tool communication status";
CM_ SG_ 911 AVN07VLD "AVN1S07 valid information";
CM_ SG_ 911 RESDSPID "Displaying RS Screen ID";
CM_ SG_ 911 SNCCNTRE "Synchronous Counter(response)";
CM_ SG_ 911 DIAGMODE "Diagnosis Mode";
CM_ BO_ 998 "Reserve";
CM_ SG_ 998 SENSPFM "Sensor Performance";
CM_ SG_ 998 SENSFAIL "Sensor Fail";
CM_ SG_ 998 CONFID11 "Confidence ID 11";
CM_ SG_ 998 CONFMMC "Confidence MMC";
CM_ SG_ 998 DISTERR "Distance err";
CM_ SG_ 998 CONFLANE "Confidence Lane";
CM_ SG_ 998 CONFDIR "Confidence Direction";
CM_ BO_ 1076 "Reserve";
CM_ SG_ 1076 A_LNG_ST "Language Status";
CM_ SG_ 1076 A_LANG "Language Setting";
CM_ SG_ 1076 A_LNGDB1 "Language Database 1";
CM_ SG_ 1076 A_LNGDB2 "Language Database 2";
CM_ SG_ 1076 A_LNGDB3 "Language Database 3";
CM_ SG_ 1076 A_LNGDB4 "Language Database 4";
CM_ SG_ 1076 A_LNGDB5 "Language Database 5";
CM_ SG_ 1076 A_LNGDB6 "Language Database 6";
CM_ SG_ 1076 A_LNGDB7 "Language Database 7";
CM_ SG_ 1076 A_LNGCHG "Language Setting Chane Flag";
CM_ BO_ 1077 "Reserve";
CM_ SG_ 1077 A_OPEN_S "Opening/Ending coordination on-off";
CM_ SG_ 1077 OPENCHG "Opening coordination status";
CM_ SG_ 1077 CAPSW_S "CAP SW Setting";
CM_ SG_ 1077 A_CLR_S "Display Mode Setting";
CM_ SG_ 1077 DISP_BRT "Screen Brightness";
CM_ SG_ 1077 DISP_CNT "Display Contrast";
CM_ SG_ 1077 A_COP_S "Coordination Opening State(AVN)";
CM_ SG_ 1077 A_OP_SUP "Coordination Opening Support(AVN)";
CM_ SG_ 1077 DM_PGSW "EDSS passenger switch information";
CM_ SG_ 1077 FAVSET_R "Favorite SW switching status update (Right side)";
CM_ SG_ 1077 FAVSET_L "Favorite SW switching status update (Left side)";
CM_ SG_ 1077 A_UNTTMP "Temperature Unit Setting";
CM_ SG_ 1077 A_UNTSP "Speed Unit Setting";
CM_ SG_ 1077 A_UNTDST "Distance Unit Setting";
CM_ SG_ 1077 A_TMPCHG "Temperature Unit Setting change flag";
CM_ SG_ 1077 A_SPCHG "Speed Unit Setting change flag";
CM_ SG_ 1077 A_DSTCHG "Distance Unit Setting change flag";
CM_ SG_ 1077 A_SPLM "Speed Limit ";
CM_ SG_ 1077 A_UTSPLM "Speed Limit Unit Setting";
CM_ BO_ 1078 "Reserve";
CM_ SG_ 1078 R1_SWOP "RRC1 SW operation";
CM_ BO_ 1079 "Reserve";
CM_ SG_ 1079 R2_SWOP "RRC2 SW operation";
CM_ BO_ 794 "Reserve";
CM_ SG_ 794 CLK_YEAR "MM clock Year";
CM_ SG_ 794 CLK_MONT "MM clock month";
CM_ SG_ 794 CLK_DAY "MM clock Day";
CM_ SG_ 794 CLK_HOUR "MM clock hour";
CM_ SG_ 794 GPS_ST "GPS Time Status";
CM_ SG_ 794 GPS_CRCT "GPS correct ON/OFF";
CM_ SG_ 794 CLK_MIN "MM clock minute";
CM_ SG_ 794 CLK_SEC "MM clock second";
CM_ SG_ 794 DST_S30 "DaylightSavingTime";
CM_ SG_ 794 TZ "TimeZone";
CM_ SG_ 794 TZ_SIGN "TimeZone Sign";
CM_ BO_ 289 "Reserve";
CM_ SG_ 289 ROAD_CLS "Road Classification Information";
CM_ SG_ 289 MEDIAN "Presence or Absence of Median";
CM_ SG_ 289 OVR_CROS "Presence or Absence of Over Cross";
CM_ SG_ 289 ITR_NO "Intersection Number";
CM_ SG_ 289 ITR_SG "Presence or Absence of Intersection Signal";
CM_ SG_ 289 ITR_LAT "Intersection Latitude";
CM_ SG_ 289 ITR_LNG "Intersection Longitude";
CM_ BO_ 1418 "Reserve";
CM_ SG_ 1418 P_DCS "Switch State of Power Train";
CM_ SG_ 1418 C_DCS "Switch State of Chassis";
CM_ SG_ 1418 AC_DCS "Switch State of A/C";
CM_ SG_ 1418 AVN39VLD "AVN1S39 valid information";
CM_ SG_ 1418 C_ST_DCS "Switch State of Steering";
CM_ SG_ 1418 C_SU_DCS "Switch State of Suspension";
CM_ SG_ 1418 C_BR_DCS "Switch State of Brake";
CM_ SG_ 1418 DM_AVN_D "Status of Drive Mode selection display";
CM_ SG_ 1418 BDR_S_SW "Brake Refresh Control Software SW Operation Signal";
CM_ SG_ 1418 CRLMD_SW "CRAWL MODE SW operation signal";
CM_ SG_ 1418 CRAWL_M "CRAWL Mode minus operation for CRAWL switch(-/SET)";
CM_ SG_ 1418 CRAWL_P "CRAWL Mode plus operation for CRAWL switch(+)";
CM_ SG_ 1418 BH_SW "Brake Hold Standby Soft Switch Operation Signal";
CM_ SG_ 1418 TRCOFFSW "TRC OFF Soft Switch Operation Signal";
CM_ SG_ 1418 VSCOFFSW "VSC OFF Soft Switch Operation Signal";
CM_ SG_ 1418 EVMD_SW "Switch State of EV Mode";
CM_ SG_ 1418 NMRBR_SW "Nameraka Brake Switch Operation Signal";
CM_ SG_ 1418 DAC_S_SW "DAC Soft Switch Operation Signal";
CM_ SG_ 1418 MMFZ_CNT "Rolling counter";
CM_ SG_ 1418 MN_MD_SW "NORMAL MODE SW for MTS operation signal";
CM_ SG_ 1418 MS_MD_SW "Mud and Sand MODE SW operation signal";
CM_ SG_ 1418 RD_MD_SW "Rock and Dirt MODE SW operation signal";
CM_ SG_ 1418 TR_MD_SW "TRAIL MODE SW operation signal";
CM_ BO_ 1309 "Reserve";
CM_ SG_ 1309 ID6F900 "AVN1S44 SubID";
CM_ SG_ 1309 IF6F900 "AVN1S44 INFO";
CM_ SG_ 1309 REQ_ECU "Change Requestor";
CM_ SG_ 1309 BTN_FLG "Flag of Pushing Button";
CM_ SG_ 1309 CUST_ID "Customization ID";
CM_ SG_ 1309 CUST_VAL "Customization Configuration Request Value";
CM_ BO_ 445 "Reserve";
CM_ SG_ 445 DSP_SW "D seat position SW";
CM_ SG_ 445 DSC_SW "D seat control SW";
CM_ SG_ 445 DAL_SW "D seat auto adjustment level SW";
CM_ SG_ 445 OSC_SW "Other seat control SW";
CM_ SG_ 445 DRM_SW "D seat refresh mode SW";
CM_ SG_ 445 DRA_SW "D seat refresh adjustment SW";
CM_ SG_ 445 PSP_SW "P seat position SW";
CM_ SG_ 445 PSC_SW "P seat control SW";
CM_ SG_ 445 PAL_SW "P seat auto adjustment level SW";
CM_ SG_ 445 PRM_SW "P seat refresh mode SW";
CM_ SG_ 445 PRA_SW "P seat refresh adjustment SW";
CM_ SG_ 445 DRSF_SW "D seat refresh ON/OFF SW";
CM_ SG_ 445 D_ES_SW "D seat emergency stop SW";
CM_ SG_ 445 PMO_SW "P seat mode SW";
CM_ SG_ 445 PRSF_SW "P seat refresh ON/OFF SW";
CM_ SG_ 445 P_ES_SW "P seat emergency stop SW";
CM_ SG_ 445 R_ES_SW "Rr seat emergency stop SW";
CM_ SG_ 445 SSEL_SW "Seat select SW";
CM_ SG_ 445 FO_RE_SW "Seat fold&return SW";
CM_ SG_ 445 WI_RE_SW "Seat walk-in&return SW";
CM_ SG_ 445 AR_ES_SW "Seat allange emergency stop SW";
CM_ SG_ 445 AFR_SW "ALL seat fold&return SW";
CM_ BO_ 859 "Reserve";
CM_ SG_ 859 CLE_HUM "Humidity for Cloud Eco";
CM_ SG_ 859 CLE_TAM "Air temperature for Cloud Eco";
CM_ SG_ 859 CLE_OK "Cloud Eco of moisture carry-on judgment flag";
CM_ SG_ 859 CLE_COF "Cloud Eco of compressor off enable flag";
CM_ BO_ 969 "Reserve";
CM_ SG_ 969 MMC1 "Map Matching cordinates 1";
CM_ SG_ 969 MMC2 "Map Matching cordinates 2";
CM_ BO_ 1168 "Reserve";
CM_ SG_ 1168 ID6CF00 "AVN1S64 SubID";
CM_ SG_ 1168 IF6CF00 "AVN1S64 INFO";
CM_ SG_ 1168 DLID "Differrence Link ID";
CM_ SG_ 1168 LID "Link ID";
CM_ BO_ 1311 "Reserve";
CM_ SG_ 1311 ID6FE00 "AVN1S65 SubID";
CM_ SG_ 1311 IF6FE00 "AVN1S65 INFO";
CM_ SG_ 1311 MMCONF "Map Matching Confidence";
CM_ SG_ 1311 DLINKP "Distance From Link Entry Point";
CM_ SG_ 1311 RCODE "Region Code";
CM_ BO_ 1322 "Reserve";
CM_ SG_ 1322 ID6FF00 "AVN1S66 SubID";
CM_ SG_ 1322 IF6FF00 "AVN1S66 INFO";
CM_ SG_ 1322 HUCMP "Head Unit Composition";
CM_ SG_ 1322 DCUNO "DCU Application Management No.";
CM_ SG_ 1322 MEUNO "MEU Application Management No.";
CM_ SG_ 1322 MBV "Map Base Version";
CM_ SG_ 1322 ETC_SW "ETC button operation signal";
CM_ BO_ 782 "Reserve";
CM_ SG_ 782 B1_FUNID "BDB1_FunctionID";
CM_ SG_ 782 B1_INST1 "BDB1_OpeInstruction1";
CM_ SG_ 782 B1_INST2 "BDB1_OpeInstruction2";
CM_ SG_ 782 B1_INST3 "BDB1_OpeInstruction3";
CM_ SG_ 782 B1_INST4 "BDB1_OpeInstruction4";
CM_ SG_ 782 B1_INST5 "BDB1_OpeInstruction5";
CM_ SG_ 782 B1_INST6 "BDB1_OpeInstruction6";
CM_ SG_ 782 B1_INST7 "BDB1_OpeInstruction7";
CM_ BO_ 1313 "Reserve";
CM_ SG_ 1313 ID6CE00 "AVN1S69 SubID";
CM_ SG_ 1313 IF6CE00 "AVN1S69 INFO";
CM_ SG_ 1313 HOME_SET "Home settings";
CM_ SG_ 1313 HOME_DIS "Distance to the home";
CM_ SG_ 1313 COMPASS "Compass";
CM_ SG_ 1313 NAVSTAT "Non-native navi guidance state";
CM_ SG_ 1313 SSDVOL_O "SSD volume setting operation";
CM_ SG_ 1313 DSCNUM "Present sector";
CM_ SG_ 1313 DGPSRL "GPS reliability information";
CM_ SG_ 1313 DSCENE "Quantity of biggest boost";
CM_ SG_ 1313 DUSMND "Circuit run intention confirmation flag";
CM_ SG_ 1313 DBSTRT "Boost rate";
CM_ SG_ 1313 DSOCTG "Start SOC most suitable for every circuit";
CM_ BO_ 332 "Reserve";
CM_ SG_ 332 SMPACT "Remote application status";
CM_ SG_ 332 SMPX "touch point x-coordinate";
CM_ SG_ 332 SMPBTN "Button operation";
CM_ SG_ 332 SMPY "touch point y-coordinate";
CM_ SG_ 332 SMPDSPID "Smartphone display ID";
CM_ SG_ 332 SMPSELMD "Driver selected parking mode";
CM_ SG_ 332 SMPCNT "Smartphone counter";
CM_ SG_ 332 SMPSUM "Smartphone error detection code";
CM_ BO_ 682 "Reserve";
CM_ SG_ 682 AVN_ON "AVN Communication Flag";
CM_ SG_ 682 CC_MODE "Center display camera mode state";
CM_ SG_ 682 IRQ_MM "Interrupt Request from MM";
CM_ SG_ 682 CMD_MODE "Camera Diag Mode State Signal";
CM_ SG_ 682 DI_MODE "Camera Diag Transition Request";
CM_ SG_ 682 MM_RESET "MM Reset Request";
CM_ SG_ 682 X_COORD "X Coordinates";
CM_ SG_ 682 DN_DISP "Day or Night display State Signal";
CM_ SG_ 682 MMD_MODE "MM Diagnosis Mode";
CM_ SG_ 682 SW_PVM "Camera Soft SW";
CM_ SG_ 682 CUST_TRA "TRA Customize Display Request";
CM_ SG_ 682 CUST_APP "APP Customize Display Request";
CM_ SG_ 682 CUST_PVM "PVM Customize Display Request";
CM_ SG_ 682 Y_COORD "Y Coordinates";
CM_ SG_ 682 VR_STATE "Voice Recognition Status";
CM_ SG_ 682 MIC_POS "Active Microphone Position";
CM_ SG_ 682 X2_COORD "X2 Coordinates";
CM_ SG_ 682 CD_SIZE "Center display size information";
CM_ SG_ 682 Y2_COORD "Y2 Coordinates";
CM_ BO_ 837 "Reserve";
CM_ SG_ 837 ACCSW "ACC customize button signal";
CM_ SG_ 837 ACC_FLG "Compatibility flag for ACC customize";
CM_ SG_ 837 AVN_FUNC "AVN function availability";
CM_ SG_ 837 WUP_STAT "Wake up status";
CM_ BO_ 838 "Reserve";
CM_ SG_ 838 OTA2RSLT "OTA display result(ADS)";
CM_ SG_ 838 OTA3RSLT "OTA display result(FCM)";
CM_ SG_ 838 OTADRSLT "OTA display result(DCM)";
CM_ SG_ 838 SRVC_STT "Location information data upload consent state";
CM_ SG_ 838 OTA2CNCL "OTA Reprogram Cancel(ADS)";
CM_ SG_ 838 OTA3CNCL "OTA Reprogram Cancel(FCM)";
CM_ SG_ 838 OTADCNCL "OTA Reprogram Cancel(DCM)";
CM_ SG_ 838 CUR_DRV "Driver identified by user recognition function";
CM_ SG_ 838 SRVC_PC "Picture data sharing status";
CM_ SG_ 838 SRVC_VC "Voice data sharing status";
CM_ SG_ 838 SRVC_AC "All data sharing status";
CM_ SG_ 838 OTAPPCTL "Vehicle power controll state during parking OTA.";
CM_ SG_ 838 CW_MD_SW "Car Wash Mode";
CM_ SG_ 838 VNHLDRQ "N hold request";
CM_ SG_ 838 TRNCASW "ADAS Training Mode Cancel SW press signal";
CM_ SG_ 838 TRNSD "ADAS Training Mode Selection Data";
CM_ SG_ 838 TRNFBPD "ADAS Training Mode Finish Button Push Data";
CM_ SG_ 838 OTACDRLT "Notification of countdown result";
CM_ SG_ 838 OTACHGEX "Notification of the necessity of exclusive control with charging";
CM_ SG_ 838 OTAACTTP "Activation method notification";
CM_ SG_ 838 OTAACTPH "Activation sector notification";
CM_ SG_ 838 OTASWACT "Notification of software switching section";
CM_ SG_ 838 OTASTAT "Notification of OTA software update state";
CM_ BO_ 985 "Reserve";
CM_ SG_ 985 S_FRONOF "Fragrance switch state";
CM_ SG_ 985 S_WFRCR "Fragrance Select switch state(Welcome)";
CM_ SG_ 985 S_RFRCR "Fragrance Select switch state(Refresh)";
CM_ SG_ 985 S_WFRSTR "Strength of Fragrance switch state(Welcome)";
CM_ SG_ 985 S_RFRSTR "Strength of Fragrance switch state(Refresh)";
CM_ SG_ 985 S_PMREMO "PM2.5 remove swithch state";
CM_ SG_ 985 S_BLWCL "Blower Custom List SW Status";
CM_ SG_ 985 S_HBCD_D "Dr SEAT voice control seat heater ventilator level set data";
CM_ SG_ 985 S_HBMD_D "Dr SEAT voice control seat heater ventilator mode infromation";
CM_ SG_ 985 S_HBCD_P "Pa SEAT voice control seat heater ventilator level set data";
CM_ SG_ 985 S_HBMD_P "Pa SEAT voice control seat heater ventilator mode infromation";
CM_ SG_ 985 S_HBCDRR "RR SEAT voice control seat heater ventilator level set data";
CM_ SG_ 985 S_HBMDRR "RR SEAT voice control seat heater ventilator mode infromation";
CM_ SG_ 985 S_HBCDRL "RL SEAT voice control seat heater ventilator level set data";
CM_ SG_ 985 S_HBMDRL "RL SEAT voice control seat heater ventilator mode infromation";
CM_ SG_ 985 S_STHCD "Voice control steering heater level set data";
CM_ SG_ 985 V_FG_CH "Frangrance type selection VR request";
CM_ SG_ 985 V_FG_LVL "Frangrance potency selection VR request";
CM_ SG_ 985 V_FG_PWR "Frangrance ON/OFF VR request";
CM_ SG_ 985 S_FG_CH "Frangrance type selection switch request";
CM_ SG_ 985 S_FG_LVL "Frangrance potency selection switch request";
CM_ SG_ 985 S_TMODE "takankaku_mode";
CM_ BO_ 996 "Reserve";
CM_ SG_ 996 DEL_UN "ScreenResponse_DeleteDriverUserNo";
CM_ SG_ 996 MSR_DRV "ScreenResponse_Driver";
CM_ SG_ 996 PRMPIEXE "Parameter of execution of personal identification device registration";
CM_ SG_ 996 SPHN_UID "User Identification No by SmartPhone";
CM_ SG_ 996 OPTPIEXE "execution option of personal identification device registration";
CM_ SG_ 996 MREQ_FPT "Request of Fingerprint Authentication";
CM_ SG_ 996 MREG_EXE "Request of Fingerprint Authentication";
CM_ SG_ 996 MPOS_FPT "Position of Fingerprint Number";
CM_ SG_ 996 DIDPIEXE "Devce id of execution of personal identification device registration";
CM_ SG_ 996 F_GST_MD "Force Guest Mode Request Signal";
CM_ SG_ 996 MREQ_DPM "ScreenResponse_DrivingPositionRecallRequest";
CM_ SG_ 996 REQPIEXE "Request of execution of personal identification device registration";
CM_ SG_ 996 UI_DEPLY "MM user identification function deploy";
CM_ SG_ 996 DK_ALDRQ "Digital all key deletion request";
CM_ SG_ 996 DK_DLCRQ "Digital key deletion confirmation request";
CM_ BO_ 960 "Reserve";
CM_ SG_ 960 A_CURHRQ "Charging current home only request";
CM_ SG_ 960 A_CURREQ "Charging current setting change request";
CM_ SG_ 960 A_CLCREQ "Connector lock setting change request";
CM_ SG_ 960 A_LMTHRQ "Charging limit home only request";
CM_ SG_ 960 A_SLMREQ "Electric Supply Limit setting change request";
CM_ SG_ 960 A_LMTREQ "Charging limit setting change request";
CM_ SG_ 960 A_SPLMOD "Supply mode choice result";
CM_ SG_ 960 A_TMRHRQ "Request of home only timer charging";
CM_ SG_ 960 A_LMTSRQ "Solar charge priority request";
CM_ SG_ 960 A_SLMDRQ "Request to Hybrid electric supply long mode ON/OFF operation";
CM_ SG_ 960 A_DPWREQ "DC Charging power setting change request";
CM_ SG_ 960 A_PNCREQ "Plug and Charge request";
CM_ SG_ 960 A_CEIBPH "Certificate update button judge";
CM_ SG_ 960 A_DVOREQ "DC Charging voltage setting change request";
CM_ SG_ 960 A_CHGCRQ "Bi-directional Charging operation request";
CM_ SG_ 960 OUTCS "Output of charging station";
CM_ SG_ 960 JDTCS "Judgment of type of charging station";
CM_ BO_ 492 "Reserve";
CM_ SG_ 492 RECEND "Recording end notification";
CM_ SG_ 492 DRAVNABN "Drive recorder(AVN) malfunction notification";
CM_ SG_ 492 RECRNON "Record reason IG-ON";
CM_ SG_ 492 IMGI_POF "Output Image Request(IG-OFF PVM)";
CM_ SG_ 492 DVRACT "DVR active notification";
CM_ SG_ 492 DISCODET "Disconnection Detection Mode";
CM_ SG_ 492 SET_PCON "Continuous Record while Parking Setting Notification";
CM_ SG_ 492 SET_PALM "Parking Record Start/Stop Setting Notification";
CM_ SG_ 492 SET_PG "Impact Detection Setting Notification";
CM_ SG_ 492 SET_ALL "Record Start/Stop Setting Notification";
CM_ SG_ 492 ROLLCNT "Rolling counter";
CM_ BO_ 858 "Reserve";
CM_ SG_ 858 QIC_MTS "Integrated Cabin Control Change Selection Mode Target Seat";
CM_ SG_ 858 QIC_MTM "Integrated Cabin Control Change Selection Mode Target Mode";
CM_ SG_ 858 QIC_FSS "Integrated Cabin Control Fragrance Setting Strength";
CM_ SG_ 858 QIC_MPTS "Integrated Cabin Control Mode Replay Request Target Seat";
CM_ SG_ 858 QIC_MPTM "Integrated Cabin Control Mode Replay Request Target Mode";
CM_ SG_ 858 QIC_MPQK "Integrated Cabin Control Mode Replay Request Type";
CM_ SG_ 858 QIC_FTS "Integrated Cabin Control Fragrance Setting Target Seat";
CM_ SG_ 858 QIC_FTM "Integrated Cabin Control Fragrance Setting Target Mode";
CM_ SG_ 858 QIC_FSP "Integrated Cabin Control Fragrance Setting Pattern";
CM_ SG_ 858 QIC_BTS "Integrated Cabin Control BGM Setting Target Seat";
CM_ SG_ 858 SIC_BCS "Integrated Cabin Control BGM Current State";
CM_ SG_ 858 QIC_BTM "Integrated Cabin Control BGM Setting Target Mode";
CM_ SG_ 858 QIC_BSP "Integrated Cabin Control BGM Setting Pattern";
CM_ SG_ 858 SIC_RBCS "Integrated Cabin Control Rr BGM Current State";
CM_ SG_ 858 QIC_RTS "Integrated Cabin Control Memory Seat Setting Target Seat";
CM_ SG_ 858 QIC_RTM "Integrated Cabin Control Memory Seat Setting Target Mode";
CM_ SG_ 858 QIC_RSET "Integrated Cabin Control Memory Seat Setting";
CM_ SG_ 858 QIC_RSTS "Integrated Cabin Control Memory Seat Save Request Target Seat";
CM_ SG_ 858 QIC_RSTM "Integrated Cabin Control Memory Seat Save Request Target Mode";
CM_ SG_ 858 QIC_RKQK "Integrated Cabin Control Memory Seat Save Request Type";
CM_ SG_ 858 SIC_IDN "Integrated Cabin Control Interrupt Screen Display Number";
CM_ SG_ 858 SIC_IDS "Integrated Cabin Control Interrupt Screen Display State";
CM_ SG_ 858 AIC_IDA "Integrated Cabin Control Interrupt Screen Display Response";
CM_ SG_ 858 QDK_ADLQ "Digital key all delete request";
CM_ SG_ 858 QDK_ODRQ "Digital key owner delete request";
CM_ SG_ 858 QDK_OGRQ "Digital key owner device registration processing request";
CM_ SG_ 858 QDK_ORRQ "Digital key owner registration preonclination request";
CM_ SG_ 858 QDK_OWCQ "Digital key owner checking request";
CM_ SG_ 858 QDK_OCRQ "Digital key owner device change preonclination request";
CM_ SG_ 858 QDK_FDRQ "Digital key removal service request for the friend";
CM_ SG_ 858 SIC_RSES "Integrated Cabin Control Rr RSE Current State";
CM_ SG_ 858 QDK_CRQ "DigitalKey certification request";
CM_ SG_ 858 SLID_REQ "DigitalKey registration slotID# acquisition request";
CM_ SG_ 858 QSM_CARE "Smart key collation area";
CM_ SG_ 858 QSM_CQTI "The key ID that is targeted for a smart key";
CM_ SG_ 858 QSM_CRNG "Smart key collation range";
CM_ SG_ 858 QSM_CRQ "Smart key collation request";
CM_ SG_ 858 QCL_OPEQ "Electric charge lid - operation demand";
CM_ SG_ 858 QCL_RQTG "Power Charging Lid operation demand -Target";
CM_ SG_ 858 QRS_OPEQ "Rear sunshade operation request";
CM_ SG_ 858 QDK_CARE "Digital key certificationarea request";
CM_ SG_ 858 QDK_CQTI "Digital key certification Key ID request";
CM_ SG_ 858 QDK_CRNG "Digital key certification range request";
CM_ SG_ 858 QDK_DLTI "Digital key deletion Key ID request";
CM_ BO_ 787 "Reserve";
CM_ SG_ 787 RSAVN1 "Remote Service Response 1 from AVN";
CM_ SG_ 787 RSAVN2 "Remote Service Response 2 from AVN";
CM_ SG_ 787 RSAVN3 "Remote Service Response 3 from AVN";
CM_ SG_ 787 RSAVN4 "Remote Service Response 4 from AVN";
CM_ SG_ 787 RSAVN5 "Remote Service Response 5 from AVN";
CM_ SG_ 787 RSAVN6 "Remote Service Response 6 from AVN";
CM_ SG_ 787 RSAVN7 "Remote Service Response 7 from AVN";
CM_ SG_ 787 RSAVN8 "Remote Service Response 8 from AVN";
CM_ BO_ 1301 "Reserve";
CM_ SG_ 1301 MS_MD "Music-linked illumination mode";
CM_ SG_ 1301 MS_ILDTP "Music-linked illumination fade";
CM_ SG_ 1301 MS_ILDTT "Music-linked illumination fade time";
CM_ SG_ 1301 MS_ILLB1 "Music-linked illumination1 luminance level ";
CM_ SG_ 1301 MS_ILLB2 "Music-linked illumination2 luminance level";
CM_ SG_ 1301 MS_ILLB3 "Music-linked illumination3 luminance level";
CM_ SG_ 1301 MS_ILLB4 "Music-linked illumination4 luminance level";
CM_ SG_ 1301 MS_ILLB5 "Music-linked illumination5 luminance level";
CM_ SG_ 1301 MS_ILLB6 "Music-linked illumination6 luminance level";
CM_ SG_ 1301 MS_ILCL1 "Music-linked illumination1 lighting color";
CM_ SG_ 1301 MS_ILCL2 "Music-linked illumination2 lighting color";
CM_ SG_ 1301 MS_ILCL3 "Music-linked illumination3 lighting color";
CM_ SG_ 1301 MS_ILCL4 "Music-linked illumination4 lighting color";
CM_ SG_ 1301 MS_ILCL5 "Music-linked illumination5 lighting color";
CM_ SG_ 1301 MS_ILCL6 "Music-linked illumination6 lighting color";
CM_ BO_ 722 "Reserve";
CM_ SG_ 722 SVCRADC "Software part numbar check result fot A-DC";
CM_ SG_ 722 SVCRFRD "Software part numbar check result fot Front Radar";
CM_ SG_ 722 SVCRFRR "Software part numbar check result fot Front Right Radar";
CM_ SG_ 722 SVCRFLR "Software part numbar check result fot Front Left Radar";
CM_ SG_ 722 SVCRRRR "Software part numbar check result fot Rear Right Radar";
CM_ SG_ 722 SVCRRLR "Software part numbar check result fot Rear Left Radar";
CM_ SG_ 722 SVCRBDCF "Software part numbar check result fot B-DC(Front)";
CM_ SG_ 722 SVCRBDCR "Software part numbar check result fot B-DC(Right)";
CM_ SG_ 722 SVCRBDCL "Software part numbar check result fot B-DC(Left)";
CM_ SG_ 722 SVCRCDC "Software part numbar check result fot C-DC";
CM_ SG_ 722 SVCRDCM "Software part numbar check result fot DCM";
CM_ SG_ 722 SVCRLFR "Software part numbar check result fot Lidar";
CM_ SG_ 722 SVCRDDC "Software part numbar check result fot D-DC";
CM_ SG_ 722 SVCRALL "Software part numbar check result";
CM_ SG_ 722 SVCRREV1 "Software part numbar check result fot Reserve_1";
CM_ SG_ 722 SVCRREV2 "Software part numbar check result fot Reserve_2";
CM_ BO_ 498 "Reserve";
CM_ SG_ 498 CSET_PAD "Approch Detection Start/Stop Setting Notification";
CM_ SG_ 498 DRRECRN "Record reason IG-ON";
CM_ SG_ 498 DRACT "DVR active notification";
CM_ SG_ 498 OFFS_PAD "Approch Detection Request (OFF Spot)";
CM_ SG_ 498 CSET_PG "Impact Detection Setting Notification";
CM_ SG_ 498 CSET_PAA "Parking Record Start/Stop Setting Notification";
CM_ SG_ 498 CSET_ALL "Record Start/Stop Setting Notification";
CM_ SG_ 498 RMSETACK "Settting end notification";
CM_ SG_ 498 STRMACK "Streaming end notification";
CM_ SG_ 498 PROTACK "Protect end notification";
CM_ SG_ 498 HLREQ "Head lamp Request";
CM_ SG_ 498 OFFS_PG "Parking Record Request (OFF Spot)";
CM_ SG_ 498 STATACK "Status notification";
CM_ SG_ 498 DRCDCABN "Drive recorder(CDC) malfunction notification";
CM_ SG_ 498 DRDISMOD "Disconnection Detection Mode";
CM_ BO_ 724 "Reserve";
CM_ SG_ 724 UMOPIF01 "Upper Manager IF_ID";
CM_ SG_ 724 UMOPRQ01 "Request ID";
CM_ SG_ 724 UMOPRV01 "reserve";
CM_ SG_ 724 UMOPRD01 "Operation Request Data";
CM_ SG_ 724 FV2D4 "AVN1SC1 Freshness Value";
CM_ SG_ 724 KZK2D4 "AVN1SC1 KZKValue";
CM_ BO_ 725 "Reserve";
CM_ SG_ 725 UMOPIF02 "Upper Manager IF_ID";
CM_ SG_ 725 UMOPRQ02 "Request ID";
CM_ SG_ 725 UMOPRV02 "reserve";
CM_ SG_ 725 UMOPRD02 "Operation Request Data";
CM_ SG_ 725 FV2D5 "AVN1SC2 Freshness Value";
CM_ SG_ 725 KZK2D5 "AVN1SC2 KZKValue";
CM_ BO_ 726 "Reserve";
CM_ SG_ 726 UMOPIF03 "Upper Manager IF_ID";
CM_ SG_ 726 UMOPRQ03 "Request ID";
CM_ SG_ 726 UMOPRV03 "reserve";
CM_ SG_ 726 UMOPRD03 "Operation Request Data";
CM_ SG_ 726 FV2D6 "AVN1SC3 Freshness Value";
CM_ SG_ 726 KZK2D6 "AVN1SC3 KZKValue";
CM_ BO_ 727 "Reserve";
CM_ SG_ 727 UMOPIF04 "Upper Manager IF_ID";
CM_ SG_ 727 UMOPRQ04 "Request ID";
CM_ SG_ 727 UMOPRV04 "reserve";
CM_ SG_ 727 UMOPRD04 "Operation Request Data";
CM_ SG_ 727 FV2D7 "AVN1SC4 Freshness Value";
CM_ SG_ 727 KZK2D7 "AVN1SC4 KZKValue";
CM_ BO_ 735 "Reserve";
CM_ SG_ 735 UMOPIF05 "Upper Manager IF_ID";
CM_ SG_ 735 UMOPRQ05 "Request ID";
CM_ SG_ 735 UMOPRV05 "reserve";
CM_ SG_ 735 UMOPRD05 "Operation Request Data";
CM_ SG_ 735 FV2DF "AVN1SC5 Freshness Value";
CM_ SG_ 735 KZK2DF "AVN1SC5 KZKValue";
CM_ BO_ 736 "Reserve";
CM_ SG_ 736 UMOPIF06 "Upper Manager IF_ID";
CM_ SG_ 736 UMOPRQ06 "Request ID";
CM_ SG_ 736 UMOPRV06 "reserve";
CM_ SG_ 736 UMOPRD06 "Operation Request Data";
CM_ SG_ 736 FV2E0 "AVN1SC6 Freshness Value";
CM_ SG_ 736 KZK2E0 "AVN1SC6 KZKValue";
CM_ BO_ 737 "Reserve";
CM_ SG_ 737 UMOPIF07 "Upper Manager IF_ID";
CM_ SG_ 737 UMOPRQ07 "Request ID";
CM_ SG_ 737 UMOPRV07 "reserve";
CM_ SG_ 737 UMOPRD07 "Operation Request Data";
CM_ SG_ 737 FV2E1 "AVN1SC7 Freshness Value";
CM_ SG_ 737 KZK2E1 "AVN1SC7 KZKValue";
CM_ BO_ 738 "Reserve";
CM_ SG_ 738 UMOPIF08 "Upper Manager IF_ID";
CM_ SG_ 738 UMOPRQ08 "Request ID";
CM_ SG_ 738 UMOPRV08 "reserve";
CM_ SG_ 738 UMOPRD08 "Operation Request Data";
CM_ SG_ 738 FV2E2 "AVN1SC8 Freshness Value";
CM_ SG_ 738 KZK2E2 "AVN1SC8 KZKValue";
CM_ BO_ 751 "Reserve";
CM_ SG_ 751 UMOPIF09 "Upper Manager IF_ID";
CM_ SG_ 751 UMOPRQ09 "Request ID";
CM_ SG_ 751 UMOPRV09 "reserve";
CM_ SG_ 751 UMOPRD09 "Operation Request Data";
CM_ SG_ 751 FV2EF "AVN1SC9 Freshness Value";
CM_ SG_ 751 KZK2EF "AVN1SC9 KZKValue";
CM_ BO_ 752 "Reserve";
CM_ SG_ 752 UMOPIF10 "Upper Manager IF_ID";
CM_ SG_ 752 UMOPRQ10 "Request ID";
CM_ SG_ 752 UMOPRV10 "reserve";
CM_ SG_ 752 UMOPRD10 "Operation Request Data";
CM_ SG_ 752 FV2F0 "AVN1SD1 Freshness Value";
CM_ SG_ 752 KZK2F0 "AVN1SD1 KZKValue";
CM_ BO_ 754 "Reserve";
CM_ SG_ 754 UMOPIF11 "Upper Manager IF_ID";
CM_ SG_ 754 UMOPRQ11 "Request ID";
CM_ SG_ 754 UMOPRV11 "reserve";
CM_ SG_ 754 UMOPRD11 "Operation Request Data";
CM_ SG_ 754 FV2F2 "AVN1SD2 Freshness Value";
CM_ SG_ 754 KZK2F2 "AVN1SD2 KZKValue";
CM_ BO_ 757 "Reserve";
CM_ SG_ 757 UMOPIF12 "Upper Manager IF_ID";
CM_ SG_ 757 UMOPRQ12 "Request ID";
CM_ SG_ 757 UMOPRV12 "reserve";
CM_ SG_ 757 UMOPRD12 "Operation Request Data";
CM_ SG_ 757 FV2F5 "AVN1SCD3 Freshness Value";
CM_ SG_ 757 KZK2F5 "AVN1SD3 KZKValue";
CM_ BO_ 389 "Reserve";
CM_ SG_ 389 DSADINX "Driver Side Electric register air direction indication signal(X)";
CM_ SG_ 389 DSADINY "Driver Side Electric register air direction indication signal(Y)";
CM_ SG_ 389 DSSHTSW "Driver Side Electric register shut SW signal";
CM_ SG_ 389 DCADINX "Driver Center Electric register air direction indication signal(X)";
CM_ SG_ 389 DCADINY "Driver Center Electric register air direction indication signal(Y)";
CM_ SG_ 389 DCSHTSW "Driver Center Electric register shut SW signal";
CM_ SG_ 389 PSADINX "Passenger Side Electric register air direction indication signal(X)";
CM_ SG_ 389 PSADINY "Passenger Side Electric register air direction indication signal(Y)";
CM_ SG_ 389 PSSHTSW "Passenger Side Electric register shut SW signal";
CM_ SG_ 389 PCADINX "Passenger Center Electric register air direction indication signal(X)";
CM_ SG_ 389 PCADINY "Passenger Center Electric register air direction indication signal(Y)";
CM_ SG_ 389 PCSHTSW "Passenger Center Electric register shut SW signal";
CM_ SG_ 389 RRCADINX "RR Center Electric register air direction indication signal(X)";
CM_ SG_ 389 RRCADINY "RR Center Electric register air direction indication signal(Y)";
CM_ SG_ 389 RRCSHTSW "RR Center Electric register shut SW signal";
CM_ SG_ 389 RLCADINX "RL Center Electric register air direction indication signal(X)";
CM_ SG_ 389 RLCADINY "RL Center Electric register air direction indication signal(Y)";
CM_ SG_ 389 RLCSHTSW "RL Center Electric register shut SW signal";
CM_ SG_ 389 ERSWISWD "Electric register Swing SW signal for Driver seat";
CM_ SG_ 389 BLMDCUST "Electric register blow mode customization SW signal";
CM_ SG_ 389 DSPADIN "Driver Side Electric register air direction indication of parts signal";
CM_ SG_ 389 DCPADIN "Driver Center Electric register air direction indication of parts signal";
CM_ SG_ 389 PSPADIN "Passenger Side Electric register air direction indication of parts signal";
CM_ SG_ 389 PCPADIN "Passenger Center Electric register air direction indication of parts signal";
CM_ SG_ 389 RRCPADIN "RR Center Electric register air direction indication of parts signal";
CM_ SG_ 389 RLCPADIN "RL Center Electric register air direction indication of parts signal";
CM_ SG_ 389 ERSWISWP "Electric register Swing SW signal for Passenger seat";
CM_ SG_ 389 ERSPTSWP "Electric register Swing SW signal for Passenger seat";
CM_ SG_ 389 ERSPRSWP "Electric register Swing SW signal for Passenger seat";
CM_ SG_ 389 ERSPTSWD "Electric register Swing SW signal for Driver seat";
CM_ SG_ 389 ERSPRSWD "Electric register Swing SW signal for Driver seat";
CM_ BO_ 758 "Reserve";
CM_ SG_ 758 PDRVSTS "Status of  driver1 registration";
CM_ SG_ 758 PFR1STS "Status of  friend1 registration";
CM_ SG_ 758 PFR2STS "Status of  friend2 registration";
CM_ BO_ 760 "Reserve";
CM_ SG_ 760 SBCGROTA "Charge request for sub-Li Battery & Suitable temperature.";
CM_ SG_ 760 SBCRVOTA "Amount of  Charge request.";
CM_ SG_ 760 RDYOF_RQ "Vehicle Power Ready ON disable request";
CM_ BO_ 762 "Reserve";
CM_ SG_ 762 ECUPWCRQ "Power Controlre quest for individual ECU.";
CM_ SG_ 762 PWCRQMOD "Request Power ON/OFF";
CM_ SG_ 762 PWCRQID "Power ON/OFF request ID for individual ECU.";
CM_ SG_ 762 PWCTID01 "Tareget ECU 1 ID for power ON/OFF.";
CM_ SG_ 762 PWCTID02 "Tareget ECU 2 ID for power ON/OFF.";
CM_ SG_ 762 PWCTID03 "Tareget ECU 3 ID for power ON/OFF.";
CM_ SG_ 762 PWCTID04 "Tareget ECU 4 ID for power ON/OFF.";
CM_ SG_ 762 PWCTID05 "Tareget ECU 5 ID for power ON/OFF.";
CM_ SG_ 762 PWCTID06 "Tareget ECU 6 ID for power ON/OFF.";
CM_ SG_ 762 PWCTID07 "Tareget ECU 7 ID for power ON/OFF.";
CM_ SG_ 762 PWCTID08 "Tareget ECU 8 ID for power ON/OFF.";
CM_ SG_ 762 PWCTID09 "Tareget ECU 9 ID for power ON/OFF.";
CM_ SG_ 762 PWCTID10 "Tareget ECU 10 ID for power ON/OFF.";
CM_ BO_ 763 "Reserve";
CM_ SG_ 763 VPSCROTA "Power state change request for OTA. (each Special)";
CM_ BO_ 826 "Reserve";
CM_ SG_ 826 A_DPSRQ "departure plan setting request";
CM_ SG_ 826 A_DPID "Setting ID of departure plan ";
CM_ SG_ 826 A_DPON "Enable/disable of departure plan";
CM_ SG_ 826 A_DPTYP "Type selection of departure plan ";
CM_ SG_ 826 A_DPDAY "Day selection of departure plan ";
CM_ SG_ 826 A_DPMON "Month selection of departure plan ";
CM_ SG_ 826 A_DPDAT "Date selection of departure plan ";
CM_ SG_ 826 A_DPDTM "Departure time of departure plan ";
CM_ SG_ 826 A_DPAC "Enable/disable of AC setting of departure plan ";
CM_ SG_ 826 A_DPBC "Enable/disable of Battery preconditioning of departure plan ";
CM_ SG_ 826 A_DPTMP "Temperature setting for departure plan";
CM_ SG_ 826 A_DPACMD "
Mode setting of HVAC for departure plan";
CM_ SG_ 826 A_DPSH "Steering heater setting for departure plan";
CM_ SG_ 826 A_DPREFR "Fresh and recirculation setting for departure plan";
CM_ SG_ 826 A_DPBLLV "Blower level setting for departure plan";
CM_ SG_ 826 A_DPFDHV "Fr Dr seat heater and ventilation setting for departure plan";
CM_ SG_ 826 A_DPFPHV "Fr Pa seat heater and ventilation setting of preconditioning HVAC";
CM_ SG_ 826 A_DPRDHV "Rr Dr seat heater and ventilation setting for departure plan";
CM_ SG_ 826 A_DPRPHV "Rr Pa seat heater and ventilation setting for departure plan";
CM_ SG_ 826 A_DPFDEF "Front defroster setting of preconditioning HVAC";
CM_ SG_ 826 A_DPRDEF "Rear defogger and mirror heater setting for departure plan";
CM_ SG_ 826 A_DPFGON "Fragrance ON /OFF for departure plan";
CM_ SG_ 826 A_DPFGLV "Fragrance spray concentration setting for departure plan";
CM_ SG_ 826 A_DPFGCH "Fragrance cartridge type setting for departure plan";
CM_ SG_ 826 A_DPACTM "Remote AC startup time before departure time (minute)";
CM_ SG_ 826 MRONPSH "My Room Mode ON Switch Push";
CM_ SG_ 826 MROFFPSH "My Room Mode OFF Switch Push";
CM_ SG_ 826 MRSOCSEL "My Room SOC Select";
CM_ SG_ 826 MRMETSEL "My Room Mode Meter Select";
CM_ SG_ 826 MRMETANS "My Room Mode Meter Setting Answer";
CM_ SG_ 826 EXONPSH "Exihibition Mode ON Switch Push";
CM_ SG_ 826 EXOFFPSH "Exihibition Mode OFF Switch Push";
CM_ SG_ 826 SMTRDYSW "Smart Ready On User Setting";
CM_ SG_ 826 TMEXOP "Timer Extension Operation Notification";
CM_ BO_ 1086 "Reserve";
CM_ SG_ 1086 ID6F820 "AVN1S35 Sub ID";
CM_ SG_ 1086 IF6F820 "AVN1S35 INFO";
CM_ SG_ 1086 A_SETSTS "Display Status";
CM_ SG_ 1086 A_BPON "Setting enable/disable of battery preconditioning";
CM_ SG_ 1086 A_BPWKD "Battery preconditioning weekday select";
CM_ SG_ 1086 A_BPID "Battery preconditioning setting ID";
CM_ SG_ 1086 A_DEPTM "Departure time of battery preconditioning";
CM_ SG_ 1086 A_BPNXT "Timer setup request of battery preconditioning";
CM_ SG_ 1086 A_BPSET "Battery preconditioning setting";
CM_ SG_ 1086 A_ACSET "Air conditioning setting";
CM_ SG_ 1086 ID6F821 "AVN1S35 Sub ID";
CM_ SG_ 1086 IF6F821 "AVN1S35 INFO";
CM_ SG_ 1086 A_NCTYP "Charge Setting type";
CM_ SG_ 1086 A_NCWKD "Charge Weekday Select";
CM_ SG_ 1086 A_NCSTM "Charge Start Time";
CM_ SG_ 1086 A_NCFTM "Charge Finish Time ";
CM_ SG_ 1086 A_SETID "Setting ID";
CM_ SG_ 1086 A_SETON "Setting enable/disable";
CM_ SG_ 1086 A_SETWKD "Weekday Select";
CM_ SG_ 1086 A_SETTYP "Setting Type";
CM_ SG_ 1086 A_SETSTM "Start Time";
CM_ SG_ 1086 A_SETNXT "Timer Set Request";
CM_ SG_ 1086 A_SETFTM "Finish Time";
CM_ SG_ 1086 A_SETID2 "Setting ID Sub";
CM_ SG_ 1086 A_SETON2 "Setting enable/disable Sub";
CM_ SG_ 1086 A_SETRE2 "Weekday Select Sub";
CM_ SG_ 1086 A_SETMO2 "Setting Type Sub";
CM_ SG_ 1086 A_SETST2 "Start Time Sub";
CM_ SG_ 1086 A_SETNX2 "Timer Set Request Sub";
CM_ SG_ 1086 A_SETFT2 "End Time Sub";
CM_ SG_ 1086 A_LMTRE2 "Charging Limit Request Sub";
CM_ SG_ 1086 A_OCTID "Optimal charging configuration ID";
CM_ SG_ 1086 A_OCOKNG "Optimal Charging On/off state";
CM_ SG_ 1086 A_VPPREQ "Smart Charging ON/OFF Swich";
CM_ SG_ 1086 A_LMTACC "Charging Limit Request after IG-OFF";
CM_ BO_ 1548 "Reserve";
CM_ SG_ 1548 PVMINFO "PVM Information";
CM_ SG_ 1548 PVMERR "PVM Error Condition";
CM_ SG_ 1548 MAVMUTE "CSR Mute SW Press Information";
CM_ SG_ 1548 CS_FDIST "Setting of the Fr distance to display CSA";
CM_ SG_ 1548 CS_RDIST "Setting of the Rr distance to display CSA";
CM_ SG_ 1548 MOASW "MOA ON OFF SW Press Information";
CM_ SG_ 1548 AUTOONAL "Auto-on  Alert  SW  Press Information";
CM_ SG_ 1548 RCD_DE "RCD Dealer SW Press Information";
CM_ SG_ 1548 CSR_WA "CSR Wall SW Press Information";
CM_ SG_ 1548 PVMHSW "Camera soft SW Flag";
CM_ SG_ 1548 PVM_WASH "Camera washer SW status";
CM_ SG_ 1548 FCWCTSW "China Foward Collision Warning Customization operation FB (Foward Collision Warningt)";
CM_ SG_ 1548 FCWSESW "China Foward Collision Warning Sensitiveness Customization operation FB";
CM_ SG_ 1548 CDWCTSW "ChinaCDW Customization operation FB (CDW)";
CM_ SG_ 1548 TLACTSW "ChinaTLA Customization operation FB (TLA)";
CM_ SG_ 1548 SLFCTSW "ChinaSLIF Customization operation FB ";
CM_ SG_ 1548 CSWCTSW "ChinaCSW Customization operation FB (CSW)";
CM_ SG_ 1548 AESCTSW "ChinaAES Customization operation FB (AES)";
CM_ SG_ 1548 ACCCTSW "ChinaACC Customization operation FB (ACC)";
CM_ SG_ 1548 CPCTSW "ChinaCP Customization operation FB (CP)";
CM_ SG_ 1548 LDKCTSW "China LDA/LKA Customization operation FB";
CM_ SG_ 1548 LDKSNSW "China LDA/LKA Sensitiveness Customization operation FB";
CM_ SG_ 1548 ELKCTSW "China ELK Customization operation FB";
CM_ SG_ 1548 ELKMDSW "China ELK Mode Customization operation FB";
CM_ SG_ 1548 GDNCTSW " Guardian2.0 Customization operation FB";
CM_ SG_ 1548 GDNWNSW " Guardian2.0 Warning Customize operation FB";
CM_ SG_ 1548 GDNBKSW " Guardian2.0Brake Control Setting operation FB";
CM_ SG_ 1548 GDNSTSW " Guardian2.0 Steering Conrto settingl operation FB";
CM_ SG_ 1548 GDNSNSW " Guardian2.0 Sensitiveness operation FB";
CM_ SG_ 1548 RCPMCTSW "ChinaRCPM Customization operation FB (RCPM)";
CM_ SG_ 1548 NPCS4SW "NP customization function 4 Customization  operation FB(HNP/UNP/CNP Voice Operation)";
CM_ SG_ 1548 NPCS5SW "NP customization function 5 Customization  operation FB(HNP/UNP/CNP Voice Interaction)";
CM_ SG_ 1548 NPCS6SW "NP customization function 6 Customization  operation FB(HNP/UNP/CNP Confidence Level)";
CM_ SG_ 1548 NPCS7SW "NP customization function 7 Customization  operation FB(HNP/UNP/CNP LC notification)";
CM_ SG_ 1548 NPCS8SW "NP customization function 8 Customization  operation FB(HNP/UNP/CNP Speed Transition)";
CM_ SG_ 1548 NPCS9SW "NP customization function 9 Customization  operation FB(HNP/UNP/CNP Speed Transition Unit)";
CM_ SG_ 1548 NPCS10SW "NP customization function 10 Customization  operation FB(HNP/UNP/CNP Driving Style)";
CM_ SG_ 1548 NPCS11SW "NP customization function 11 Customization  operation FB(HNP/UNP/CNP Lane Change Frequency)";
CM_ SG_ 1548 NPCS12SW "NP customization function 12 Customization  operation FB(HNP/UNP/CNP Big Data Speed Control)";
CM_ SG_ 1548 NPCS13SW "NP customization function 13 Customization  operation FB(HNP/UNP/CNP VLO)";
CM_ SG_ 1548 NPCS14SW "NP customization function 14 Customization  operation FB(HNP/UNP/CNP Overtake Flash)";
CM_ SG_ 1548 NPCS15SW "NP customization function 15 Customization  operation FB(HNP/UNP/CNP Activate Suggestion)";
CM_ SG_ 1548 NPCS16SW "NP customization function 16 Customization  operation FB(HNP/UNP/CNP Upgrade Operation)";
CM_ SG_ 1548 NPCS17SW "NP customization function 17 Customization  operation FB(HNP/UNP/CNP)";
CM_ SG_ 1548 NPCS18SW "NP customization function 18 Customization  operation FB(HNP/UNP/CNP)";
CM_ SG_ 1548 NPCS19SW "NP customization function 19 Customization  operation FB(HNP/UNP/CNP)";
CM_ SG_ 1548 NPCS20SW "NP customization function 20 Customization  operation FB(HNP/UNP/CNP)";
CM_ SG_ 1548 ESSCTSW "China ESS Customization operation FB (Foward Collision Warningt)";
CM_ BO_ 739 "Reserve";
CM_ SG_ 739 GRLGDBOP "Cutomize operation signal of distribution ratio between left and right for Grip mode";
CM_ SG_ 739 CNV1_SW "Conversino mode selection 1";
CM_ SG_ 739 CNV2_SW "Conversino mode selection 2";
CM_ SG_ 739 CNV3_SW "Conversino mode selection 3";
CM_ SG_ 739 CNV4_SW "Conversino mode selection 4";
CM_ SG_ 739 CNV5_SW "Conversino mode selection 5";
CM_ SG_ 739 CNV6_SW "Conversino mode selection 6";
CM_ SG_ 739 CNV7_SW "Conversino mode selection 7";
CM_ SG_ 739 CNV8_SW "Conversino mode selection 8";
CM_ SG_ 739 CNV9_SW "Conversino mode selection 9";
CM_ SG_ 739 CNV10_SW "Conversino mode selection 10";
CM_ SG_ 739 CNV11_SW "Conversino mode selection 11";
CM_ SG_ 739 CNV12_SW "Conversino mode selection 12";
CM_ SG_ 739 CNV13_SW "Conversino mode selection 13";
CM_ SG_ 739 CNV14_SW "Conversino mode selection 14";
CM_ SG_ 739 CNV15_SW "Conversino mode selection 15";
CM_ SG_ 739 CNV16_SW "Conversino mode selection 16";
CM_ BO_ 532 "Reserve";
CM_ SG_ 532 ABPCH "Available Battery Power";
CM_ SG_ 532 CBPCH "Current Battery Power";
CM_ SG_ 532 BATCI "Battery Cathodic deposition Indicator";
CM_ SG_ 532 FULLCAPR "Fullcap for Routeplanner";
CM_ SG_ 532 BATTYPER "Battery Type for Routeplanner";
CM_ SG_ 532 SOC_GR "SOC global for Routeplanner";
CM_ SG_ 532 TBMAX_GR "TBMAX_global for Routeplanner";
CM_ SG_ 532 TBMIN_GR "TBMIN_global for Routeplanner";
CM_ SG_ 532 RBSCC_A "Remaining Batterypower to SOC Convert Coefficient A";
CM_ SG_ 532 RBSCC_B "Remaining Batterypower to SOC Convert Coefficient B";
CM_ SG_ 532 RBSCC_C "Remaining Batterypower to SOC Convert Coefficient C";
CM_ SG_ 532 RBSCC_D "Remaining Batterypower to SOC Convert Coefficient D";
CM_ BO_ 366 "Reserve";
CM_ SG_ 366 BIB_G "IB0 for Global-Bus";
CM_ SG_ 366 VCELMAXG "VCELL MAX for Global-Bus";
CM_ SG_ 366 VCELMING "VCELL MIN for Global-Bus";
CM_ SG_ 366 RAHRMAXG "RAHR_MAX for Global-Bus";
CM_ SG_ 366 RAHRMING "RAHR_MIN for Global-Bus";
CM_ SG_ 366 TC_G "TC for Global-Bus";
CM_ SG_ 366 TBMAX_G "TBMAX for Global-Bus";
CM_ SG_ 366 TBMIN_G "TBMIN for Global-Bus";
CM_ BO_ 997 "Reserve";
CM_ SG_ 997 BS_CHK_B "HV Battery State Check";
CM_ SG_ 997 BHEATSW "Battery Heat SW";
CM_ SG_ 997 BCOOLSW "Battery Cool SW";
CM_ SG_ 997 TBW_EN "Battery heater customization switch indication enable";
CM_ SG_ 997 CHGLMTDA "Disable upper limit setting notification";
CM_ SG_ 997 FCHGSUG "Full-Charging suggestion notification";
CM_ SG_ 997 LBTYPE_E "Battery type(ECO)";
CM_ BO_ 292 "Reserve";
CM_ SG_ 292 BTWO "Battery Outlet Water Temperature";
CM_ BO_ 341 "Reserve";
CM_ SG_ 341 BSOCE "State of certified energy";
CM_ SG_ 341 BSOH "Traction Battery Pack State of Health";
CM_ SG_ 341 BSOHDST "Distance Since Last SOH Update";
CM_ SG_ 341 BSOHSWID "SOH/SOCE switch ID value";
CM_ BO_ 889 "Reserve";
CM_ SG_ 889 RM_DISP "Request of the display using (from camera system)";
CM_ SG_ 889 MAV_ERR "Camera error state signal";
CM_ SG_ 889 MAV_BP_S "Request of short BEEP";
CM_ SG_ 889 MAV_BP_L "Request of Long BEEP";
CM_ SG_ 889 ENBLMMSW "Camera soft SW Flag";
CM_ SG_ 889 MAVTYPE "System Type";
CM_ SG_ 889 R_CROP_0 "Video cutout request for center display";
CM_ BO_ 907 "Reserve";
CM_ SG_ 907 SALR "Security control signal";
CM_ SG_ 907 HDCY_BDB "Hood courtesy SW signal";
CM_ SG_ 907 ALM_EQ "Alarm equipment";
CM_ SG_ 907 AARE_B "alarm reason";
CM_ SG_ 907 INTSET_B "Intrusion-senser-set";
CM_ SG_ 907 INCSET_B "Intrusion-senser-set";
CM_ SG_ 907 INT_EQ "Intrusion sensor equipment";
CM_ SG_ 907 ISSD_BDB "Invasion sensor state display";
CM_ BO_ 909 "Reserve";
CM_ SG_ 909 DPM_R1 "Driving position memory 1 registration completed notification";
CM_ SG_ 909 DPM_R2 "Driving position memory 2 registration completed notification";
CM_ SG_ 909 DPM_R3 "Driving position memory 3 registration completed notification";
CM_ SG_ 909 DPP_R1 "Driving position memory 1 playback status notification";
CM_ SG_ 909 DPP_R2 "Driving position memory 2 playback status notification";
CM_ SG_ 909 DPP_R3 "Driving position memory 3 playback status notification";
CM_ SG_ 909 DPMS_INT "Request for driving position emergency stop screen";
CM_ SG_ 909 DPM1_FNC "Driving position memory 1 function presence";
CM_ SG_ 909 DPM1_VLD "Driving position memory 1 playback switch enable";
CM_ SG_ 909 DPS1_VLD "Driving position memory 1 registration switch enable";
CM_ SG_ 909 DPM2_FNC "Driving position memory 2 function presence";
CM_ SG_ 909 DPM2_VLD "Driving position memory 2 playback switch enable";
CM_ SG_ 909 DPS2_VLD "Driving position memory 2 registration switch enable";
CM_ SG_ 909 DPM3_FNC "Driving position memory 3 function presence";
CM_ SG_ 909 DPM3_VLD "Driving position memory 3 playback switch enable";
CM_ SG_ 909 DPS3_VLD "Driving position memory 3 registration switch enable";
CM_ SG_ 909 DRVPS_DT "Driver Position Data(Driver's seat, Ti&Te and Mirror)";
CM_ SG_ 909 HUD_R "HUD Position Request";
CM_ BO_ 500 "Reserve";
CM_ SG_ 500 ID63B16 "BDB1F03 Sub ID";
CM_ SG_ 500 IF63B16 "BDB1F03 INFO";
CM_ SG_ 500 TRIP_CNT "Trip count";
CM_ SG_ 500 TIME_CNT "Time count";
CM_ BO_ 463 "Reserve";
CM_ SG_ 463 RCOSW "Rear Center side Occupied SW signal";
CM_ SG_ 463 RROSW "Rear Right side Occupied SW signal";
CM_ SG_ 463 RLOSW "Rear Left side Occupied SW signal";
CM_ SG_ 463 POSW "Passenger's seat Occupied SW signal";
CM_ SG_ 463 ADIM "Auto dimmer signal";
CM_ SG_ 463 DCTY "Driver's seat courtesy SW signal";
CM_ SG_ 463 PCTY "Passenger's seat courtesy SW signal";
CM_ SG_ 463 RRCY "Rear right side courtesy SW signal";
CM_ SG_ 463 RLCY "Rear left side courtesy SW signal";
CM_ SG_ 463 BCTY "Back door courtesy SW signal";
CM_ SG_ 463 LGCY "luggage courtesy SW signal";
CM_ SG_ 463 PKB_BDB "Parking brake SW signal";
CM_ SG_ 463 SREXIST "Slide roof Exist information";
CM_ SG_ 463 SRPOS "Remote service/initialaize,Slide roof position";
CM_ BO_ 1569 "Reserve";
CM_ SG_ 1569 LUD "Door lock output factor";
BA_DEF_  "DBName" STRING ;
BA_DEF_  "Manufacturer" STRING ;
BA_DEF_  "BusType" STRING ;
BA_DEF_  "Baudrate" INT 1 1000000;
BA_DEF_  "VersionYear" INT 0 99;
BA_DEF_  "VersionMonth" INT 1 12;
BA_DEF_  "VersionDay" INT 1 31;
BA_DEF_  "VersionNumber" INT 0 65535;
BA_DEF_ BO_  "GenMsgILSupport" ENUM  "No","Yes";
BA_DEF_ BO_  "GenMsgSendType" ENUM  "Cyclic","NotUsed","NotUsed","NotUsed","NotUsed","NotUsed","NotUsed","NotUsed","NoMsgSendType";
BA_DEF_ SG_  "GenSigSendType" ENUM  "Cyclic","OnWrite","OnWriteWithRepetition","OnChange","OnChangeWithRepetition","NotUsed","NotUsed","NoSigSendType";
BA_DEF_ BO_  "GenMsgCycleTime" INT 0 65535;
BA_DEF_ SG_  "GenSigStartValue" FLOAT 0 100000000000;
BA_DEF_ BO_  "GenMsgStartDelayTime" INT 0 100000;
BA_DEF_ BO_  "VFrameFormat" ENUM  "StandardCAN","ExtendedCAN","reserved","reserved","reserved","reserved","reserved","reserved","reserved","reserved","reserved","reserved","reserved","reserved","StandardCAN_FD","ExtendedCAN_FD";
BA_DEF_ BO_  "CANFD_BRS" ENUM  "0","1";
BA_DEF_  "NmType" STRING ;
BA_DEF_ BU_  "NmAsrNode" ENUM  "No","Yes";
BA_DEF_ BU_  "NmStationAddress" HEX 0 127;
BA_DEF_ BU_  "NmAsrCanMsgReducedTime" INT 0 65535;
BA_DEF_ BU_  "NmAsrNodeIdentifier" HEX 0 255;
BA_DEF_  "NmAsrCanMsgCycleTime" INT 1 65535;
BA_DEF_  "NmAsrBaseAddress" HEX 0 536870911;
BA_DEF_  "NmAsrMessageCount" INT 0 255;
BA_DEF_  "NmAsrRepeatMessageTime" INT 1 65535;
BA_DEF_  "NmAsrWaitBusSleepTime" INT 1 65535;
BA_DEF_  "NmAsrTimeoutTime" INT 1 65535;
BA_DEF_ BO_  "NmAsrMessage" ENUM  "No","Yes";
BA_DEF_ BO_  "DiagState" ENUM  "No","Yes";
BA_DEF_ BO_  "DiagRequest" ENUM  "No","Yes";
BA_DEF_ BO_  "DiagResponse" ENUM  "No","Yes";
BA_DEF_ BO_  "DiagConnection" HEX 0 65535;
BA_DEF_ SG_  "SystemSignalLongSymbol" STRING ;
BA_DEF_DEF_  "DBName" "";
BA_DEF_DEF_  "Manufacturer" "Vector";
BA_DEF_DEF_  "BusType" "CAN FD";
BA_DEF_DEF_  "Baudrate" 500000;
BA_DEF_DEF_  "VersionYear" 20;
BA_DEF_DEF_  "VersionMonth" 1;
BA_DEF_DEF_  "VersionDay" 1;
BA_DEF_DEF_  "VersionNumber" 1;
BA_DEF_DEF_  "GenMsgILSupport" "No";
BA_DEF_DEF_  "GenMsgSendType" "NoMsgSendType";
BA_DEF_DEF_  "GenSigSendType" "NoSigSendType";
BA_DEF_DEF_  "GenMsgCycleTime" 0;
BA_DEF_DEF_  "GenSigStartValue" 0;
BA_DEF_DEF_  "GenMsgStartDelayTime" 0;
BA_DEF_DEF_  "VFrameFormat" "";
BA_DEF_DEF_  "CANFD_BRS" "1";
BA_DEF_DEF_  "NmType" "NmAsr";
BA_DEF_DEF_  "NmAsrNode" "No";
BA_DEF_DEF_  "NmStationAddress" 0;
BA_DEF_DEF_  "NmAsrCanMsgReducedTime" 500;
BA_DEF_DEF_  "NmAsrNodeIdentifier" 0;
BA_DEF_DEF_  "NmAsrCanMsgCycleTime" 1000;
BA_DEF_DEF_  "NmAsrBaseAddress" 1088;
BA_DEF_DEF_  "NmAsrMessageCount" 64;
BA_DEF_DEF_  "NmAsrRepeatMessageTime" 2500;
BA_DEF_DEF_  "NmAsrWaitBusSleepTime" 60000;
BA_DEF_DEF_  "NmAsrTimeoutTime" 3000;
BA_DEF_DEF_  "NmAsrMessage" "No";
BA_DEF_DEF_  "DiagState" "No";
BA_DEF_DEF_  "DiagRequest" "No";
BA_DEF_DEF_  "DiagResponse" "No";
BA_DEF_DEF_  "DiagConnection" 3000.00005758105;
BA_DEF_DEF_  "SystemSignalLongSymbol" "";
BA_ "VersionDay" 23;
BA_ "VersionMonth" 9;
BA_ "VersionYear" 2024;
BA_ "DBName" "CDC_GLOBAL_CAN_2M1";
BA_ "NmStationAddress" BU_ CDC 66;
BA_ "NmAsrNodeIdentifier" BU_ CDC 66;
BA_ "NmAsrNode" BU_ CDC 1;
BA_ "GenMsgILSupport" BO_ 1196 1;
BA_ "GenMsgSendType" BO_ 1196 0;
BA_ "GenMsgCycleTime" BO_ 1196 500;
BA_ "VFrameFormat" BO_ 1196 14;
BA_ "GenMsgILSupport" BO_ 1212 1;
BA_ "GenMsgSendType" BO_ 1212 0;
BA_ "GenMsgCycleTime" BO_ 1212 1000;
BA_ "VFrameFormat" BO_ 1212 14;
BA_ "GenMsgILSupport" BO_ 945 1;
BA_ "GenMsgSendType" BO_ 945 0;
BA_ "GenMsgCycleTime" BO_ 945 1000;
BA_ "VFrameFormat" BO_ 945 14;
BA_ "GenMsgILSupport" BO_ 1208 1;
BA_ "GenMsgSendType" BO_ 1208 0;
BA_ "GenMsgCycleTime" BO_ 1208 500;
BA_ "VFrameFormat" BO_ 1208 14;
BA_ "GenMsgILSupport" BO_ 929 1;
BA_ "GenMsgSendType" BO_ 929 0;
BA_ "GenMsgCycleTime" BO_ 929 1000;
BA_ "VFrameFormat" BO_ 929 14;
BA_ "GenMsgILSupport" BO_ 897 1;
BA_ "GenMsgSendType" BO_ 897 0;
BA_ "GenMsgCycleTime" BO_ 897 1000;
BA_ "VFrameFormat" BO_ 897 14;
BA_ "GenMsgILSupport" BO_ 898 1;
BA_ "GenMsgSendType" BO_ 898 0;
BA_ "GenMsgCycleTime" BO_ 898 5000;
BA_ "VFrameFormat" BO_ 898 14;
BA_ "GenMsgILSupport" BO_ 944 1;
BA_ "GenMsgSendType" BO_ 944 0;
BA_ "GenMsgCycleTime" BO_ 944 1000;
BA_ "VFrameFormat" BO_ 944 14;
BA_ "GenMsgILSupport" BO_ 1031 1;
BA_ "GenMsgSendType" BO_ 1031 0;
BA_ "GenMsgCycleTime" BO_ 1031 1000;
BA_ "VFrameFormat" BO_ 1031 14;
BA_ "GenMsgILSupport" BO_ 1032 1;
BA_ "GenMsgSendType" BO_ 1032 0;
BA_ "GenMsgCycleTime" BO_ 1032 1000;
BA_ "VFrameFormat" BO_ 1032 14;
BA_ "GenMsgILSupport" BO_ 852 1;
BA_ "GenMsgSendType" BO_ 852 0;
BA_ "GenMsgCycleTime" BO_ 852 1000;
BA_ "VFrameFormat" BO_ 852 14;
BA_ "GenMsgILSupport" BO_ 597 1;
BA_ "GenMsgSendType" BO_ 597 0;
BA_ "GenMsgCycleTime" BO_ 597 1000;
BA_ "VFrameFormat" BO_ 597 14;
BA_ "GenMsgILSupport" BO_ 1286 1;
BA_ "GenMsgSendType" BO_ 1286 0;
BA_ "GenMsgCycleTime" BO_ 1286 1000;
BA_ "VFrameFormat" BO_ 1286 14;
BA_ "GenMsgILSupport" BO_ 382 1;
BA_ "GenMsgSendType" BO_ 382 0;
BA_ "GenMsgCycleTime" BO_ 382 100;
BA_ "VFrameFormat" BO_ 382 14;
BA_ "GenMsgILSupport" BO_ 519 1;
BA_ "GenMsgSendType" BO_ 519 0;
BA_ "GenMsgCycleTime" BO_ 519 1000;
BA_ "VFrameFormat" BO_ 519 14;
BA_ "GenMsgILSupport" BO_ 523 1;
BA_ "GenMsgSendType" BO_ 523 0;
BA_ "GenMsgCycleTime" BO_ 523 1000;
BA_ "VFrameFormat" BO_ 523 14;
BA_ "GenMsgILSupport" BO_ 841 1;
BA_ "GenMsgSendType" BO_ 841 0;
BA_ "GenMsgCycleTime" BO_ 841 1000;
BA_ "VFrameFormat" BO_ 841 14;
BA_ "GenMsgILSupport" BO_ 448 1;
BA_ "GenMsgSendType" BO_ 448 0;
BA_ "GenMsgCycleTime" BO_ 448 200;
BA_ "VFrameFormat" BO_ 448 14;
BA_ "GenMsgILSupport" BO_ 526 1;
BA_ "GenMsgSendType" BO_ 526 0;
BA_ "GenMsgCycleTime" BO_ 526 1000;
BA_ "VFrameFormat" BO_ 526 14;
BA_ "GenMsgILSupport" BO_ 477 1;
BA_ "GenMsgSendType" BO_ 477 0;
BA_ "GenMsgCycleTime" BO_ 477 300;
BA_ "VFrameFormat" BO_ 477 14;
BA_ "GenMsgStartDelayTime" BO_ 900 4;
BA_ "GenMsgILSupport" BO_ 900 1;
BA_ "GenMsgSendType" BO_ 900 0;
BA_ "GenMsgCycleTime" BO_ 900 3000;
BA_ "VFrameFormat" BO_ 900 14;
BA_ "GenMsgStartDelayTime" BO_ 910 8;
BA_ "GenMsgILSupport" BO_ 910 1;
BA_ "GenMsgSendType" BO_ 910 0;
BA_ "GenMsgCycleTime" BO_ 910 1000;
BA_ "VFrameFormat" BO_ 910 14;
BA_ "GenMsgStartDelayTime" BO_ 903 12;
BA_ "GenMsgILSupport" BO_ 903 1;
BA_ "GenMsgSendType" BO_ 903 0;
BA_ "GenMsgCycleTime" BO_ 903 1000;
BA_ "VFrameFormat" BO_ 903 14;
BA_ "GenMsgStartDelayTime" BO_ 904 16;
BA_ "GenMsgILSupport" BO_ 904 1;
BA_ "GenMsgSendType" BO_ 904 0;
BA_ "GenMsgCycleTime" BO_ 904 1000;
BA_ "VFrameFormat" BO_ 904 14;
BA_ "GenMsgStartDelayTime" BO_ 911 20;
BA_ "GenMsgILSupport" BO_ 911 1;
BA_ "GenMsgSendType" BO_ 911 0;
BA_ "GenMsgCycleTime" BO_ 911 1000;
BA_ "VFrameFormat" BO_ 911 14;
BA_ "GenMsgStartDelayTime" BO_ 998 24;
BA_ "GenMsgILSupport" BO_ 998 1;
BA_ "GenMsgSendType" BO_ 998 0;
BA_ "GenMsgCycleTime" BO_ 998 3000;
BA_ "VFrameFormat" BO_ 998 14;
BA_ "GenMsgStartDelayTime" BO_ 1076 28;
BA_ "GenMsgILSupport" BO_ 1076 1;
BA_ "GenMsgSendType" BO_ 1076 0;
BA_ "GenMsgCycleTime" BO_ 1076 1000;
BA_ "VFrameFormat" BO_ 1076 14;
BA_ "GenMsgStartDelayTime" BO_ 1077 32;
BA_ "GenMsgILSupport" BO_ 1077 1;
BA_ "GenMsgSendType" BO_ 1077 0;
BA_ "GenMsgCycleTime" BO_ 1077 1000;
BA_ "VFrameFormat" BO_ 1077 14;
BA_ "GenMsgStartDelayTime" BO_ 1078 36;
BA_ "GenMsgILSupport" BO_ 1078 1;
BA_ "GenMsgSendType" BO_ 1078 0;
BA_ "GenMsgCycleTime" BO_ 1078 1000;
BA_ "VFrameFormat" BO_ 1078 14;
BA_ "GenMsgStartDelayTime" BO_ 1079 40;
BA_ "GenMsgILSupport" BO_ 1079 1;
BA_ "GenMsgSendType" BO_ 1079 0;
BA_ "GenMsgCycleTime" BO_ 1079 1000;
BA_ "VFrameFormat" BO_ 1079 14;
BA_ "GenMsgStartDelayTime" BO_ 794 44;
BA_ "GenMsgILSupport" BO_ 794 1;
BA_ "GenMsgSendType" BO_ 794 0;
BA_ "GenMsgCycleTime" BO_ 794 3000;
BA_ "VFrameFormat" BO_ 794 14;
BA_ "GenMsgStartDelayTime" BO_ 289 48;
BA_ "GenMsgILSupport" BO_ 289 1;
BA_ "GenMsgSendType" BO_ 289 0;
BA_ "GenMsgCycleTime" BO_ 289 100;
BA_ "VFrameFormat" BO_ 289 14;
BA_ "GenMsgStartDelayTime" BO_ 1418 52;
BA_ "GenMsgILSupport" BO_ 1418 1;
BA_ "GenMsgSendType" BO_ 1418 0;
BA_ "GenMsgCycleTime" BO_ 1418 1000;
BA_ "VFrameFormat" BO_ 1418 14;
BA_ "GenMsgStartDelayTime" BO_ 1309 56;
BA_ "GenMsgILSupport" BO_ 1309 1;
BA_ "GenMsgSendType" BO_ 1309 0;
BA_ "GenMsgCycleTime" BO_ 1309 1000;
BA_ "VFrameFormat" BO_ 1309 14;
BA_ "GenMsgStartDelayTime" BO_ 445 60;
BA_ "GenMsgILSupport" BO_ 445 1;
BA_ "GenMsgSendType" BO_ 445 0;
BA_ "GenMsgCycleTime" BO_ 445 200;
BA_ "VFrameFormat" BO_ 445 14;
BA_ "GenMsgStartDelayTime" BO_ 859 64;
BA_ "GenMsgILSupport" BO_ 859 1;
BA_ "GenMsgSendType" BO_ 859 0;
BA_ "GenMsgCycleTime" BO_ 859 20000;
BA_ "VFrameFormat" BO_ 859 14;
BA_ "GenMsgStartDelayTime" BO_ 969 68;
BA_ "GenMsgILSupport" BO_ 969 1;
BA_ "GenMsgSendType" BO_ 969 0;
BA_ "GenMsgCycleTime" BO_ 969 1000;
BA_ "VFrameFormat" BO_ 969 14;
BA_ "GenMsgStartDelayTime" BO_ 1168 72;
BA_ "GenMsgILSupport" BO_ 1168 1;
BA_ "GenMsgSendType" BO_ 1168 0;
BA_ "GenMsgCycleTime" BO_ 1168 1000;
BA_ "VFrameFormat" BO_ 1168 14;
BA_ "GenMsgStartDelayTime" BO_ 1311 76;
BA_ "GenMsgILSupport" BO_ 1311 1;
BA_ "GenMsgSendType" BO_ 1311 0;
BA_ "GenMsgCycleTime" BO_ 1311 1000;
BA_ "VFrameFormat" BO_ 1311 14;
BA_ "GenMsgStartDelayTime" BO_ 1322 80;
BA_ "GenMsgILSupport" BO_ 1322 1;
BA_ "GenMsgSendType" BO_ 1322 0;
BA_ "GenMsgCycleTime" BO_ 1322 10000;
BA_ "VFrameFormat" BO_ 1322 14;
BA_ "GenMsgStartDelayTime" BO_ 782 84;
BA_ "GenMsgILSupport" BO_ 782 1;
BA_ "GenMsgSendType" BO_ 782 0;
BA_ "GenMsgCycleTime" BO_ 782 1000;
BA_ "VFrameFormat" BO_ 782 14;
BA_ "GenMsgStartDelayTime" BO_ 1313 88;
BA_ "GenMsgILSupport" BO_ 1313 1;
BA_ "GenMsgSendType" BO_ 1313 0;
BA_ "GenMsgCycleTime" BO_ 1313 3000;
BA_ "VFrameFormat" BO_ 1313 14;
BA_ "GenMsgStartDelayTime" BO_ 332 92;
BA_ "GenMsgILSupport" BO_ 332 1;
BA_ "GenMsgSendType" BO_ 332 0;
BA_ "GenMsgCycleTime" BO_ 332 100;
BA_ "VFrameFormat" BO_ 332 14;
BA_ "GenMsgStartDelayTime" BO_ 682 96;
BA_ "GenMsgILSupport" BO_ 682 1;
BA_ "GenMsgSendType" BO_ 682 0;
BA_ "GenMsgCycleTime" BO_ 682 1000;
BA_ "VFrameFormat" BO_ 682 14;
BA_ "GenMsgStartDelayTime" BO_ 837 100;
BA_ "GenMsgILSupport" BO_ 837 1;
BA_ "GenMsgSendType" BO_ 837 0;
BA_ "GenMsgCycleTime" BO_ 837 1000;
BA_ "VFrameFormat" BO_ 837 14;
BA_ "GenMsgStartDelayTime" BO_ 838 104;
BA_ "GenMsgILSupport" BO_ 838 1;
BA_ "GenMsgSendType" BO_ 838 0;
BA_ "GenMsgCycleTime" BO_ 838 1000;
BA_ "VFrameFormat" BO_ 838 14;
BA_ "GenMsgStartDelayTime" BO_ 985 108;
BA_ "GenMsgILSupport" BO_ 985 1;
BA_ "GenMsgSendType" BO_ 985 0;
BA_ "GenMsgCycleTime" BO_ 985 1000;
BA_ "VFrameFormat" BO_ 985 14;
BA_ "GenMsgStartDelayTime" BO_ 996 112;
BA_ "GenMsgILSupport" BO_ 996 1;
BA_ "GenMsgSendType" BO_ 996 0;
BA_ "GenMsgCycleTime" BO_ 996 1000;
BA_ "VFrameFormat" BO_ 996 14;
BA_ "GenMsgStartDelayTime" BO_ 960 116;
BA_ "GenMsgILSupport" BO_ 960 1;
BA_ "GenMsgSendType" BO_ 960 0;
BA_ "GenMsgCycleTime" BO_ 960 1000;
BA_ "VFrameFormat" BO_ 960 14;
BA_ "GenMsgStartDelayTime" BO_ 492 120;
BA_ "GenMsgILSupport" BO_ 492 1;
BA_ "GenMsgSendType" BO_ 492 0;
BA_ "GenMsgCycleTime" BO_ 492 500;
BA_ "VFrameFormat" BO_ 492 14;
BA_ "GenMsgStartDelayTime" BO_ 858 124;
BA_ "GenMsgILSupport" BO_ 858 1;
BA_ "GenMsgSendType" BO_ 858 0;
BA_ "GenMsgCycleTime" BO_ 858 1000;
BA_ "VFrameFormat" BO_ 858 14;
BA_ "GenMsgStartDelayTime" BO_ 787 128;
BA_ "GenMsgILSupport" BO_ 787 1;
BA_ "VFrameFormat" BO_ 787 14;
BA_ "GenMsgStartDelayTime" BO_ 1301 132;
BA_ "GenMsgILSupport" BO_ 1301 1;
BA_ "GenMsgSendType" BO_ 1301 0;
BA_ "GenMsgCycleTime" BO_ 1301 1000;
BA_ "VFrameFormat" BO_ 1301 14;
BA_ "GenMsgStartDelayTime" BO_ 722 136;
BA_ "GenMsgILSupport" BO_ 722 1;
BA_ "GenMsgSendType" BO_ 722 0;
BA_ "GenMsgCycleTime" BO_ 722 1000;
BA_ "VFrameFormat" BO_ 722 14;
BA_ "GenMsgStartDelayTime" BO_ 498 140;
BA_ "GenMsgILSupport" BO_ 498 1;
BA_ "GenMsgSendType" BO_ 498 0;
BA_ "GenMsgCycleTime" BO_ 498 500;
BA_ "VFrameFormat" BO_ 498 14;
BA_ "GenMsgStartDelayTime" BO_ 724 144;
BA_ "GenMsgILSupport" BO_ 724 1;
BA_ "GenMsgSendType" BO_ 724 0;
BA_ "GenMsgCycleTime" BO_ 724 1000;
BA_ "VFrameFormat" BO_ 724 14;
BA_ "GenMsgStartDelayTime" BO_ 725 148;
BA_ "GenMsgILSupport" BO_ 725 1;
BA_ "GenMsgSendType" BO_ 725 0;
BA_ "GenMsgCycleTime" BO_ 725 1000;
BA_ "VFrameFormat" BO_ 725 14;
BA_ "GenMsgStartDelayTime" BO_ 726 152;
BA_ "GenMsgILSupport" BO_ 726 1;
BA_ "GenMsgSendType" BO_ 726 0;
BA_ "GenMsgCycleTime" BO_ 726 1000;
BA_ "VFrameFormat" BO_ 726 14;
BA_ "GenMsgStartDelayTime" BO_ 727 156;
BA_ "GenMsgILSupport" BO_ 727 1;
BA_ "GenMsgSendType" BO_ 727 0;
BA_ "GenMsgCycleTime" BO_ 727 1000;
BA_ "VFrameFormat" BO_ 727 14;
BA_ "GenMsgStartDelayTime" BO_ 735 160;
BA_ "GenMsgILSupport" BO_ 735 1;
BA_ "GenMsgSendType" BO_ 735 0;
BA_ "GenMsgCycleTime" BO_ 735 1000;
BA_ "VFrameFormat" BO_ 735 14;
BA_ "GenMsgStartDelayTime" BO_ 736 164;
BA_ "GenMsgILSupport" BO_ 736 1;
BA_ "GenMsgSendType" BO_ 736 0;
BA_ "GenMsgCycleTime" BO_ 736 1000;
BA_ "VFrameFormat" BO_ 736 14;
BA_ "GenMsgStartDelayTime" BO_ 737 168;
BA_ "GenMsgILSupport" BO_ 737 1;
BA_ "GenMsgSendType" BO_ 737 0;
BA_ "GenMsgCycleTime" BO_ 737 1000;
BA_ "VFrameFormat" BO_ 737 14;
BA_ "GenMsgStartDelayTime" BO_ 738 172;
BA_ "GenMsgILSupport" BO_ 738 1;
BA_ "GenMsgSendType" BO_ 738 0;
BA_ "GenMsgCycleTime" BO_ 738 1000;
BA_ "VFrameFormat" BO_ 738 14;
BA_ "GenMsgStartDelayTime" BO_ 751 176;
BA_ "GenMsgILSupport" BO_ 751 1;
BA_ "GenMsgSendType" BO_ 751 0;
BA_ "GenMsgCycleTime" BO_ 751 1000;
BA_ "VFrameFormat" BO_ 751 14;
BA_ "GenMsgStartDelayTime" BO_ 752 180;
BA_ "GenMsgILSupport" BO_ 752 1;
BA_ "GenMsgSendType" BO_ 752 0;
BA_ "GenMsgCycleTime" BO_ 752 1000;
BA_ "VFrameFormat" BO_ 752 14;
BA_ "GenMsgStartDelayTime" BO_ 754 184;
BA_ "GenMsgILSupport" BO_ 754 1;
BA_ "GenMsgSendType" BO_ 754 0;
BA_ "GenMsgCycleTime" BO_ 754 1000;
BA_ "VFrameFormat" BO_ 754 14;
BA_ "GenMsgStartDelayTime" BO_ 757 188;
BA_ "GenMsgILSupport" BO_ 757 1;
BA_ "GenMsgSendType" BO_ 757 0;
BA_ "GenMsgCycleTime" BO_ 757 1000;
BA_ "VFrameFormat" BO_ 757 14;
BA_ "GenMsgStartDelayTime" BO_ 389 192;
BA_ "GenMsgILSupport" BO_ 389 1;
BA_ "GenMsgSendType" BO_ 389 0;
BA_ "GenMsgCycleTime" BO_ 389 100;
BA_ "VFrameFormat" BO_ 389 14;
BA_ "GenMsgStartDelayTime" BO_ 758 196;
BA_ "GenMsgILSupport" BO_ 758 1;
BA_ "GenMsgSendType" BO_ 758 0;
BA_ "GenMsgCycleTime" BO_ 758 1000;
BA_ "VFrameFormat" BO_ 758 14;
BA_ "GenMsgStartDelayTime" BO_ 760 200;
BA_ "GenMsgILSupport" BO_ 760 1;
BA_ "GenMsgSendType" BO_ 760 0;
BA_ "GenMsgCycleTime" BO_ 760 1000;
BA_ "VFrameFormat" BO_ 760 14;
BA_ "GenMsgStartDelayTime" BO_ 762 204;
BA_ "GenMsgILSupport" BO_ 762 1;
BA_ "GenMsgSendType" BO_ 762 0;
BA_ "GenMsgCycleTime" BO_ 762 1000;
BA_ "VFrameFormat" BO_ 762 14;
BA_ "GenMsgStartDelayTime" BO_ 763 208;
BA_ "GenMsgILSupport" BO_ 763 1;
BA_ "GenMsgSendType" BO_ 763 0;
BA_ "GenMsgCycleTime" BO_ 763 1000;
BA_ "VFrameFormat" BO_ 763 14;
BA_ "GenMsgStartDelayTime" BO_ 826 212;
BA_ "GenMsgILSupport" BO_ 826 1;
BA_ "GenMsgSendType" BO_ 826 0;
BA_ "GenMsgCycleTime" BO_ 826 1000;
BA_ "VFrameFormat" BO_ 826 14;
BA_ "GenMsgStartDelayTime" BO_ 1086 216;
BA_ "GenMsgILSupport" BO_ 1086 1;
BA_ "GenMsgSendType" BO_ 1086 0;
BA_ "GenMsgCycleTime" BO_ 1086 1000;
BA_ "VFrameFormat" BO_ 1086 14;
BA_ "GenMsgStartDelayTime" BO_ 1548 220;
BA_ "GenMsgILSupport" BO_ 1548 1;
BA_ "GenMsgSendType" BO_ 1548 0;
BA_ "GenMsgCycleTime" BO_ 1548 1000;
BA_ "VFrameFormat" BO_ 1548 14;
BA_ "GenMsgStartDelayTime" BO_ 739 224;
BA_ "GenMsgILSupport" BO_ 739 1;
BA_ "GenMsgSendType" BO_ 739 0;
BA_ "GenMsgCycleTime" BO_ 739 1000;
BA_ "VFrameFormat" BO_ 739 14;
BA_ "GenMsgILSupport" BO_ 532 1;
BA_ "GenMsgSendType" BO_ 532 0;
BA_ "GenMsgCycleTime" BO_ 532 1000;
BA_ "VFrameFormat" BO_ 532 14;
BA_ "GenMsgILSupport" BO_ 366 1;
BA_ "GenMsgSendType" BO_ 366 0;
BA_ "GenMsgCycleTime" BO_ 366 100;
BA_ "VFrameFormat" BO_ 366 14;
BA_ "GenMsgILSupport" BO_ 997 1;
BA_ "GenMsgSendType" BO_ 997 0;
BA_ "GenMsgCycleTime" BO_ 997 1000;
BA_ "VFrameFormat" BO_ 997 14;
BA_ "GenMsgILSupport" BO_ 292 1;
BA_ "GenMsgSendType" BO_ 292 0;
BA_ "GenMsgCycleTime" BO_ 292 100;
BA_ "VFrameFormat" BO_ 292 14;
BA_ "GenMsgILSupport" BO_ 341 1;
BA_ "GenMsgSendType" BO_ 341 0;
BA_ "GenMsgCycleTime" BO_ 341 100;
BA_ "VFrameFormat" BO_ 341 14;
BA_ "GenMsgILSupport" BO_ 889 1;
BA_ "GenMsgSendType" BO_ 889 0;
BA_ "GenMsgCycleTime" BO_ 889 1000;
BA_ "VFrameFormat" BO_ 889 14;
BA_ "GenMsgILSupport" BO_ 907 1;
BA_ "GenMsgSendType" BO_ 907 0;
BA_ "GenMsgCycleTime" BO_ 907 1000;
BA_ "VFrameFormat" BO_ 907 14;
BA_ "GenMsgILSupport" BO_ 909 1;
BA_ "GenMsgSendType" BO_ 909 0;
BA_ "GenMsgCycleTime" BO_ 909 1000;
BA_ "VFrameFormat" BO_ 909 14;
BA_ "GenMsgILSupport" BO_ 500 1;
BA_ "GenMsgSendType" BO_ 500 0;
BA_ "GenMsgCycleTime" BO_ 500 500;
BA_ "VFrameFormat" BO_ 500 14;
BA_ "GenMsgILSupport" BO_ 463 1;
BA_ "GenMsgSendType" BO_ 463 0;
BA_ "GenMsgCycleTime" BO_ 463 300;
BA_ "VFrameFormat" BO_ 463 14;
BA_ "GenMsgILSupport" BO_ 1569 1;
BA_ "GenMsgSendType" BO_ 1569 0;
BA_ "GenMsgCycleTime" BO_ 1569 1000;
BA_ "VFrameFormat" BO_ 1569 14;
BA_ "GenSigSendType" SG_ 945 SCSACCEL 3;
BA_ "GenSigStartValue" SG_ 945 SCSACCEL 3;
BA_ "GenSigSendType" SG_ 945 SCSBZR 3;
BA_ "GenSigStartValue" SG_ 945 SCSBZR 3;
BA_ "GenSigSendType" SG_ 945 CDT_SCN1 3;
BA_ "GenSigSendType" SG_ 945 DBKLAB 3;
BA_ "GenSigStartValue" SG_ 945 DBKLAB 2;
BA_ "GenSigSendType" SG_ 945 PBKLAB 3;
BA_ "GenSigStartValue" SG_ 945 PBKLAB 2;
BA_ "GenSigSendType" SG_ 929 O_STG_F 3;
BA_ "GenSigSendType" SG_ 929 AC_CDSP 3;
BA_ "GenSigSendType" SG_ 897 R_ACCALL 3;
BA_ "GenSigSendType" SG_ 897 R_AC_WNG 3;
BA_ "GenSigSendType" SG_ 897 R_SW_CON 3;
BA_ "GenSigSendType" SG_ 897 I_RA_AUT 3;
BA_ "GenSigSendType" SG_ 897 I_RA_AC 3;
BA_ "GenSigSendType" SG_ 897 I_RA_LO 3;
BA_ "GenSigSendType" SG_ 897 I_RA_HI 3;
BA_ "GenSigSendType" SG_ 897 I_AUTO_D 3;
BA_ "GenSigSendType" SG_ 897 I_AUTO_P 3;
BA_ "GenSigSendType" SG_ 897 I_DEF 3;
BA_ "GenSigSendType" SG_ 897 I_RRDEF 3;
BA_ "GenSigSendType" SG_ 897 I_RFAUT 3;
BA_ "GenSigSendType" SG_ 897 I_REC 3;
BA_ "GenSigSendType" SG_ 897 I_FRS 3;
BA_ "GenSigSendType" SG_ 897 I_AC 3;
BA_ "GenSigSendType" SG_ 897 I_MHTR 3;
BA_ "GenSigSendType" SG_ 897 I_WIPD 3;
BA_ "GenSigSendType" SG_ 897 I_DUSY 3;
BA_ "GenSigSendType" SG_ 897 I_SWNG 3;
BA_ "GenSigSendType" SG_ 897 I_BLW_F 3;
BA_ "GenSigSendType" SG_ 897 I_OAUT_D 3;
BA_ "GenSigSendType" SG_ 897 I_OLET_D 3;
BA_ "GenSigSendType" SG_ 897 I_OAUT_P 3;
BA_ "GenSigSendType" SG_ 897 I_OLET_P 3;
BA_ "GenSigSendType" SG_ 897 ST_BMN_F 3;
BA_ "GenSigSendType" SG_ 897 I_CONCEN 3;
BA_ "GenSigSendType" SG_ 897 I_NANOE 3;
BA_ "GenSigSendType" SG_ 897 I_CONCIE 3;
BA_ "GenSigSendType" SG_ 897 I_BLWCUS 3;
BA_ "GenSigSendType" SG_ 897 I_AIRPR 3;
BA_ "GenSigSendType" SG_ 897 I_PLSM 3;
BA_ "GenSigSendType" SG_ 897 I_KAFUN 3;
BA_ "GenSigSendType" SG_ 897 R_ONSCRN 3;
BA_ "GenSigSendType" SG_ 897 I_OLET_I 3;
BA_ "GenSigSendType" SG_ 897 I_PLSYNC 3;
BA_ "GenSigStartValue" SG_ 897 I_PLSYNC 7;
BA_ "GenSigSendType" SG_ 897 I_RFAUTT 3;
BA_ "GenSigSendType" SG_ 897 R_SFLOWS 3;
BA_ "GenSigSendType" SG_ 897 I_ACAUTO 3;
BA_ "GenSigSendType" SG_ 897 R_ECODSP 3;
BA_ "GenSigSendType" SG_ 897 SL_ACDSP 3;
BA_ "GenSigSendType" SG_ 897 SL_DUSY 3;
BA_ "GenSigSendType" SG_ 897 SL_DFRAD 3;
BA_ "GenSigSendType" SG_ 897 SL_CIF 3;
BA_ "GenSigSendType" SG_ 897 SL_BLW_F 3;
BA_ "GenSigSendType" SG_ 897 SL_SRLVL 3;
BA_ "GenSigSendType" SG_ 897 SL_RR_IH 3;
BA_ "GenSigSendType" SG_ 897 SL_RAUTO 3;
BA_ "GenSigSendType" SG_ 897 SL_BLW_R 3;
BA_ "GenSigSendType" SG_ 897 SL_DST 3;
BA_ "GenSigSendType" SG_ 897 SL_WIPD 3;
BA_ "GenSigSendType" SG_ 897 SL_MRHT 3;
BA_ "GenSigSendType" SG_ 897 SL_AIRP 3;
BA_ "GenSigSendType" SG_ 897 SL_PFRAD 3;
BA_ "GenSigSendType" SG_ 897 SL_PLSM 3;
BA_ "GenSigSendType" SG_ 897 SL_KAFUN 3;
BA_ "GenSigSendType" SG_ 897 SL_SWNG 3;
BA_ "GenSigSendType" SG_ 897 ST_CN_OK 3;
BA_ "GenSigSendType" SG_ 897 SL_FSVTP 3;
BA_ "GenSigSendType" SG_ 897 SL_FSTYP 3;
BA_ "GenSigSendType" SG_ 897 SL_NANOE 3;
BA_ "GenSigSendType" SG_ 897 SL_RSEAT 3;
BA_ "GenSigSendType" SG_ 897 SL_SFLOW 3;
BA_ "GenSigSendType" SG_ 897 SL_ACST 3;
BA_ "GenSigSendType" SG_ 897 SL_AC_AM 3;
BA_ "GenSigSendType" SG_ 897 SL_RBLW 3;
BA_ "GenSigSendType" SG_ 897 SL_ROFF 3;
BA_ "GenSigSendType" SG_ 897 SL_BLCUS 3;
BA_ "GenSigSendType" SG_ 897 SL_ACECO 3;
BA_ "GenSigSendType" SG_ 897 SL_RFSW 3;
BA_ "GenSigSendType" SG_ 897 SL_CONCI 3;
BA_ "GenSigSendType" SG_ 897 SL_NECK 3;
BA_ "GenSigSendType" SG_ 897 SL_RACIH 3;
BA_ "GenSigSendType" SG_ 897 SL_ZOSY 3;
BA_ "GenSigSendType" SG_ 897 SL_STHAT 3;
BA_ "GenSigSendType" SG_ 897 SL_3RD_S 3;
BA_ "GenSigSendType" SG_ 897 SL_RSBLW 3;
BA_ "GenSigSendType" SG_ 897 SL_STR_H 3;
BA_ "GenSigSendType" SG_ 897 SL_NAVI 3;
BA_ "GenSigSendType" SG_ 897 I_AUT_RR 3;
BA_ "GenSigSendType" SG_ 897 I_AUT_RL 3;
BA_ "GenSigSendType" SG_ 897 I_CNT_IH 3;
BA_ "GenSigSendType" SG_ 897 I_RAUTO 3;
BA_ "GenSigSendType" SG_ 897 ST_BMN_R 3;
BA_ "GenSigSendType" SG_ 897 I_RBLCUS 3;
BA_ "GenSigSendType" SG_ 897 I_OAUTRL 3;
BA_ "GenSigSendType" SG_ 897 I_OAUTRR 3;
BA_ "GenSigSendType" SG_ 897 I_BLW_R 3;
BA_ "GenSigSendType" SG_ 897 R_RONSCR 3;
BA_ "GenSigSendType" SG_ 897 I_OLT_RR 3;
BA_ "GenSigSendType" SG_ 897 I_RACON 3;
BA_ "GenSigSendType" SG_ 897 I_OLT_RL 3;
BA_ "GenSigSendType" SG_ 897 B_DCMOD1 3;
BA_ "GenSigSendType" SG_ 897 B_DCMOD2 3;
BA_ "GenSigSendType" SG_ 897 B_DCMOD3 3;
BA_ "GenSigSendType" SG_ 897 I_TMP_RR 3;
BA_ "GenSigStartValue" SG_ 897 I_TMP_RR 56;
BA_ "GenSigSendType" SG_ 897 I_TMP_RL 3;
BA_ "GenSigStartValue" SG_ 897 I_TMP_RL 56;
BA_ "GenSigSendType" SG_ 897 I_BCOLRL 3;
BA_ "GenSigSendType" SG_ 897 I_BCOLRR 3;
BA_ "GenSigSendType" SG_ 897 I_BCOLPA 3;
BA_ "GenSigSendType" SG_ 897 I_BCOLDR 3;
BA_ "GenSigSendType" SG_ 897 M_OLT_PA 3;
BA_ "GenSigSendType" SG_ 897 M_OLT_DR 3;
BA_ "GenSigSendType" SG_ 897 M_OLT_RL 3;
BA_ "GenSigSendType" SG_ 897 M_OLT_RR 3;
BA_ "GenSigSendType" SG_ 897 RL_SBL 3;
BA_ "GenSigSendType" SG_ 897 RL_SHL 3;
BA_ "GenSigSendType" SG_ 897 RR_SBL 3;
BA_ "GenSigSendType" SG_ 897 RR_SHL 3;
BA_ "GenSigSendType" SG_ 897 I_STHLVL 3;
BA_ "GenSigSendType" SG_ 897 I_SAUTRL 3;
BA_ "GenSigSendType" SG_ 897 I_SAUTRR 3;
BA_ "GenSigSendType" SG_ 897 R_DSP_SH 3;
BA_ "GenSigSendType" SG_ 897 I_SAUT_P 3;
BA_ "GenSigSendType" SG_ 897 I_SAUT_D 3;
BA_ "GenSigSendType" SG_ 897 I_STHAUT 3;
BA_ "GenSigSendType" SG_ 897 PF_SBL 3;
BA_ "GenSigSendType" SG_ 897 PF_SHL 3;
BA_ "GenSigSendType" SG_ 897 DF_SBL 3;
BA_ "GenSigSendType" SG_ 897 DF_SHL 3;
BA_ "GenSigSendType" SG_ 897 DF_NHL 3;
BA_ "GenSigSendType" SG_ 897 PF_NHL 3;
BA_ "GenSigSendType" SG_ 897 I_NH_LIM 3;
BA_ "GenSigSendType" SG_ 897 I_NAUT_D 3;
BA_ "GenSigSendType" SG_ 897 I_NAUT_P 3;
BA_ "GenSigSendType" SG_ 898 I_TMP_D 3;
BA_ "GenSigStartValue" SG_ 898 I_TMP_D 56;
BA_ "GenSigSendType" SG_ 898 I_TMP_P 3;
BA_ "GenSigStartValue" SG_ 898 I_TMP_P 56;
BA_ "GenSigSendType" SG_ 898 ACN_ENE 3;
BA_ "GenSigSendType" SG_ 898 I_ACECO 3;
BA_ "GenSigSendType" SG_ 898 I_DSPR 3;
BA_ "GenSigSendType" SG_ 944 RDEF 3;
BA_ "GenSigSendType" SG_ 944 MHTR 3;
BA_ "GenSigSendType" SG_ 944 S_CLMT 3;
BA_ "GenSigSendType" SG_ 944 CLE_RECF 3;
BA_ "GenSigSendType" SG_ 944 EVA_FBP 3;
BA_ "GenSigStartValue" SG_ 944 EVA_FBP 4;
BA_ "GenSigSendType" SG_ 944 AC_OUTT 3;
BA_ "GenSigStartValue" SG_ 944 AC_OUTT 2;
BA_ "GenSigSendType" SG_ 944 ES_RHW 3;
BA_ "GenSigSendType" SG_ 944 I_RRSEAT 3;
BA_ "GenSigSendType" SG_ 944 AC_MODE 3;
BA_ "GenSigSendType" SG_ 944 SL_HP 3;
BA_ "GenSigSendType" SG_ 944 TAO_FLG 3;
BA_ "GenSigSendType" SG_ 944 ACL_WRN 3;
BA_ "GenSigSendType" SG_ 1031 I_BLWF_P 3;
BA_ "GenSigSendType" SG_ 1032 PRACAC_P 3;
BA_ "GenSigSendType" SG_ 852 I_EXT 3;
BA_ "GenSigSendType" SG_ 852 PM_REN 3;
BA_ "GenSigSendType" SG_ 852 PM_ST 3;
BA_ "GenSigStartValue" SG_ 852 PM_ST 2;
BA_ "GenSigSendType" SG_ 852 I_PM 3;
BA_ "GenSigSendType" SG_ 852 SL_PM 3;
BA_ "GenSigSendType" SG_ 852 I_FRC2 3;
BA_ "GenSigSendType" SG_ 852 I_FRC1 3;
BA_ "GenSigSendType" SG_ 852 I_RFRS 3;
BA_ "GenSigSendType" SG_ 852 I_WFRS 3;
BA_ "GenSigSendType" SG_ 852 I_FRIS 3;
BA_ "GenSigSendType" SG_ 852 SL_FR 3;
BA_ "GenSigSendType" SG_ 852 ST_ACAGT 3;
BA_ "GenSigStartValue" SG_ 852 ST_ACAGT 6;
BA_ "GenSigSendType" SG_ 852 I_FRST 3;
BA_ "GenSigSendType" SG_ 852 I_RFRC 3;
BA_ "GenSigSendType" SG_ 852 I_WFRC 3;
BA_ "GenSigSendType" SG_ 852 SL_TCS 3;
BA_ "GenSigSendType" SG_ 852 SL_EXT 3;
BA_ "GenSigSendType" SG_ 852 SL_ACAGT 3;
BA_ "GenSigSendType" SG_ 852 ST_EMEN 3;
BA_ "GenSigStartValue" SG_ 852 ST_EMEN 1;
BA_ "GenSigSendType" SG_ 852 ST_AWKEN 3;
BA_ "GenSigStartValue" SG_ 852 ST_AWKEN 1;
BA_ "GenSigSendType" SG_ 852 SL_RSTYP 3;
BA_ "GenSigSendType" SG_ 852 SL_SYNC 3;
BA_ "GenSigSendType" SG_ 852 TCS_ST 3;
BA_ "GenSigSendType" SG_ 852 R_RFPHBT 3;
BA_ "GenSigSendType" SG_ 852 SL_RSVTP 3;
BA_ "GenSigSendType" SG_ 852 FG_CH1_L 3;
BA_ "GenSigSendType" SG_ 852 FG_CH1_D 3;
BA_ "GenSigSendType" SG_ 852 FG_CH1_T 3;
BA_ "GenSigSendType" SG_ 852 FG_CH2_L 3;
BA_ "GenSigSendType" SG_ 852 FG_CH2_D 3;
BA_ "GenSigSendType" SG_ 852 FG_CH2_T 3;
BA_ "GenSigSendType" SG_ 852 FG_CH3_L 3;
BA_ "GenSigSendType" SG_ 852 FG_CH3_D 3;
BA_ "GenSigSendType" SG_ 852 FG_CH3_T 3;
BA_ "GenSigSendType" SG_ 852 FG_UV_E 3;
BA_ "GenSigSendType" SG_ 852 FG_OV_E 3;
BA_ "GenSigSendType" SG_ 852 FG_MOT_E 3;
BA_ "GenSigSendType" SG_ 852 FG_FAN_E 3;
BA_ "GenSigSendType" SG_ 852 FG_EMP 3;
BA_ "GenSigSendType" SG_ 852 FG_CHA_E 3;
BA_ "GenSigSendType" SG_ 852 SL_FGST 3;
BA_ "GenSigSendType" SG_ 852 I_FG_PW 3;
BA_ "GenSigSendType" SG_ 852 I_FG_LVL 3;
BA_ "GenSigSendType" SG_ 852 I_FG_CH 3;
BA_ "GenSigSendType" SG_ 1286 R_SHHTFL 3;
BA_ "GenSigSendType" SG_ 1286 R_SHHTFR 3;
BA_ "GenSigSendType" SG_ 1286 RSVFLDU 3;
BA_ "GenSigSendType" SG_ 1286 RSVFRDU 3;
BA_ "GenSigSendType" SG_ 1286 R_SHHTRL 3;
BA_ "GenSigSendType" SG_ 1286 R_SHHTRR 3;
BA_ "GenSigSendType" SG_ 1286 RSVRLDU 3;
BA_ "GenSigSendType" SG_ 1286 RSVRRDU 3;
BA_ "GenSigSendType" SG_ 1286 R_RDHRR 3;
BA_ "GenSigSendType" SG_ 1286 R_RDHRL 3;
BA_ "GenSigSendType" SG_ 1286 R_RDHFP 3;
BA_ "GenSigSendType" SG_ 1286 R_RDHFD 3;
BA_ "GenSigSendType" SG_ 382 RCPSYS 3;
BA_ "GenSigSendType" SG_ 519 VCDSP_2 3;
BA_ "GenSigSendType" SG_ 519 PCDSP_2 3;
BA_ "GenSigSendType" SG_ 519 GCDSP_2 3;
BA_ "GenSigSendType" SG_ 519 TRNEXIST 3;
BA_ "GenSigSendType" SG_ 519 TRNACT 3;
BA_ "GenSigSendType" SG_ 519 TRNCEO 3;
BA_ "GenSigSendType" SG_ 519 TRNED 3;
BA_ "GenSigSendType" SG_ 519 TRNEPR 3;
BA_ "GenSigSendType" SG_ 519 TRNPEPL 3;
BA_ "GenSigSendType" SG_ 519 TRNJ 3;
BA_ "GenSigSendType" SG_ 519 TRNCS 3;
BA_ "GenSigSendType" SG_ 519 TRNCN 3;
BA_ "GenSigSendType" SG_ 519 TRNCI 3;
BA_ "GenSigSendType" SG_ 519 TRNPB 3;
BA_ "GenSigSendType" SG_ 519 TRNGJ 3;
BA_ "GenSigSendType" SG_ 519 TRNME 3;
BA_ "GenSigSendType" SG_ 519 TRNMI 3;
BA_ "GenSigSendType" SG_ 519 TRNDP 3;
BA_ "GenSigSendType" SG_ 519 TRNMET1 3;
BA_ "GenSigSendType" SG_ 519 TRNMET2 3;
BA_ "GenSigSendType" SG_ 519 TRNJP 3;
BA_ "GenSigSendType" SG_ 519 TRNVUR 3;
BA_ "GenSigSendType" SG_ 519 TRNJPE 3;
BA_ "GenSigSendType" SG_ 519 TRNMMDIS 3;
BA_ "GenSigSendType" SG_ 519 TRNBUT 3;
BA_ "GenSigSendType" SG_ 519 TRNVUEX 3;
BA_ "GenSigSendType" SG_ 519 TRNAS 3;
BA_ "GenSigSendType" SG_ 519 TRNCI1 3;
BA_ "GenSigSendType" SG_ 519 TRNFE 3;
BA_ "GenSigSendType" SG_ 519 TRNSEI 3;
BA_ "GenSigSendType" SG_ 519 TRNPC1 3;
BA_ "GenSigSendType" SG_ 519 TRNPC2 3;
BA_ "GenSigSendType" SG_ 519 TRNPC3 3;
BA_ "GenSigSendType" SG_ 519 TRNPC4 3;
BA_ "GenSigSendType" SG_ 519 TRNPC5 3;
BA_ "GenSigSendType" SG_ 519 TRNPC6 3;
BA_ "GenSigSendType" SG_ 519 TRNPC7 3;
BA_ "GenSigSendType" SG_ 519 TRNPC8 3;
BA_ "GenSigSendType" SG_ 519 TRNSE1 3;
BA_ "GenSigSendType" SG_ 519 TRNSE2 3;
BA_ "GenSigSendType" SG_ 519 TRNSE3 3;
BA_ "GenSigSendType" SG_ 519 TRNSE4 3;
BA_ "GenSigSendType" SG_ 519 TRNSE5 3;
BA_ "GenSigSendType" SG_ 519 TRNSE6 3;
BA_ "GenSigSendType" SG_ 519 TRNSE7 3;
BA_ "GenSigSendType" SG_ 519 TRNSE8 3;
BA_ "GenSigSendType" SG_ 519 TRNISR 3;
BA_ "GenSigSendType" SG_ 519 TRNESR 3;
BA_ "GenSigSendType" SG_ 519 TRNHDR 3;
BA_ "GenSigSendType" SG_ 519 TRNMR1 3;
BA_ "GenSigSendType" SG_ 519 TRNMR2 3;
BA_ "GenSigSendType" SG_ 523 AMCONPVM 3;
BA_ "GenSigSendType" SG_ 523 DRADCABN 3;
BA_ "GenSigSendType" SG_ 523 DRADCTMP 3;
BA_ "GenSigSendType" SG_ 841 ETHWU_12 3;
BA_ "GenSigSendType" SG_ 448 APPMD2 3;
BA_ "GenSigSendType" SG_ 526 DIS_ALR2 3;
BA_ "GenSigSendType" SG_ 526 DISSUIEX 3;
BA_ "GenSigSendType" SG_ 526 DISSUIST 3;
BA_ "GenSigSendType" SG_ 526 SW_ALRT2 3;
BA_ "GenSigSendType" SG_ 526 PLANTREQ 3;
BA_ "GenSigSendType" SG_ 526 ADOFFM1 3;
BA_ "GenSigSendType" SG_ 526 ADOFFM2 3;
BA_ "GenSigSendType" SG_ 526 ADOFFMET 3;
BA_ "GenSigSendType" SG_ 526 SCBOICN 3;
BA_ "GenSigSendType" SG_ 526 RCDOICN 3;
BA_ "GenSigSendType" SG_ 526 RCTAOICN 3;
BA_ "GenSigSendType" SG_ 526 SEAOICN 3;
BA_ "GenSigSendType" SG_ 526 FCTAOICN 3;
BA_ "GenSigSendType" SG_ 526 SASOICN 3;
BA_ "GenSigSendType" SG_ 526 EDSSOICN 3;
BA_ "GenSigSendType" SG_ 526 ADISTATE 3;
BA_ "GenSigSendType" SG_ 526 SEAADIM 3;
BA_ "GenSigSendType" SG_ 526 PMARADIM 3;
BA_ "GenSigSendType" SG_ 526 RCTAADIM 3;
BA_ "GenSigSendType" SG_ 526 BSMADIM 3;
BA_ "GenSigSendType" SG_ 526 ADIEXIST 3;
BA_ "GenSigSendType" SG_ 526 DMCINDI 3;
BA_ "GenSigSendType" SG_ 526 DMCDISP 3;
BA_ "GenSigSendType" SG_ 526 DMCBZRQ 3;
BA_ "GenSigSendType" SG_ 526 ACCAVTYR 3;
BA_ "GenSigSendType" SG_ 526 ACCAVDTR 3;
BA_ "GenSigSendType" SG_ 526 ACCAVS1R 3;
BA_ "GenSigSendType" SG_ 526 ACCAVS2R 3;
BA_ "GenSigSendType" SG_ 526 ACCAVLPR 3;
BA_ "GenSigSendType" SG_ 526 ACCAVTYL 3;
BA_ "GenSigSendType" SG_ 526 ACCAVS2L 3;
BA_ "GenSigSendType" SG_ 526 ACCAVS1L 3;
BA_ "GenSigSendType" SG_ 526 ACCAVDTL 3;
BA_ "GenSigSendType" SG_ 526 ACCAVLPL 3;
BA_ "GenSigSendType" SG_ 526 ACCPPVEX 3;
BA_ "GenSigSendType" SG_ 526 ACCPPVDT 3;
BA_ "GenSigSendType" SG_ 526 ACCPPVS1 3;
BA_ "GenSigSendType" SG_ 526 ACCPVTY 3;
BA_ "GenSigSendType" SG_ 526 ACCPVDST 3;
BA_ "GenSigSendType" SG_ 526 ACCPVST1 3;
BA_ "GenSigSendType" SG_ 526 ACCPVST2 3;
BA_ "GenSigSendType" SG_ 526 ACCPVST3 3;
BA_ "GenSigSendType" SG_ 526 CACCFR1 3;
BA_ "GenSigSendType" SG_ 526 ERMPLRST 3;
BA_ "GenSigSendType" SG_ 526 AH_SRI_C 3;
BA_ "GenSigSendType" SG_ 526 AH_IND_C 3;
BA_ "GenSigSendType" SG_ 526 AH_WTR_C 3;
BA_ "GenSigSendType" SG_ 526 BSMOICN 3;
BA_ "GenSigSendType" SG_ 477 ARS_METD 3;
BA_ "GenSigSendType" SG_ 900 RDC 3;
BA_ "GenSigStartValue" SG_ 900 RDC 15;
BA_ "GenSigSendType" SG_ 900 CONFID01 3;
BA_ "GenSigSendType" SG_ 900 CONF 3;
BA_ "GenSigSendType" SG_ 900 LYT 3;
BA_ "GenSigStartValue" SG_ 900 LYT 15;
BA_ "GenSigSendType" SG_ 900 TNL_5H_S 3;
BA_ "GenSigSendType" SG_ 900 TNL_1T_S 3;
BA_ "GenSigSendType" SG_ 900 DRVW 3;
BA_ "GenSigSendType" SG_ 900 MWMP 3;
BA_ "GenSigSendType" SG_ 900 GRAD 3;
BA_ "GenSigSendType" SG_ 900 TNL_5T_S 3;
BA_ "GenSigSendType" SG_ 900 BRANCH 3;
BA_ "GenSigSendType" SG_ 900 TOLLGATE 3;
BA_ "GenSigSendType" SG_ 900 TUNL 3;
BA_ "GenSigSendType" SG_ 900 LEAVEOUT 3;
BA_ "GenSigSendType" SG_ 900 MRGLANE 3;
BA_ "GenSigSendType" SG_ 900 LVLANE 3;
BA_ "GenSigSendType" SG_ 910 R_AC_DSP 3;
BA_ "GenSigSendType" SG_ 910 AVN04VLD 3;
BA_ "GenSigSendType" SG_ 910 S_ACECO 3;
BA_ "GenSigSendType" SG_ 910 S_BLW_F 3;
BA_ "GenSigSendType" SG_ 910 S_RA_AUT 3;
BA_ "GenSigSendType" SG_ 910 S_RA_OFF 3;
BA_ "GenSigSendType" SG_ 910 S_RA_MNL 3;
BA_ "GenSigSendType" SG_ 910 R_PN_TYP 3;
BA_ "GenSigSendType" SG_ 910 R_CONCIE 3;
BA_ "GenSigSendType" SG_ 910 S_CONCIE 3;
BA_ "GenSigSendType" SG_ 910 R_S_FLOW 3;
BA_ "GenSigSendType" SG_ 910 R_RFAT 3;
BA_ "GenSigSendType" SG_ 910 S_AUTO_D 3;
BA_ "GenSigSendType" SG_ 910 S_AUTO_P 3;
BA_ "GenSigSendType" SG_ 910 S_DEF 3;
BA_ "GenSigSendType" SG_ 910 S_RRDEF 3;
BA_ "GenSigSendType" SG_ 910 S_INL 3;
BA_ "GenSigSendType" SG_ 910 S_OFF_F 3;
BA_ "GenSigSendType" SG_ 910 S_SAFS 3;
BA_ "GenSigSendType" SG_ 910 S_AC 3;
BA_ "GenSigSendType" SG_ 910 S_MHTR 3;
BA_ "GenSigSendType" SG_ 910 S_WIPD 3;
BA_ "GenSigSendType" SG_ 910 S_DUSY 3;
BA_ "GenSigSendType" SG_ 910 S_SWNG 3;
BA_ "GenSigSendType" SG_ 910 S_MODE_D 3;
BA_ "GenSigSendType" SG_ 910 S_MODE_P 3;
BA_ "GenSigSendType" SG_ 910 S_BUP_F 3;
BA_ "GenSigSendType" SG_ 910 S_BDN_F 3;
BA_ "GenSigSendType" SG_ 910 S_NANOE 3;
BA_ "GenSigSendType" SG_ 910 S_OLET_D 3;
BA_ "GenSigSendType" SG_ 910 S_DSPR 3;
BA_ "GenSigSendType" SG_ 910 S_OLET_P 3;
BA_ "GenSigSendType" SG_ 910 S_TUP_D 3;
BA_ "GenSigSendType" SG_ 910 S_TDN_D 3;
BA_ "GenSigSendType" SG_ 910 S_TUP_P 3;
BA_ "GenSigSendType" SG_ 910 S_TDN_P 3;
BA_ "GenSigSendType" SG_ 910 S_PLSM 3;
BA_ "GenSigSendType" SG_ 910 S_KAFUN 3;
BA_ "GenSigSendType" SG_ 910 S_AIRPR 3;
BA_ "GenSigSendType" SG_ 910 S_O2 3;
BA_ "GenSigSendType" SG_ 910 S_FRS 3;
BA_ "GenSigSendType" SG_ 910 S_REC 3;
BA_ "GenSigSendType" SG_ 910 S_HUM 3;
BA_ "GenSigSendType" SG_ 910 S_CONCEN 3;
BA_ "GenSigSendType" SG_ 910 S_IN_RTN 3;
BA_ "GenSigSendType" SG_ 910 S_INLVL 3;
BA_ "GenSigSendType" SG_ 910 S_BLW7_F 3;
BA_ "GenSigSendType" SG_ 910 S_BLW6_F 3;
BA_ "GenSigSendType" SG_ 910 S_BLW5_F 3;
BA_ "GenSigSendType" SG_ 910 S_BLW4_F 3;
BA_ "GenSigSendType" SG_ 910 S_BLW3_F 3;
BA_ "GenSigSendType" SG_ 910 S_BLW2_F 3;
BA_ "GenSigSendType" SG_ 910 S_BLW1_F 3;
BA_ "GenSigSendType" SG_ 910 ST_NAVAC 3;
BA_ "GenSigSendType" SG_ 903 S_AUT_RR 3;
BA_ "GenSigSendType" SG_ 903 S_AUT_RL 3;
BA_ "GenSigSendType" SG_ 903 S_BUP_R 3;
BA_ "GenSigSendType" SG_ 903 S_BDN_R 3;
BA_ "GenSigSendType" SG_ 903 S_TUP_RR 3;
BA_ "GenSigSendType" SG_ 903 S_TDN_RR 3;
BA_ "GenSigSendType" SG_ 903 S_TUP_RL 3;
BA_ "GenSigSendType" SG_ 903 S_TDN_RL 3;
BA_ "GenSigSendType" SG_ 903 ST_FRDSP 3;
BA_ "GenSigSendType" SG_ 903 S_OLT_RR 3;
BA_ "GenSigSendType" SG_ 903 S_OLT_RL 3;
BA_ "GenSigSendType" SG_ 903 S_MOD_RR 3;
BA_ "GenSigSendType" SG_ 903 S_MOD_RL 3;
BA_ "GenSigSendType" SG_ 903 S_OFF_R 3;
BA_ "GenSigSendType" SG_ 903 S_CNT_IH 3;
BA_ "GenSigSendType" SG_ 903 S_RRSEAT 3;
BA_ "GenSigSendType" SG_ 903 S_REONOF 3;
BA_ "GenSigSendType" SG_ 903 S_SYNC 3;
BA_ "GenSigSendType" SG_ 903 S_RAUTO 3;
BA_ "GenSigSendType" SG_ 903 S_BLW7_R 3;
BA_ "GenSigSendType" SG_ 903 S_BLW6_R 3;
BA_ "GenSigSendType" SG_ 903 S_BLW5_R 3;
BA_ "GenSigSendType" SG_ 903 S_BLW4_R 3;
BA_ "GenSigSendType" SG_ 903 S_BLW3_R 3;
BA_ "GenSigSendType" SG_ 903 S_BLW2_R 3;
BA_ "GenSigSendType" SG_ 903 S_BLW1_R 3;
BA_ "GenSigSendType" SG_ 903 S_TPMDRR 3;
BA_ "GenSigSendType" SG_ 903 S_ICDLRR 3;
BA_ "GenSigSendType" SG_ 903 S_TPCDRR 3;
BA_ "GenSigStartValue" SG_ 903 S_TPCDRR 63;
BA_ "GenSigSendType" SG_ 903 S_TPMDRL 3;
BA_ "GenSigSendType" SG_ 903 S_ICDLRL 3;
BA_ "GenSigSendType" SG_ 903 S_TPCDRL 3;
BA_ "GenSigStartValue" SG_ 903 S_TPCDRL 63;
BA_ "GenSigSendType" SG_ 903 S_TPMD_D 3;
BA_ "GenSigSendType" SG_ 903 S_ICDL_D 3;
BA_ "GenSigSendType" SG_ 903 S_TPCD_D 3;
BA_ "GenSigStartValue" SG_ 903 S_TPCD_D 63;
BA_ "GenSigSendType" SG_ 903 S_TPMD_P 3;
BA_ "GenSigSendType" SG_ 903 S_ICDL_P 3;
BA_ "GenSigSendType" SG_ 903 S_TPCD_P 3;
BA_ "GenSigStartValue" SG_ 903 S_TPCD_P 63;
BA_ "GenSigSendType" SG_ 904 S_DF_SH 3;
BA_ "GenSigSendType" SG_ 904 S_PF_SH 3;
BA_ "GenSigSendType" SG_ 904 S_RR_SH 3;
BA_ "GenSigSendType" SG_ 904 S_RL_SH 3;
BA_ "GenSigSendType" SG_ 904 S_DF_SB 3;
BA_ "GenSigSendType" SG_ 904 S_PF_SB 3;
BA_ "GenSigSendType" SG_ 904 S_RR_SB 3;
BA_ "GenSigSendType" SG_ 904 S_RL_SB 3;
BA_ "GenSigSendType" SG_ 904 S_DF_SA 3;
BA_ "GenSigSendType" SG_ 904 S_PF_SA 3;
BA_ "GenSigSendType" SG_ 904 S_RR_SA 3;
BA_ "GenSigSendType" SG_ 904 S_RL_SA 3;
BA_ "GenSigSendType" SG_ 904 S_NUP_D 3;
BA_ "GenSigSendType" SG_ 904 S_NDN_D 3;
BA_ "GenSigSendType" SG_ 904 S_NUP_P 3;
BA_ "GenSigSendType" SG_ 904 S_NDN_P 3;
BA_ "GenSigSendType" SG_ 904 S_STH 3;
BA_ "GenSigSendType" SG_ 904 S_STHAUT 3;
BA_ "GenSigSendType" SG_ 904 S_STH_UP 3;
BA_ "GenSigSendType" SG_ 904 S_STH_DN 3;
BA_ "GenSigSendType" SG_ 904 S_DF_NA 3;
BA_ "GenSigSendType" SG_ 904 S_PF_NA 3;
BA_ "GenSigSendType" SG_ 904 S_NECK_D 3;
BA_ "GenSigSendType" SG_ 904 S_NECK_P 3;
BA_ "GenSigSendType" SG_ 904 S_HUP_D 3;
BA_ "GenSigSendType" SG_ 904 S_HUP_P 3;
BA_ "GenSigSendType" SG_ 904 S_HUP_RR 3;
BA_ "GenSigSendType" SG_ 904 S_HUP_RL 3;
BA_ "GenSigSendType" SG_ 904 S_HDN_D 3;
BA_ "GenSigSendType" SG_ 904 S_HDN_P 3;
BA_ "GenSigSendType" SG_ 904 S_HDN_RR 3;
BA_ "GenSigSendType" SG_ 904 S_HDN_RL 3;
BA_ "GenSigSendType" SG_ 904 S_BUP_D 3;
BA_ "GenSigSendType" SG_ 904 S_BUP_P 3;
BA_ "GenSigSendType" SG_ 904 S_BUP_RR 3;
BA_ "GenSigSendType" SG_ 904 S_BUP_RL 3;
BA_ "GenSigSendType" SG_ 904 S_BDN_D 3;
BA_ "GenSigSendType" SG_ 904 S_BDN_P 3;
BA_ "GenSigSendType" SG_ 904 S_BDN_RR 3;
BA_ "GenSigSendType" SG_ 904 S_BDN_RL 3;
BA_ "GenSigSendType" SG_ 911 SOLRST 3;
BA_ "GenSigSendType" SG_ 911 SL_CSTM 3;
BA_ "GenSigSendType" SG_ 911 SL_RMDG 3;
BA_ "GenSigSendType" SG_ 911 ST_RTCOM 3;
BA_ "GenSigSendType" SG_ 911 AVN07VLD 3;
BA_ "GenSigSendType" SG_ 911 RESDSPID 3;
BA_ "GenSigSendType" SG_ 911 SNCCNTRE 3;
BA_ "GenSigSendType" SG_ 911 DIAGMODE 3;
BA_ "GenSigSendType" SG_ 998 SENSPFM 3;
BA_ "GenSigSendType" SG_ 998 SENSFAIL 3;
BA_ "GenSigSendType" SG_ 998 CONFID11 3;
BA_ "GenSigSendType" SG_ 998 CONFMMC 3;
BA_ "GenSigSendType" SG_ 998 DISTERR 3;
BA_ "GenSigSendType" SG_ 998 CONFLANE 3;
BA_ "GenSigSendType" SG_ 998 CONFDIR 3;
BA_ "GenSigSendType" SG_ 1076 A_LNG_ST 3;
BA_ "GenSigSendType" SG_ 1076 A_LANG 3;
BA_ "GenSigStartValue" SG_ 1076 A_LANG 63;
BA_ "GenSigSendType" SG_ 1076 A_LNGDB1 3;
BA_ "GenSigSendType" SG_ 1076 A_LNGDB2 3;
BA_ "GenSigSendType" SG_ 1076 A_LNGDB3 3;
BA_ "GenSigSendType" SG_ 1076 A_LNGDB4 3;
BA_ "GenSigSendType" SG_ 1076 A_LNGDB5 3;
BA_ "GenSigSendType" SG_ 1076 A_LNGDB6 3;
BA_ "GenSigSendType" SG_ 1076 A_LNGDB7 3;
BA_ "GenSigSendType" SG_ 1076 A_LNGCHG 3;
BA_ "GenSigSendType" SG_ 1077 A_OPEN_S 3;
BA_ "GenSigSendType" SG_ 1077 OPENCHG 3;
BA_ "GenSigSendType" SG_ 1077 CAPSW_S 3;
BA_ "GenSigSendType" SG_ 1077 A_CLR_S 3;
BA_ "GenSigStartValue" SG_ 1077 A_CLR_S 15;
BA_ "GenSigSendType" SG_ 1077 DISP_BRT 3;
BA_ "GenSigStartValue" SG_ 1077 DISP_BRT 5;
BA_ "GenSigSendType" SG_ 1077 DISP_CNT 3;
BA_ "GenSigStartValue" SG_ 1077 DISP_CNT 5;
BA_ "GenSigSendType" SG_ 1077 A_COP_S 3;
BA_ "GenSigSendType" SG_ 1077 A_OP_SUP 3;
BA_ "GenSigSendType" SG_ 1077 DM_PGSW 3;
BA_ "GenSigSendType" SG_ 1077 FAVSET_R 3;
BA_ "GenSigSendType" SG_ 1077 FAVSET_L 3;
BA_ "GenSigSendType" SG_ 1077 A_UNTTMP 3;
BA_ "GenSigSendType" SG_ 1077 A_UNTSP 3;
BA_ "GenSigStartValue" SG_ 1077 A_UNTSP 3;
BA_ "GenSigSendType" SG_ 1077 A_UNTDST 3;
BA_ "GenSigStartValue" SG_ 1077 A_UNTDST 3;
BA_ "GenSigSendType" SG_ 1077 A_TMPCHG 3;
BA_ "GenSigSendType" SG_ 1077 A_SPCHG 3;
BA_ "GenSigSendType" SG_ 1077 A_DSTCHG 3;
BA_ "GenSigSendType" SG_ 1077 A_SPLM 3;
BA_ "GenSigSendType" SG_ 1077 A_UTSPLM 3;
BA_ "GenSigStartValue" SG_ 1077 A_UTSPLM 3;
BA_ "GenSigSendType" SG_ 1078 R1_SWOP 3;
BA_ "GenSigSendType" SG_ 1079 R2_SWOP 3;
BA_ "GenSigSendType" SG_ 794 CLK_YEAR 3;
BA_ "GenSigStartValue" SG_ 794 CLK_YEAR 127;
BA_ "GenSigSendType" SG_ 794 CLK_MONT 3;
BA_ "GenSigStartValue" SG_ 794 CLK_MONT 15;
BA_ "GenSigSendType" SG_ 794 CLK_DAY 3;
BA_ "GenSigSendType" SG_ 794 CLK_HOUR 3;
BA_ "GenSigStartValue" SG_ 794 CLK_HOUR 31;
BA_ "GenSigSendType" SG_ 794 GPS_ST 3;
BA_ "GenSigSendType" SG_ 794 GPS_CRCT 3;
BA_ "GenSigStartValue" SG_ 794 GPS_CRCT 3;
BA_ "GenSigSendType" SG_ 794 CLK_MIN 3;
BA_ "GenSigStartValue" SG_ 794 CLK_MIN 63;
BA_ "GenSigSendType" SG_ 794 CLK_SEC 3;
BA_ "GenSigStartValue" SG_ 794 CLK_SEC 63;
BA_ "GenSigSendType" SG_ 794 DST_S30 3;
BA_ "GenSigStartValue" SG_ 794 DST_S30 3;
BA_ "GenSigSendType" SG_ 794 TZ 3;
BA_ "GenSigStartValue" SG_ 794 TZ 63;
BA_ "GenSigSendType" SG_ 794 TZ_SIGN 3;
BA_ "GenSigStartValue" SG_ 794 TZ_SIGN 3;
BA_ "GenSigSendType" SG_ 1418 P_DCS 3;
BA_ "GenSigSendType" SG_ 1418 C_DCS 3;
BA_ "GenSigSendType" SG_ 1418 AC_DCS 3;
BA_ "GenSigSendType" SG_ 1418 AVN39VLD 3;
BA_ "GenSigSendType" SG_ 1418 C_ST_DCS 3;
BA_ "GenSigSendType" SG_ 1418 C_SU_DCS 3;
BA_ "GenSigSendType" SG_ 1418 C_BR_DCS 3;
BA_ "GenSigSendType" SG_ 1418 DM_AVN_D 3;
BA_ "GenSigSendType" SG_ 1418 BDR_S_SW 3;
BA_ "GenSigSendType" SG_ 1418 CRLMD_SW 3;
BA_ "GenSigSendType" SG_ 1418 CRAWL_M 3;
BA_ "GenSigSendType" SG_ 1418 CRAWL_P 3;
BA_ "GenSigSendType" SG_ 1418 BH_SW 3;
BA_ "GenSigSendType" SG_ 1418 TRCOFFSW 3;
BA_ "GenSigSendType" SG_ 1418 VSCOFFSW 3;
BA_ "GenSigSendType" SG_ 1418 EVMD_SW 3;
BA_ "GenSigSendType" SG_ 1418 NMRBR_SW 3;
BA_ "GenSigSendType" SG_ 1418 DAC_S_SW 3;
BA_ "GenSigSendType" SG_ 1418 MN_MD_SW 3;
BA_ "GenSigSendType" SG_ 1418 MS_MD_SW 3;
BA_ "GenSigSendType" SG_ 1418 RD_MD_SW 3;
BA_ "GenSigSendType" SG_ 1418 TR_MD_SW 3;
BA_ "GenSigSendType" SG_ 1309 REQ_ECU 3;
BA_ "GenSigSendType" SG_ 1309 BTN_FLG 3;
BA_ "GenSigSendType" SG_ 1309 CUST_ID 3;
BA_ "GenSigSendType" SG_ 1309 CUST_VAL 3;
BA_ "GenSigSendType" SG_ 445 DSP_SW 3;
BA_ "GenSigSendType" SG_ 445 DSC_SW 3;
BA_ "GenSigSendType" SG_ 445 DAL_SW 3;
BA_ "GenSigSendType" SG_ 445 OSC_SW 3;
BA_ "GenSigSendType" SG_ 445 DRM_SW 3;
BA_ "GenSigSendType" SG_ 445 DRA_SW 3;
BA_ "GenSigSendType" SG_ 445 PSP_SW 3;
BA_ "GenSigSendType" SG_ 445 PSC_SW 3;
BA_ "GenSigSendType" SG_ 445 PAL_SW 3;
BA_ "GenSigSendType" SG_ 445 PRM_SW 3;
BA_ "GenSigSendType" SG_ 445 PRA_SW 3;
BA_ "GenSigSendType" SG_ 445 DRSF_SW 3;
BA_ "GenSigSendType" SG_ 445 D_ES_SW 3;
BA_ "GenSigSendType" SG_ 445 PMO_SW 3;
BA_ "GenSigSendType" SG_ 445 PRSF_SW 3;
BA_ "GenSigSendType" SG_ 445 P_ES_SW 3;
BA_ "GenSigSendType" SG_ 445 R_ES_SW 3;
BA_ "GenSigSendType" SG_ 445 SSEL_SW 3;
BA_ "GenSigSendType" SG_ 445 FO_RE_SW 3;
BA_ "GenSigSendType" SG_ 445 WI_RE_SW 3;
BA_ "GenSigSendType" SG_ 445 AR_ES_SW 3;
BA_ "GenSigSendType" SG_ 445 AFR_SW 3;
BA_ "GenSigStartValue" SG_ 859 CLE_HUM 254;
BA_ "GenSigStartValue" SG_ 859 CLE_TAM 126;
BA_ "GenSigStartValue" SG_ 859 CLE_OK 2;
BA_ "GenSigStartValue" SG_ 859 CLE_COF 2;
BA_ "GenSigStartValue" SG_ 969 MMC1 2147483647;
BA_ "GenSigStartValue" SG_ 969 MMC2 2147483647;
BA_ "GenSigStartValue" SG_ 1168 DLID 65535;
BA_ "GenSigStartValue" SG_ 1168 LID 4294967295;
BA_ "GenSigStartValue" SG_ 1311 DLINKP 65535;
BA_ "GenSigStartValue" SG_ 1311 RCODE 65535;
BA_ "GenSigSendType" SG_ 1322 HUCMP 3;
BA_ "GenSigStartValue" SG_ 1322 HUCMP 5;
BA_ "GenSigSendType" SG_ 1322 DCUNO 3;
BA_ "GenSigSendType" SG_ 1322 MEUNO 3;
BA_ "GenSigSendType" SG_ 1322 MBV 3;
BA_ "GenSigSendType" SG_ 1322 ETC_SW 3;
BA_ "GenSigSendType" SG_ 782 B1_FUNID 3;
BA_ "GenSigSendType" SG_ 782 B1_INST1 3;
BA_ "GenSigSendType" SG_ 782 B1_INST2 3;
BA_ "GenSigSendType" SG_ 782 B1_INST3 3;
BA_ "GenSigSendType" SG_ 782 B1_INST4 3;
BA_ "GenSigSendType" SG_ 782 B1_INST5 3;
BA_ "GenSigSendType" SG_ 782 B1_INST6 3;
BA_ "GenSigSendType" SG_ 782 B1_INST7 3;
BA_ "GenSigSendType" SG_ 1313 HOME_SET 3;
BA_ "GenSigSendType" SG_ 1313 HOME_DIS 3;
BA_ "GenSigStartValue" SG_ 1313 HOME_DIS 63;
BA_ "GenSigSendType" SG_ 1313 COMPASS 3;
BA_ "GenSigStartValue" SG_ 1313 COMPASS 63;
BA_ "GenSigSendType" SG_ 1313 NAVSTAT 3;
BA_ "GenSigSendType" SG_ 1313 SSDVOL_O 3;
BA_ "GenSigSendType" SG_ 1313 DSCNUM 3;
BA_ "GenSigSendType" SG_ 1313 DGPSRL 3;
BA_ "GenSigSendType" SG_ 1313 DSCENE 3;
BA_ "GenSigSendType" SG_ 1313 DUSMND 3;
BA_ "GenSigSendType" SG_ 1313 DBSTRT 3;
BA_ "GenSigSendType" SG_ 1313 DSOCTG 3;
BA_ "GenSigSendType" SG_ 682 AVN_ON 3;
BA_ "GenSigSendType" SG_ 682 CC_MODE 3;
BA_ "GenSigSendType" SG_ 682 IRQ_MM 3;
BA_ "GenSigSendType" SG_ 682 CMD_MODE 3;
BA_ "GenSigSendType" SG_ 682 DI_MODE 3;
BA_ "GenSigSendType" SG_ 682 MM_RESET 3;
BA_ "GenSigSendType" SG_ 682 X_COORD 3;
BA_ "GenSigSendType" SG_ 682 DN_DISP 3;
BA_ "GenSigSendType" SG_ 682 MMD_MODE 3;
BA_ "GenSigSendType" SG_ 682 SW_PVM 3;
BA_ "GenSigSendType" SG_ 682 CUST_TRA 3;
BA_ "GenSigSendType" SG_ 682 CUST_APP 3;
BA_ "GenSigSendType" SG_ 682 CUST_PVM 3;
BA_ "GenSigSendType" SG_ 682 Y_COORD 3;
BA_ "GenSigSendType" SG_ 682 VR_STATE 3;
BA_ "GenSigSendType" SG_ 682 MIC_POS 3;
BA_ "GenSigSendType" SG_ 682 X2_COORD 3;
BA_ "GenSigSendType" SG_ 682 CD_SIZE 3;
BA_ "GenSigSendType" SG_ 682 Y2_COORD 3;
BA_ "GenSigSendType" SG_ 837 ACCSW 3;
BA_ "GenSigSendType" SG_ 837 ACC_FLG 3;
BA_ "GenSigSendType" SG_ 837 AVN_FUNC 3;
BA_ "GenSigSendType" SG_ 837 WUP_STAT 3;
BA_ "GenSigSendType" SG_ 838 OTA2RSLT 3;
BA_ "GenSigSendType" SG_ 838 OTA3RSLT 3;
BA_ "GenSigSendType" SG_ 838 OTADRSLT 3;
BA_ "GenSigSendType" SG_ 838 SRVC_STT 3;
BA_ "GenSigSendType" SG_ 838 OTA2CNCL 3;
BA_ "GenSigSendType" SG_ 838 OTA3CNCL 3;
BA_ "GenSigSendType" SG_ 838 OTADCNCL 3;
BA_ "GenSigSendType" SG_ 838 CUR_DRV 3;
BA_ "GenSigSendType" SG_ 838 SRVC_PC 3;
BA_ "GenSigSendType" SG_ 838 SRVC_VC 3;
BA_ "GenSigSendType" SG_ 838 SRVC_AC 3;
BA_ "GenSigSendType" SG_ 838 OTAPPCTL 3;
BA_ "GenSigSendType" SG_ 838 CW_MD_SW 3;
BA_ "GenSigSendType" SG_ 838 VNHLDRQ 3;
BA_ "GenSigSendType" SG_ 838 TRNCASW 3;
BA_ "GenSigSendType" SG_ 838 TRNSD 3;
BA_ "GenSigSendType" SG_ 838 TRNFBPD 3;
BA_ "GenSigSendType" SG_ 838 OTACDRLT 3;
BA_ "GenSigSendType" SG_ 838 OTACHGEX 3;
BA_ "GenSigSendType" SG_ 838 OTAACTTP 3;
BA_ "GenSigSendType" SG_ 838 OTAACTPH 3;
BA_ "GenSigSendType" SG_ 838 OTASWACT 3;
BA_ "GenSigSendType" SG_ 838 OTASTAT 3;
BA_ "GenSigSendType" SG_ 985 S_FRONOF 3;
BA_ "GenSigSendType" SG_ 985 S_WFRCR 3;
BA_ "GenSigSendType" SG_ 985 S_RFRCR 3;
BA_ "GenSigSendType" SG_ 985 S_WFRSTR 3;
BA_ "GenSigSendType" SG_ 985 S_RFRSTR 3;
BA_ "GenSigSendType" SG_ 985 S_PMREMO 3;
BA_ "GenSigSendType" SG_ 985 S_BLWCL 3;
BA_ "GenSigSendType" SG_ 985 S_HBCD_D 3;
BA_ "GenSigSendType" SG_ 985 S_HBMD_D 3;
BA_ "GenSigSendType" SG_ 985 S_HBCD_P 3;
BA_ "GenSigSendType" SG_ 985 S_HBMD_P 3;
BA_ "GenSigSendType" SG_ 985 S_HBCDRR 3;
BA_ "GenSigSendType" SG_ 985 S_HBMDRR 3;
BA_ "GenSigSendType" SG_ 985 S_HBCDRL 3;
BA_ "GenSigSendType" SG_ 985 S_HBMDRL 3;
BA_ "GenSigSendType" SG_ 985 S_STHCD 3;
BA_ "GenSigSendType" SG_ 985 V_FG_CH 3;
BA_ "GenSigSendType" SG_ 985 V_FG_LVL 3;
BA_ "GenSigSendType" SG_ 985 V_FG_PWR 3;
BA_ "GenSigSendType" SG_ 985 S_FG_CH 3;
BA_ "GenSigSendType" SG_ 985 S_FG_LVL 3;
BA_ "GenSigSendType" SG_ 985 S_TMODE 3;
BA_ "GenSigSendType" SG_ 996 DEL_UN 3;
BA_ "GenSigSendType" SG_ 996 MSR_DRV 3;
BA_ "GenSigSendType" SG_ 996 PRMPIEXE 3;
BA_ "GenSigSendType" SG_ 996 SPHN_UID 3;
BA_ "GenSigSendType" SG_ 996 OPTPIEXE 3;
BA_ "GenSigSendType" SG_ 996 MREQ_FPT 3;
BA_ "GenSigSendType" SG_ 996 MREG_EXE 3;
BA_ "GenSigSendType" SG_ 996 MPOS_FPT 3;
BA_ "GenSigSendType" SG_ 996 DIDPIEXE 3;
BA_ "GenSigSendType" SG_ 996 F_GST_MD 3;
BA_ "GenSigSendType" SG_ 996 MREQ_DPM 3;
BA_ "GenSigSendType" SG_ 996 REQPIEXE 3;
BA_ "GenSigSendType" SG_ 996 UI_DEPLY 3;
BA_ "GenSigSendType" SG_ 996 DK_ALDRQ 3;
BA_ "GenSigSendType" SG_ 996 DK_DLCRQ 3;
BA_ "GenSigSendType" SG_ 960 A_CURHRQ 3;
BA_ "GenSigStartValue" SG_ 960 A_CURHRQ 3;
BA_ "GenSigSendType" SG_ 960 A_CURREQ 3;
BA_ "GenSigStartValue" SG_ 960 A_CURREQ 7;
BA_ "GenSigSendType" SG_ 960 A_CLCREQ 3;
BA_ "GenSigSendType" SG_ 960 A_LMTHRQ 3;
BA_ "GenSigStartValue" SG_ 960 A_LMTHRQ 3;
BA_ "GenSigSendType" SG_ 960 A_SLMREQ 3;
BA_ "GenSigStartValue" SG_ 960 A_SLMREQ 7;
BA_ "GenSigSendType" SG_ 960 A_LMTREQ 3;
BA_ "GenSigStartValue" SG_ 960 A_LMTREQ 7;
BA_ "GenSigSendType" SG_ 960 A_SPLMOD 3;
BA_ "GenSigSendType" SG_ 960 A_TMRHRQ 3;
BA_ "GenSigStartValue" SG_ 960 A_TMRHRQ 3;
BA_ "GenSigSendType" SG_ 960 A_LMTSRQ 3;
BA_ "GenSigStartValue" SG_ 960 A_LMTSRQ 3;
BA_ "GenSigSendType" SG_ 960 A_SLMDRQ 3;
BA_ "GenSigSendType" SG_ 960 A_DPWREQ 3;
BA_ "GenSigStartValue" SG_ 960 A_DPWREQ 15;
BA_ "GenSigSendType" SG_ 960 A_PNCREQ 3;
BA_ "GenSigSendType" SG_ 960 A_CEIBPH 3;
BA_ "GenSigSendType" SG_ 960 A_DVOREQ 3;
BA_ "GenSigSendType" SG_ 960 A_CHGCRQ 3;
BA_ "GenSigSendType" SG_ 960 OUTCS 3;
BA_ "GenSigSendType" SG_ 960 JDTCS 3;
BA_ "GenSigSendType" SG_ 492 RECEND 3;
BA_ "GenSigSendType" SG_ 492 DRAVNABN 3;
BA_ "GenSigSendType" SG_ 492 RECRNON 3;
BA_ "GenSigSendType" SG_ 492 IMGI_POF 3;
BA_ "GenSigSendType" SG_ 492 DVRACT 3;
BA_ "GenSigSendType" SG_ 492 DISCODET 3;
BA_ "GenSigSendType" SG_ 492 SET_PCON 3;
BA_ "GenSigSendType" SG_ 492 SET_PALM 3;
BA_ "GenSigSendType" SG_ 492 SET_PG 3;
BA_ "GenSigSendType" SG_ 492 SET_ALL 3;
BA_ "GenSigSendType" SG_ 492 ROLLCNT 3;
BA_ "GenSigSendType" SG_ 858 QIC_MTS 3;
BA_ "GenSigSendType" SG_ 858 QIC_MTM 3;
BA_ "GenSigSendType" SG_ 858 QIC_FSS 3;
BA_ "GenSigSendType" SG_ 858 QIC_MPTS 3;
BA_ "GenSigSendType" SG_ 858 QIC_MPTM 3;
BA_ "GenSigSendType" SG_ 858 QIC_MPQK 3;
BA_ "GenSigSendType" SG_ 858 QIC_FTS 3;
BA_ "GenSigSendType" SG_ 858 QIC_FTM 3;
BA_ "GenSigSendType" SG_ 858 QIC_FSP 3;
BA_ "GenSigSendType" SG_ 858 QIC_BTS 3;
BA_ "GenSigSendType" SG_ 858 SIC_BCS 3;
BA_ "GenSigSendType" SG_ 858 QIC_BTM 3;
BA_ "GenSigSendType" SG_ 858 QIC_BSP 3;
BA_ "GenSigSendType" SG_ 858 SIC_RBCS 3;
BA_ "GenSigSendType" SG_ 858 QIC_RTS 3;
BA_ "GenSigSendType" SG_ 858 QIC_RTM 3;
BA_ "GenSigSendType" SG_ 858 QIC_RSET 3;
BA_ "GenSigSendType" SG_ 858 QIC_RSTS 3;
BA_ "GenSigSendType" SG_ 858 QIC_RSTM 3;
BA_ "GenSigSendType" SG_ 858 QIC_RKQK 3;
BA_ "GenSigSendType" SG_ 858 SIC_IDN 3;
BA_ "GenSigSendType" SG_ 858 SIC_IDS 3;
BA_ "GenSigSendType" SG_ 858 AIC_IDA 3;
BA_ "GenSigSendType" SG_ 858 QDK_ADLQ 3;
BA_ "GenSigSendType" SG_ 858 QDK_ODRQ 3;
BA_ "GenSigSendType" SG_ 858 QDK_OGRQ 3;
BA_ "GenSigSendType" SG_ 858 QDK_ORRQ 3;
BA_ "GenSigSendType" SG_ 858 QDK_OWCQ 3;
BA_ "GenSigSendType" SG_ 858 QDK_OCRQ 3;
BA_ "GenSigSendType" SG_ 858 QDK_FDRQ 3;
BA_ "GenSigSendType" SG_ 858 SIC_RSES 3;
BA_ "GenSigSendType" SG_ 858 QDK_CRQ 3;
BA_ "GenSigSendType" SG_ 858 SLID_REQ 3;
BA_ "GenSigSendType" SG_ 858 QSM_CARE 3;
BA_ "GenSigSendType" SG_ 858 QSM_CQTI 3;
BA_ "GenSigSendType" SG_ 858 QSM_CRNG 3;
BA_ "GenSigSendType" SG_ 858 QSM_CRQ 3;
BA_ "GenSigSendType" SG_ 858 QCL_OPEQ 3;
BA_ "GenSigSendType" SG_ 858 QCL_RQTG 3;
BA_ "GenSigSendType" SG_ 858 QRS_OPEQ 3;
BA_ "GenSigSendType" SG_ 858 QDK_CARE 3;
BA_ "GenSigSendType" SG_ 858 QDK_CQTI 3;
BA_ "GenSigSendType" SG_ 858 QDK_CRNG 3;
BA_ "GenSigSendType" SG_ 858 QDK_DLTI 3;
BA_ "GenSigSendType" SG_ 1301 MS_MD 3;
BA_ "GenSigStartValue" SG_ 1301 MS_ILCL1 127;
BA_ "GenSigStartValue" SG_ 1301 MS_ILCL2 127;
BA_ "GenSigStartValue" SG_ 1301 MS_ILCL3 127;
BA_ "GenSigStartValue" SG_ 1301 MS_ILCL4 127;
BA_ "GenSigStartValue" SG_ 1301 MS_ILCL5 127;
BA_ "GenSigStartValue" SG_ 1301 MS_ILCL6 127;
BA_ "GenSigSendType" SG_ 722 SVCRADC 3;
BA_ "GenSigSendType" SG_ 722 SVCRFRD 3;
BA_ "GenSigSendType" SG_ 722 SVCRFRR 3;
BA_ "GenSigSendType" SG_ 722 SVCRFLR 3;
BA_ "GenSigSendType" SG_ 722 SVCRRRR 3;
BA_ "GenSigSendType" SG_ 722 SVCRRLR 3;
BA_ "GenSigSendType" SG_ 722 SVCRBDCF 3;
BA_ "GenSigSendType" SG_ 722 SVCRBDCR 3;
BA_ "GenSigSendType" SG_ 722 SVCRBDCL 3;
BA_ "GenSigSendType" SG_ 722 SVCRCDC 3;
BA_ "GenSigSendType" SG_ 722 SVCRDCM 3;
BA_ "GenSigSendType" SG_ 722 SVCRLFR 3;
BA_ "GenSigSendType" SG_ 722 SVCRDDC 3;
BA_ "GenSigSendType" SG_ 722 SVCRALL 3;
BA_ "GenSigSendType" SG_ 722 SVCRREV1 3;
BA_ "GenSigSendType" SG_ 722 SVCRREV2 3;
BA_ "GenSigSendType" SG_ 498 CSET_PAD 3;
BA_ "GenSigSendType" SG_ 498 DRRECRN 3;
BA_ "GenSigSendType" SG_ 498 DRACT 3;
BA_ "GenSigSendType" SG_ 498 OFFS_PAD 3;
BA_ "GenSigSendType" SG_ 498 CSET_PG 3;
BA_ "GenSigSendType" SG_ 498 CSET_PAA 3;
BA_ "GenSigSendType" SG_ 498 CSET_ALL 3;
BA_ "GenSigSendType" SG_ 498 RMSETACK 3;
BA_ "GenSigSendType" SG_ 498 STRMACK 3;
BA_ "GenSigSendType" SG_ 498 PROTACK 3;
BA_ "GenSigSendType" SG_ 498 HLREQ 3;
BA_ "GenSigSendType" SG_ 498 OFFS_PG 3;
BA_ "GenSigSendType" SG_ 498 STATACK 3;
BA_ "GenSigSendType" SG_ 498 DRCDCABN 3;
BA_ "GenSigSendType" SG_ 498 DRDISMOD 3;
BA_ "GenSigSendType" SG_ 724 UMOPIF01 3;
BA_ "GenSigSendType" SG_ 724 UMOPRQ01 3;
BA_ "GenSigSendType" SG_ 724 UMOPRV01 3;
BA_ "GenSigSendType" SG_ 724 UMOPRD01 3;
BA_ "GenSigSendType" SG_ 725 UMOPIF02 3;
BA_ "GenSigSendType" SG_ 725 UMOPRQ02 3;
BA_ "GenSigSendType" SG_ 725 UMOPRV02 3;
BA_ "GenSigSendType" SG_ 725 UMOPRD02 3;
BA_ "GenSigSendType" SG_ 726 UMOPIF03 3;
BA_ "GenSigSendType" SG_ 726 UMOPRQ03 3;
BA_ "GenSigSendType" SG_ 726 UMOPRV03 3;
BA_ "GenSigSendType" SG_ 726 UMOPRD03 3;
BA_ "GenSigSendType" SG_ 727 UMOPIF04 3;
BA_ "GenSigSendType" SG_ 727 UMOPRQ04 3;
BA_ "GenSigSendType" SG_ 727 UMOPRV04 3;
BA_ "GenSigSendType" SG_ 727 UMOPRD04 3;
BA_ "GenSigSendType" SG_ 735 UMOPIF05 3;
BA_ "GenSigSendType" SG_ 735 UMOPRQ05 3;
BA_ "GenSigSendType" SG_ 735 UMOPRV05 3;
BA_ "GenSigSendType" SG_ 735 UMOPRD05 3;
BA_ "GenSigSendType" SG_ 736 UMOPIF06 3;
BA_ "GenSigSendType" SG_ 736 UMOPRQ06 3;
BA_ "GenSigSendType" SG_ 736 UMOPRV06 3;
BA_ "GenSigSendType" SG_ 736 UMOPRD06 3;
BA_ "GenSigSendType" SG_ 737 UMOPIF07 3;
BA_ "GenSigSendType" SG_ 737 UMOPRQ07 3;
BA_ "GenSigSendType" SG_ 737 UMOPRV07 3;
BA_ "GenSigSendType" SG_ 737 UMOPRD07 3;
BA_ "GenSigSendType" SG_ 738 UMOPIF08 3;
BA_ "GenSigSendType" SG_ 738 UMOPRQ08 3;
BA_ "GenSigSendType" SG_ 738 UMOPRV08 3;
BA_ "GenSigSendType" SG_ 738 UMOPRD08 3;
BA_ "GenSigSendType" SG_ 751 UMOPIF09 3;
BA_ "GenSigSendType" SG_ 751 UMOPRQ09 3;
BA_ "GenSigSendType" SG_ 751 UMOPRV09 3;
BA_ "GenSigSendType" SG_ 751 UMOPRD09 3;
BA_ "GenSigSendType" SG_ 752 UMOPIF10 3;
BA_ "GenSigSendType" SG_ 752 UMOPRQ10 3;
BA_ "GenSigSendType" SG_ 752 UMOPRV10 3;
BA_ "GenSigSendType" SG_ 752 UMOPRD10 3;
BA_ "GenSigSendType" SG_ 754 UMOPIF11 3;
BA_ "GenSigSendType" SG_ 754 UMOPRQ11 3;
BA_ "GenSigSendType" SG_ 754 UMOPRV11 3;
BA_ "GenSigSendType" SG_ 754 UMOPRD11 3;
BA_ "GenSigSendType" SG_ 757 UMOPIF12 3;
BA_ "GenSigSendType" SG_ 757 UMOPRQ12 3;
BA_ "GenSigSendType" SG_ 757 UMOPRV12 3;
BA_ "GenSigSendType" SG_ 757 UMOPRD12 3;
BA_ "GenSigSendType" SG_ 389 DSADINX 3;
BA_ "GenSigSendType" SG_ 389 DSADINY 3;
BA_ "GenSigSendType" SG_ 389 DSSHTSW 3;
BA_ "GenSigSendType" SG_ 389 DCADINX 3;
BA_ "GenSigSendType" SG_ 389 DCADINY 3;
BA_ "GenSigSendType" SG_ 389 DCSHTSW 3;
BA_ "GenSigSendType" SG_ 389 PSADINX 3;
BA_ "GenSigSendType" SG_ 389 PSADINY 3;
BA_ "GenSigSendType" SG_ 389 PSSHTSW 3;
BA_ "GenSigSendType" SG_ 389 PCADINX 3;
BA_ "GenSigSendType" SG_ 389 PCADINY 3;
BA_ "GenSigSendType" SG_ 389 PCSHTSW 3;
BA_ "GenSigSendType" SG_ 389 RRCADINX 3;
BA_ "GenSigSendType" SG_ 389 RRCADINY 3;
BA_ "GenSigSendType" SG_ 389 RRCSHTSW 3;
BA_ "GenSigSendType" SG_ 389 RLCADINX 3;
BA_ "GenSigSendType" SG_ 389 RLCADINY 3;
BA_ "GenSigSendType" SG_ 389 RLCSHTSW 3;
BA_ "GenSigSendType" SG_ 389 ERSWISWD 3;
BA_ "GenSigSendType" SG_ 389 BLMDCUST 3;
BA_ "GenSigSendType" SG_ 389 DSPADIN 3;
BA_ "GenSigSendType" SG_ 389 DCPADIN 3;
BA_ "GenSigSendType" SG_ 389 PSPADIN 3;
BA_ "GenSigSendType" SG_ 389 PCPADIN 3;
BA_ "GenSigSendType" SG_ 389 RRCPADIN 3;
BA_ "GenSigSendType" SG_ 389 RLCPADIN 3;
BA_ "GenSigSendType" SG_ 389 ERSWISWP 3;
BA_ "GenSigSendType" SG_ 389 ERSPTSWP 3;
BA_ "GenSigSendType" SG_ 389 ERSPRSWP 3;
BA_ "GenSigSendType" SG_ 389 ERSPTSWD 3;
BA_ "GenSigSendType" SG_ 389 ERSPRSWD 3;
BA_ "GenSigSendType" SG_ 758 PDRVSTS 3;
BA_ "GenSigSendType" SG_ 758 PFR1STS 3;
BA_ "GenSigSendType" SG_ 758 PFR2STS 3;
BA_ "GenSigSendType" SG_ 760 SBCGROTA 3;
BA_ "GenSigSendType" SG_ 760 SBCRVOTA 3;
BA_ "GenSigSendType" SG_ 760 RDYOF_RQ 3;
BA_ "GenSigSendType" SG_ 762 ECUPWCRQ 3;
BA_ "GenSigSendType" SG_ 762 PWCRQMOD 3;
BA_ "GenSigSendType" SG_ 762 PWCRQID 3;
BA_ "GenSigSendType" SG_ 762 PWCTID01 3;
BA_ "GenSigSendType" SG_ 762 PWCTID02 3;
BA_ "GenSigSendType" SG_ 762 PWCTID03 3;
BA_ "GenSigSendType" SG_ 762 PWCTID04 3;
BA_ "GenSigSendType" SG_ 762 PWCTID05 3;
BA_ "GenSigSendType" SG_ 762 PWCTID06 3;
BA_ "GenSigSendType" SG_ 762 PWCTID07 3;
BA_ "GenSigSendType" SG_ 762 PWCTID08 3;
BA_ "GenSigSendType" SG_ 762 PWCTID09 3;
BA_ "GenSigSendType" SG_ 762 PWCTID10 3;
BA_ "GenSigSendType" SG_ 763 VPSCROTA 3;
BA_ "GenSigSendType" SG_ 826 A_DPSRQ 3;
BA_ "GenSigSendType" SG_ 826 A_DPID 3;
BA_ "GenSigSendType" SG_ 826 A_DPON 3;
BA_ "GenSigSendType" SG_ 826 A_DPTYP 3;
BA_ "GenSigSendType" SG_ 826 A_DPDAY 3;
BA_ "GenSigSendType" SG_ 826 A_DPMON 3;
BA_ "GenSigSendType" SG_ 826 A_DPDAT 3;
BA_ "GenSigSendType" SG_ 826 A_DPDTM 3;
BA_ "GenSigSendType" SG_ 826 A_DPAC 3;
BA_ "GenSigSendType" SG_ 826 A_DPBC 3;
BA_ "GenSigSendType" SG_ 826 A_DPTMP 3;
BA_ "GenSigSendType" SG_ 826 A_DPACMD 3;
BA_ "GenSigSendType" SG_ 826 A_DPSH 3;
BA_ "GenSigSendType" SG_ 826 A_DPREFR 3;
BA_ "GenSigStartValue" SG_ 826 A_DPREFR 3;
BA_ "GenSigSendType" SG_ 826 A_DPBLLV 3;
BA_ "GenSigStartValue" SG_ 826 A_DPBLLV 15;
BA_ "GenSigSendType" SG_ 826 A_DPFDHV 3;
BA_ "GenSigSendType" SG_ 826 A_DPFPHV 3;
BA_ "GenSigSendType" SG_ 826 A_DPRDHV 3;
BA_ "GenSigSendType" SG_ 826 A_DPRPHV 3;
BA_ "GenSigSendType" SG_ 826 A_DPFDEF 3;
BA_ "GenSigSendType" SG_ 826 A_DPRDEF 3;
BA_ "GenSigSendType" SG_ 826 A_DPFGON 3;
BA_ "GenSigSendType" SG_ 826 A_DPFGLV 3;
BA_ "GenSigSendType" SG_ 826 A_DPFGCH 3;
BA_ "GenSigSendType" SG_ 826 A_DPACTM 3;
BA_ "GenSigStartValue" SG_ 826 A_DPACTM 7;
BA_ "GenSigSendType" SG_ 826 MRONPSH 3;
BA_ "GenSigSendType" SG_ 826 MROFFPSH 3;
BA_ "GenSigSendType" SG_ 826 MRSOCSEL 3;
BA_ "GenSigSendType" SG_ 826 MRMETSEL 3;
BA_ "GenSigStartValue" SG_ 826 MRMETSEL 1;
BA_ "GenSigSendType" SG_ 826 MRMETANS 3;
BA_ "GenSigStartValue" SG_ 826 MRMETANS 1;
BA_ "GenSigSendType" SG_ 826 EXONPSH 3;
BA_ "GenSigSendType" SG_ 826 EXOFFPSH 3;
BA_ "GenSigSendType" SG_ 826 SMTRDYSW 3;
BA_ "GenSigSendType" SG_ 826 TMEXOP 3;
BA_ "GenSigSendType" SG_ 1086 A_SETSTS 3;
BA_ "GenSigSendType" SG_ 1086 A_BPON 3;
BA_ "GenSigSendType" SG_ 1086 A_BPWKD 3;
BA_ "GenSigSendType" SG_ 1086 A_BPID 3;
BA_ "GenSigStartValue" SG_ 1086 A_BPID 7;
BA_ "GenSigSendType" SG_ 1086 A_DEPTM 3;
BA_ "GenSigStartValue" SG_ 1086 A_DEPTM 511;
BA_ "GenSigSendType" SG_ 1086 A_BPNXT 3;
BA_ "GenSigSendType" SG_ 1086 A_BPSET 3;
BA_ "GenSigSendType" SG_ 1086 A_ACSET 3;
BA_ "GenSigSendType" SG_ 1086 A_NCTYP 3;
BA_ "GenSigStartValue" SG_ 1086 A_NCTYP 15;
BA_ "GenSigSendType" SG_ 1086 A_NCWKD 3;
BA_ "GenSigSendType" SG_ 1086 A_NCSTM 3;
BA_ "GenSigStartValue" SG_ 1086 A_NCSTM 511;
BA_ "GenSigSendType" SG_ 1086 A_NCFTM 3;
BA_ "GenSigStartValue" SG_ 1086 A_NCFTM 511;
BA_ "GenSigSendType" SG_ 1086 A_SETID 3;
BA_ "GenSigStartValue" SG_ 1086 A_SETID 63;
BA_ "GenSigSendType" SG_ 1086 A_SETON 3;
BA_ "GenSigSendType" SG_ 1086 A_SETWKD 3;
BA_ "GenSigSendType" SG_ 1086 A_SETTYP 3;
BA_ "GenSigSendType" SG_ 1086 A_SETSTM 3;
BA_ "GenSigStartValue" SG_ 1086 A_SETSTM 511;
BA_ "GenSigSendType" SG_ 1086 A_SETNXT 3;
BA_ "GenSigSendType" SG_ 1086 A_SETFTM 3;
BA_ "GenSigStartValue" SG_ 1086 A_SETFTM 511;
BA_ "GenSigSendType" SG_ 1086 A_SETID2 3;
BA_ "GenSigSendType" SG_ 1086 A_SETON2 3;
BA_ "GenSigSendType" SG_ 1086 A_SETRE2 3;
BA_ "GenSigSendType" SG_ 1086 A_SETMO2 3;
BA_ "GenSigSendType" SG_ 1086 A_SETST2 3;
BA_ "GenSigStartValue" SG_ 1086 A_SETST2 511;
BA_ "GenSigSendType" SG_ 1086 A_SETNX2 3;
BA_ "GenSigSendType" SG_ 1086 A_SETFT2 3;
BA_ "GenSigStartValue" SG_ 1086 A_SETFT2 511;
BA_ "GenSigSendType" SG_ 1086 A_LMTRE2 3;
BA_ "GenSigStartValue" SG_ 1086 A_LMTRE2 7;
BA_ "GenSigSendType" SG_ 1086 A_OCTID 3;
BA_ "GenSigSendType" SG_ 1086 A_OCOKNG 3;
BA_ "GenSigSendType" SG_ 1086 A_VPPREQ 3;
BA_ "GenSigSendType" SG_ 1086 A_LMTACC 3;
BA_ "GenSigStartValue" SG_ 1086 A_LMTACC 7;
BA_ "GenSigSendType" SG_ 1548 MAVMUTE 3;
BA_ "GenSigSendType" SG_ 1548 CS_FDIST 3;
BA_ "GenSigSendType" SG_ 1548 CS_RDIST 3;
BA_ "GenSigSendType" SG_ 1548 MOASW 3;
BA_ "GenSigSendType" SG_ 1548 AUTOONAL 3;
BA_ "GenSigSendType" SG_ 1548 RCD_DE 3;
BA_ "GenSigSendType" SG_ 1548 CSR_WA 3;
BA_ "GenSigSendType" SG_ 1548 PVMHSW 3;
BA_ "GenSigSendType" SG_ 1548 PVM_WASH 3;
BA_ "GenSigSendType" SG_ 1548 FCWCTSW 3;
BA_ "GenSigSendType" SG_ 1548 FCWSESW 3;
BA_ "GenSigSendType" SG_ 1548 CDWCTSW 3;
BA_ "GenSigSendType" SG_ 1548 TLACTSW 3;
BA_ "GenSigSendType" SG_ 1548 SLFCTSW 3;
BA_ "GenSigSendType" SG_ 1548 CSWCTSW 3;
BA_ "GenSigSendType" SG_ 1548 AESCTSW 3;
BA_ "GenSigSendType" SG_ 1548 ACCCTSW 3;
BA_ "GenSigSendType" SG_ 1548 CPCTSW 3;
BA_ "GenSigSendType" SG_ 1548 LDKCTSW 3;
BA_ "GenSigSendType" SG_ 1548 LDKSNSW 3;
BA_ "GenSigSendType" SG_ 1548 ELKCTSW 3;
BA_ "GenSigSendType" SG_ 1548 ELKMDSW 3;
BA_ "GenSigSendType" SG_ 1548 GDNCTSW 3;
BA_ "GenSigSendType" SG_ 1548 GDNWNSW 3;
BA_ "GenSigSendType" SG_ 1548 GDNBKSW 3;
BA_ "GenSigSendType" SG_ 1548 GDNSTSW 3;
BA_ "GenSigSendType" SG_ 1548 GDNSNSW 3;
BA_ "GenSigSendType" SG_ 1548 RCPMCTSW 3;
BA_ "GenSigSendType" SG_ 1548 NPCS4SW 3;
BA_ "GenSigSendType" SG_ 1548 NPCS5SW 3;
BA_ "GenSigSendType" SG_ 1548 NPCS6SW 3;
BA_ "GenSigSendType" SG_ 1548 NPCS7SW 3;
BA_ "GenSigSendType" SG_ 1548 NPCS8SW 3;
BA_ "GenSigSendType" SG_ 1548 NPCS9SW 3;
BA_ "GenSigSendType" SG_ 1548 NPCS10SW 3;
BA_ "GenSigSendType" SG_ 1548 NPCS11SW 3;
BA_ "GenSigSendType" SG_ 1548 NPCS12SW 3;
BA_ "GenSigSendType" SG_ 1548 NPCS13SW 3;
BA_ "GenSigSendType" SG_ 1548 NPCS14SW 3;
BA_ "GenSigSendType" SG_ 1548 NPCS15SW 3;
BA_ "GenSigSendType" SG_ 1548 NPCS16SW 3;
BA_ "GenSigSendType" SG_ 1548 NPCS17SW 3;
BA_ "GenSigSendType" SG_ 1548 NPCS18SW 3;
BA_ "GenSigSendType" SG_ 1548 NPCS19SW 3;
BA_ "GenSigSendType" SG_ 1548 NPCS20SW 3;
BA_ "GenSigSendType" SG_ 1548 ESSCTSW 3;
BA_ "GenSigSendType" SG_ 739 GRLGDBOP 3;
BA_ "GenSigStartValue" SG_ 532 TBMAX_GR 21;
BA_ "GenSigStartValue" SG_ 532 TBMIN_GR 21;
BA_ "GenSigStartValue" SG_ 366 BIB_G 32767;
BA_ "GenSigStartValue" SG_ 366 VCELMAXG 3047;
BA_ "GenSigStartValue" SG_ 366 VCELMING 3047;
BA_ "GenSigStartValue" SG_ 366 TC_G 25;
BA_ "GenSigSendType" SG_ 997 BHEATSW 3;
BA_ "GenSigSendType" SG_ 997 BCOOLSW 3;
BA_ "GenSigSendType" SG_ 997 LBTYPE_E 3;
BA_ "GenSigStartValue" SG_ 292 BTWO 150;
BA_ "GenSigStartValue" SG_ 341 BSOHDST 65535;
BA_ "GenSigSendType" SG_ 889 RM_DISP 3;
BA_ "GenSigSendType" SG_ 889 MAV_ERR 3;
BA_ "GenSigSendType" SG_ 889 MAV_BP_S 3;
BA_ "GenSigSendType" SG_ 889 MAV_BP_L 3;
BA_ "GenSigSendType" SG_ 889 ENBLMMSW 3;
BA_ "GenSigSendType" SG_ 889 MAVTYPE 3;
BA_ "GenSigSendType" SG_ 889 R_CROP_0 3;
BA_ "GenSigSendType" SG_ 907 SALR 3;
BA_ "GenSigSendType" SG_ 907 HDCY_BDB 3;
BA_ "GenSigSendType" SG_ 907 ALM_EQ 3;
BA_ "GenSigSendType" SG_ 907 AARE_B 3;
BA_ "GenSigSendType" SG_ 907 INTSET_B 3;
BA_ "GenSigSendType" SG_ 907 INCSET_B 3;
BA_ "GenSigSendType" SG_ 907 INT_EQ 3;
BA_ "GenSigSendType" SG_ 907 ISSD_BDB 3;
BA_ "GenSigSendType" SG_ 909 DPM_R1 3;
BA_ "GenSigSendType" SG_ 909 DPM_R2 3;
BA_ "GenSigSendType" SG_ 909 DPM_R3 3;
BA_ "GenSigSendType" SG_ 909 DPP_R1 3;
BA_ "GenSigSendType" SG_ 909 DPP_R2 3;
BA_ "GenSigSendType" SG_ 909 DPP_R3 3;
BA_ "GenSigSendType" SG_ 909 DPMS_INT 3;
BA_ "GenSigSendType" SG_ 909 DPM1_FNC 3;
BA_ "GenSigSendType" SG_ 909 DPM1_VLD 3;
BA_ "GenSigSendType" SG_ 909 DPS1_VLD 3;
BA_ "GenSigSendType" SG_ 909 DPM2_FNC 3;
BA_ "GenSigSendType" SG_ 909 DPM2_VLD 3;
BA_ "GenSigSendType" SG_ 909 DPS2_VLD 3;
BA_ "GenSigSendType" SG_ 909 DPM3_FNC 3;
BA_ "GenSigSendType" SG_ 909 DPM3_VLD 3;
BA_ "GenSigSendType" SG_ 909 DPS3_VLD 3;
BA_ "GenSigSendType" SG_ 909 DRVPS_DT 3;
BA_ "GenSigSendType" SG_ 909 HUD_R 3;
BA_ "GenSigStartValue" SG_ 500 TRIP_CNT 65535;
BA_ "GenSigStartValue" SG_ 500 TIME_CNT 16777215;
BA_ "GenSigSendType" SG_ 463 RCOSW 3;
BA_ "GenSigStartValue" SG_ 463 RCOSW 2;
BA_ "GenSigSendType" SG_ 463 RROSW 3;
BA_ "GenSigStartValue" SG_ 463 RROSW 2;
BA_ "GenSigSendType" SG_ 463 RLOSW 3;
BA_ "GenSigStartValue" SG_ 463 RLOSW 2;
BA_ "GenSigSendType" SG_ 463 POSW 3;
BA_ "GenSigStartValue" SG_ 463 POSW 2;
BA_ "GenSigSendType" SG_ 463 ADIM 3;
BA_ "GenSigSendType" SG_ 463 DCTY 3;
BA_ "GenSigSendType" SG_ 463 PCTY 3;
BA_ "GenSigSendType" SG_ 463 RRCY 3;
BA_ "GenSigSendType" SG_ 463 RLCY 3;
BA_ "GenSigSendType" SG_ 463 BCTY 3;
BA_ "GenSigSendType" SG_ 463 LGCY 3;
BA_ "GenSigSendType" SG_ 463 PKB_BDB 3;
BA_ "GenSigSendType" SG_ 463 SREXIST 3;
BA_ "GenSigSendType" SG_ 463 SRPOS 3;
